VERSION ""

NS_ :

BS_:
BU_: GW EPS IBCU mADC BDC
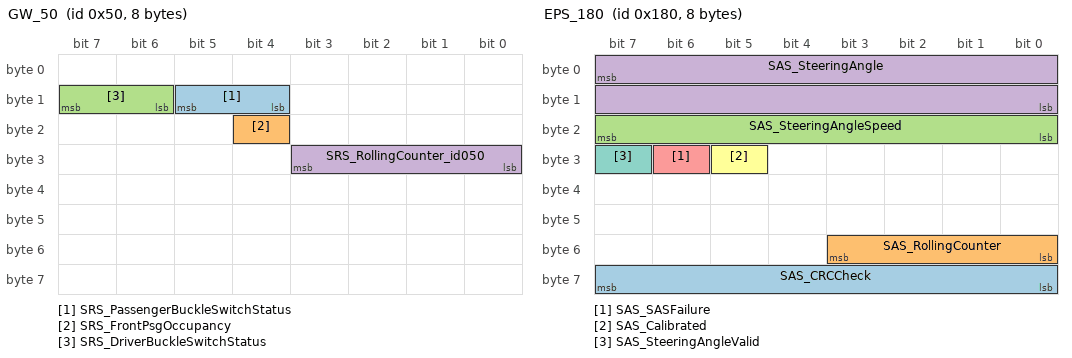
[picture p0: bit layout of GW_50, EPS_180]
BO_ 80 GW_50: 8 GW
 SG_ SRS_PassengerBuckleSwitchStatus : 13|2@0+ (1.0000000000,0.0000000000) [0.0000000000|3.0000000000] ""  EPB,VMC,IBCU
 SG_ SRS_FrontPsgOccupancy : 20|1@0+ (1.0000000000,0.0000000000) [0.0000000000|1.0000000000] ""  IBCU
 SG_ SRS_DriverBuckleSwitchStatus : 15|2@0+ (1.0000000000,0.0000000000) [0.0000000000|3.0000000000] ""  EPBi,IBCU,EPB,RBM,VMC
 SG_ SRS_RollingCounter_id050 : 27|4@0+ (1.0000000000,0.0000000000) [0.0000000000|15.0000000000] ""  EPBi,IBCU,EPB,RBM,VMC

BO_ 384 EPS_180: 8 EPS
 SG_ SAS_CRCCheck : 63|8@0+ (1.0000000000,0.0000000000) [0.0000000000|255.0000000000] ""  EPBi,IBCU,GW,VMC
 SG_ SAS_RollingCounter : 51|4@0+ (1.0000000000,0.0000000000) [0.0000000000|15.0000000000] ""  EPBi,IBCU,GW,VMC
 SG_ SAS_SteeringAngleSpeed : 23|8@0+ (4.0000000000,0.0000000000) [0.0000000000|1016.0000000000] "deg/s"  EPBi,IBCU,GW,VMC
 SG_ SAS_SteeringAngle : 7|16@0- (0.1000000000,0.0000000000) [-780.0000000000|780.0000000000] "degree"  EPBi,IBCU,GW,VMC,BDC
 SG_ SAS_SASFailure : 30|1@0+ (1.0000000000,0.0000000000) [0.0000000000|1.0000000000] ""  EPBi,IBCU,GW
 SG_ SAS_Calibrated : 29|1@0+ (1.0000000000,0.0000000000) [0.0000000000|1.0000000000] ""  EPBi,IBCU,GW,VMC
 SG_ SAS_SteeringAngleValid : 31|1@0+ (1.0000000000,0.0000000000) [0.0000000000|1.0000000000] ""  EPBi,IBCU,GW,VMC

BO_ 997 GW_3E5: 8 GW

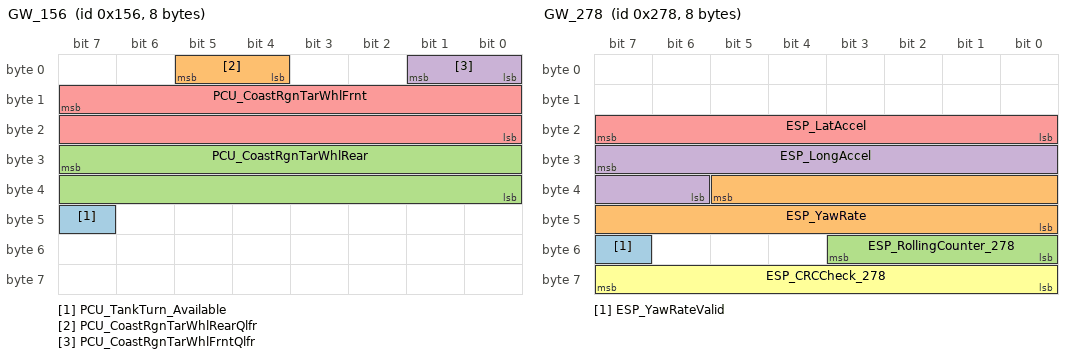
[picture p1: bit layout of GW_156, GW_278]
BO_ 342 GW_156: 8 GW
 SG_ PCU_TankTurn_Available : 47|1@0+ (1.0000000000,0.0000000000) [0.0000000000|1.0000000000] ""  IBCU
 SG_ PCU_CoastRgnTarWhlRearQlfr : 5|2@0+ (1.0000000000,0.0000000000) [0.0000000000|2.0000000000] ""  IBCU
 SG_ PCU_CoastRgnTarWhlRear : 31|16@0+ (1.0000000000,-32768.0000000000) [-32768.0000000000|32767.0000000000] "Nm"  IBCU
 SG_ PCU_CoastRgnTarWhlFrntQlfr : 1|2@0+ (1.0000000000,0.0000000000) [0.0000000000|2.0000000000] "-"  IBCU
 SG_ PCU_CoastRgnTarWhlFrnt : 15|16@0+ (1.0000000000,-32768.0000000000) [-32768.0000000000|32767.0000000000] "Nm"  IBCU

BO_ 580 GW_244: 64 GW
 SG_ ACC_AEBSpeedDropLevel : 162|2@0+ (1.0000000000,0.0000000000) [0.0000000000|3.0000000000] ""  IBCU,EPBi
 SG_ ADS__RollingCounter_244 : 427|4@0+ (1.0000000000,0.0000000000) [0.0000000000|15.0000000000] ""  EPS,EPBi,EPB,IBCU,VMC
 SG_ ADS_CRCCheck_244 : 439|16@0+ (1.0000000000,0.0000000000) [0.0000000000|65535.0000000000] ""  EPS,EPBi,EPB,IBCU,VMC
 SG_ ADS_Authernticator_244 : 463|56@0+ (1.0000000000,0.0000000000) [0.0000000000|0.0000000000] ""  IBCU
 SG_ ADS_ResetFlag_244 : 449|2@0+ (1.0000000000,0.0000000000) [0.0000000000|3.0000000000] ""  IBCU
 SG_ ADS_MesssageCounter_244 : 455|6@0+ (1.0000000000,0.0000000000) [0.0000000000|63.0000000000] ""  IBCU
 SG_ ACC_CRCCheck_25E : 127|8@0+ (1.0000000000,0.0000000000) [0.0000000000|255.0000000000] ""  EPBi,IBCU,RBM
 SG_ ACC_RollingCounter_25E : 115|4@0+ (1.0000000000,0.0000000000) [0.0000000000|15.0000000000] ""  EPBi,IBCU,RBM
 SG_ ACC_AEBCtrlType : 104|4@0+ (1.0000000000,0.0000000000) [0.0000000000|15.0000000000] ""  EPBi,IBCU
 SG_ ACC_AEBVehilceHoldReq : 90|1@0+ (1.0000000000,0.0000000000) [0.0000000000|1.0000000000] ""  EPBi,IBCU
 SG_ ACC_FCWActive : 93|1@0+ (1.0000000000,0.0000000000) [0.0000000000|1.0000000000] ""  IBCU,RBM
 SG_ ACC_PrefillActive : 94|1@0+ (1.0000000000,0.0000000000) [0.0000000000|1.0000000000] ""  EPBi,IBCU
 SG_ ACC_AWBActive : 95|1@0+ (1.0000000000,0.0000000000) [0.0000000000|1.0000000000] ""  EPBi,IBCU
 SG_ ACC_AWBlevel : 83|4@0+ (1.0000000000,0.0000000000) [0.0000000000|15.0000000000] ""  EPBi,IBCU
 SG_ ACC_ABAActive : 84|1@0+ (1.0000000000,0.0000000000) [0.0000000000|1.0000000000] ""  EPBi,IBCU
 SG_ ACC_ABAlevel : 86|2@0+ (1.0000000000,0.0000000000) [0.0000000000|3.0000000000] ""  EPBi,IBCU
 SG_ ACC_AEBActive : 87|1@0+ (1.0000000000,0.0000000000) [0.0000000000|1.0000000000] ""  EPBi,IBCU,RBM,VMC
 SG_ ACC_AEBTargetDeceleration : 71|16@0+ (0.0005000000,-16.0000000000) [-16.0000000000|16.0000000000] "m/s2"  EPBi,IBCU
 SG_ ACC_CRCCheck_24E : 63|8@0+ (1.0000000000,0.0000000000) [0.0000000000|255.0000000000] ""  EPBi,IBCU,RBM
 SG_ ACC_RollingCounter_24E : 51|4@0+ (1.0000000000,0.0000000000) [0.0000000000|15.0000000000] ""  EPBi,IBCU,RBM
 SG_ ACC_Driveoff_Request : 55|1@0+ (1.0000000000,0.0000000000) [0.0000000000|1.0000000000] ""  EPBi,IBCU,RBM
 SG_ ACC_ACCMode : 54|3@0+ (1.0000000000,0.0000000000) [0.0000000000|7.0000000000] ""  EPBi,IBCU,EPB,RBM,VMC
 SG_ ACC_CDDActive : 44|1@0+ (1.0000000000,0.0000000000) [0.0000000000|1.0000000000] ""  EPBi,IBCU,RBM
 SG_ ACC_EngineStartStopRequest : 41|2@0+ (1.0000000000,0.0000000000) [0.0000000000|3.0000000000] ""  IBCU,RBM
 SG_ ACC_DecToStop : 31|1@0+ (1.0000000000,0.0000000000) [0.0000000000|1.0000000000] ""  EPBi,IBCU,RBM
 SG_ ACC_ACCTargetAcceleration : 7|8@0+ (0.0500000000,-10.0000000000) [-10.0000000000|2.7500000000] "m/s2"  EPBi,IBCU,RBM

BO_ 583 GW_247: 32 GW
 SG_ APA_PrecheckValid : 99|1@0+ (1.0000000000,0.0000000000) [0.0000000000|1.0000000000] ""  IBCU
 SG_ APA_Precheck : 96|1@0+ (1.0000000000,0.0000000000) [0.0000000000|1.0000000000] ""  IBCU
 SG_ APA_ESP_BrakeFunctionMode : 238|3@0+ (1.0000000000,0.0000000000) [0.0000000000|7.0000000000] ""  IBCU,EPB,EPBi
 SG_ APA_CRCCheck_247 : 247|16@0+ (1.0000000000,0.0000000000) [0.0000000000|65535.0000000000] ""  EPBi,EPB,IBCU,EPS
 SG_ APA_RollingCounter_247 : 235|4@0+ (1.0000000000,0.0000000000) [0.0000000000|15.0000000000] ""  EPBi,EPB,IBCU,EPS
 SG_ APA_IncreasePressureReq : 27|1@0+ (1.0000000000,0.0000000000) [0.0000000000|1.0000000000] ""  EPBi,IBCU
 SG_ APA_EmergenceBrake : 7|1@0+ (1.0000000000,0.0000000000) [0.0000000000|1.0000000000] ""  EPBi,IBCU
 SG_ APA_HSAHDforbidden : 92|1@0+ (1.0000000000,0.0000000000) [0.0000000000|1.0000000000] ""  EPBi,IBCU
 SG_ APA_ESPDecompressionModel : 98|1@0+ (1.0000000000,0.0000000000) [0.0000000000|1.0000000000] ""  EPBi,IBCU
 SG_ APA_PrefillReq : 104|1@0+ (1.0000000000,0.0000000000) [0.0000000000|1.0000000000] ""  EPBi,IBCU
 SG_ APA_LSCAction : 91|1@0+ (1.0000000000,0.0000000000) [0.0000000000|1.0000000000] ""  EPBi,IBCU,VMC
 SG_ APA_TargetAcceleration : 79|8@0+ (0.0500000000,-5.0000000000) [-5.0000000000|7.7500000000] "m/s2"  EPBi,IBCU
 SG_ APA_TargetAccelerationValid : 67|1@0+ (1.0000000000,0.0000000000) [0.0000000000|1.0000000000] "NA"  EPBi,IBCU
 SG_ APA_EPBrequestValid : 66|1@0+ (1.0000000000,0.0000000000) [0.0000000000|1.0000000000] ""  EPBi,EPB,IBCU,VMC
 SG_ APA_EPBrequest : 65|2@0+ (1.0000000000,0.0000000000) [0.0000000000|3.0000000000] ""  EPBi,EPB,IBCU,VMC

BO_ 632 GW_278: 8 GW
 SG_ ESP_YawRateValid : 55|1@0+ (1.0000000000,0.0000000000) [0.0000000000|1.0000000000] ""  EPBi,EPS,IBCU
 SG_ ESP_YawRate : 37|14@0+ (0.0100000000,-81.9100000000) [-81.9100000000|81.9100000000] "degree/s"  EPBi,EPS,IBCU
 SG_ ESP_RollingCounter_278 : 51|4@0+ (1.0000000000,0.0000000000) [0.0000000000|15.0000000000] ""  EPBi,EPS,IBCU
 SG_ ESP_LongAccel : 31|10@0+ (0.0312500000,-16.0000000000) [-16.0000000000|15.9062500000] "m/s2"  EPBi,IBCU,BDC
 SG_ ESP_LatAccel : 23|8@0+ (0.1000000000,-12.7000000000) [-12.7000000000|12.7000000000] "m/s2"  EPBi,EPS,IBCU
 SG_ ESP_CRCCheck_278 : 63|8@0+ (1.0000000000,0.0000000000) [0.0000000000|255.0000000000] ""  EPBi,EPS,IBCU

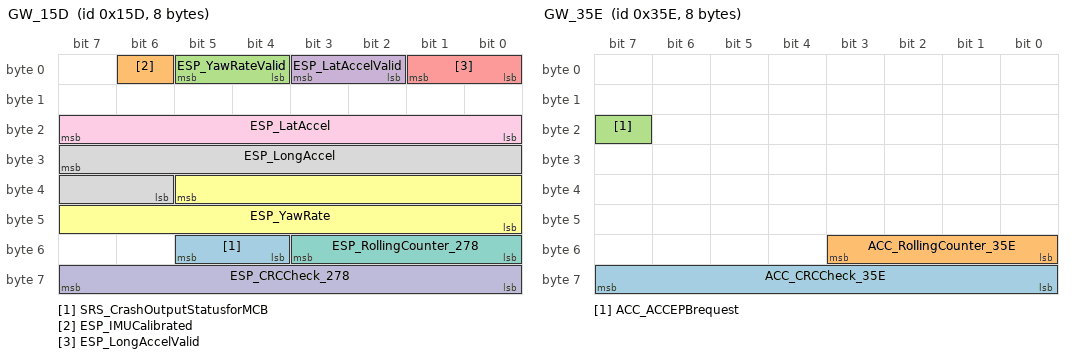
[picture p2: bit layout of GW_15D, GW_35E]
BO_ 349 GW_15D: 8 GW
 SG_ SRS_CrashOutputStatusforMCB : 53|2@0+ (1.0000000000,0.0000000000) [0.0000000000|3.0000000000] ""  EPBi,IBCU
 SG_ ESP_IMUCalibrated : 6|1@0+ (1.0000000000,0.0000000000) [0.0000000000|1.0000000000] ""  VMC,IBCU,RBM
 SG_ ESP_YawRateValid : 5|2@0+ (1.0000000000,0.0000000000) [0.0000000000|3.0000000000] ""  VMC,IBCU,EPB,RBM
 SG_ ESP_LatAccelValid : 3|2@0+ (1.0000000000,0.0000000000) [0.0000000000|3.0000000000] ""  IBCU,RBM,EPB,VMC
 SG_ ESP_LongAccelValid : 1|2@0+ (1.0000000000,0.0000000000) [0.0000000000|3.0000000000] ""  IBCU,RBM,EPB,VMC
 SG_ ESP_YawRate : 37|14@0+ (0.0100000000,-81.9100000000) [-81.9100000000|81.9100000000] "degree/s"  VMC,IBCU,EPB,RBM
 SG_ ESP_RollingCounter_278 : 51|4@0+ (1.0000000000,0.0000000000) [0.0000000000|15.0000000000] ""  IBCU,RBM,EPB,VMC
 SG_ ESP_LongAccel : 31|10@0+ (0.0312500000,-16.0000000000) [-16.0000000000|15.9062500000] "m/s2"  VMC,IBCU,EPB,RBM
 SG_ ESP_LatAccel : 23|8@0+ (0.1000000000,-12.7000000000) [-12.7000000000|12.7000000000] "m/s2"  VMC,IBCU,EPB,RBM
 SG_ ESP_CRCCheck_278 : 63|8@0+ (1.0000000000,0.0000000000) [0.0000000000|255.0000000000] ""  IBCU,RBM,EPB,VMC

BO_ 862 GW_35E: 8 GW
 SG_ ACC_CRCCheck_35E : 63|8@0+ (1.0000000000,0.0000000000) [0.0000000000|255.0000000000] ""  EPBi,IBCU,EPB,VMC,VMC2
 SG_ ACC_RollingCounter_35E : 51|4@0+ (1.0000000000,0.0000000000) [0.0000000000|15.0000000000] ""  EPBi,IBCU,EPB,VMC,VMC2
 SG_ ACC_ACCEPBrequest : 23|1@0+ (1.0000000000,0.0000000000) [0.0000000000|1.0000000000] ""  EPBi,IBCU,EPB,VMC,VMC2

BO_ 823 IBCU_337: 32 IBCU
 SG_ PowercycleIBCU : 215|16@0+ (1.0000000000,0.0000000000) [0.0000000000|65535.0000000000] "NA"  GW
 SG_ VoltageVR : 207|8@0+ (0.1000000000,0.0000000000) [0.0000000000|25.5000000000] "V"  GW
 SG_ VoltageUB : 199|8@0+ (0.1000000000,0.0000000000) [0.0000000000|25.5000000000] "V"  GW
 SG_ ESP_EpbReqAvl : 66|1@0+ (1.0000000000,0.0000000000) [0.0000000000|1.0000000000] ""  GW
 SG_ IBCU_BrkSysFltLamp : 15|2@0+ (1.0000000000,0.0000000000) [0.0000000000|3.0000000000] ""  RBM,GW
 SG_ ESC_ATSReqEnable : 69|1@0+ (1.0000000000,0.0000000000) [0.0000000000|1.0000000000] ""  GW
 SG_ ESC_ATSDrivingModeStatus : 76|3@0+ (1.0000000000,0.0000000000) [0.0000000000|6.0000000000] ""  GW
 SG_ ESP_RollerbenchEnable : 55|1@0+ (1.0000000000,0.0000000000) [0.0000000000|1.0000000000] ""  EPBi,GW
 SG_ ESP_WheelSpdSensorError : 145|1@0+ (1.0000000000,0.0000000000) [0.0000000000|1.0000000000] ""  EPBi,GW
 SG_ ESP_WheelSpdSensorEcuError : 144|1@0+ (1.0000000000,0.0000000000) [0.0000000000|1.0000000000] ""  EPBi,GW
 SG_ ESP_VGH_Status : 54|2@0+ (1.0000000000,0.0000000000) [0.0000000000|3.0000000000] ""  EPBi,GW
 SG_ ESP_VGH_Available : 52|1@0+ (1.0000000000,0.0000000000) [0.0000000000|1.0000000000] ""  EPBi,GW
 SG_ ESP_TPMSresetstatus : 85|3@0+ (1.0000000000,0.0000000000) [0.0000000000|7.0000000000] ""  EPBi,GW
 SG_ ESP_TPMS_WarningStatus : 86|1@0+ (1.0000000000,0.0000000000) [0.0000000000|1.0000000000] ""  EPBi,GW
 SG_ ESP_TPMS_MalfunctionStatus : 87|1@0+ (1.0000000000,0.0000000000) [0.0000000000|1.0000000000] ""  EPBi,GW
 SG_ ESP_RRWheelSpdSensorSigFailure : 146|1@0+ (1.0000000000,0.0000000000) [0.0000000000|1.0000000000] ""  EPBi,GW
 SG_ ESP_RRWheelSpdSensorFailure : 136|1@0+ (1.0000000000,0.0000000000) [0.0000000000|1.0000000000] ""  EPBi,GW
 SG_ ESP_RRWheelSpdSensor_ShtBAT : 148|1@0+ (1.0000000000,0.0000000000) [0.0000000000|1.0000000000] ""  EPBi,GW
 SG_ ESP_RRWheelSpdSensor_Open : 147|1@0+ (1.0000000000,0.0000000000) [0.0000000000|1.0000000000] ""  EPBi,GW
 SG_ ESP_RRWheelSpdSensor_GND : 149|1@0+ (1.0000000000,0.0000000000) [0.0000000000|1.0000000000] ""  EPBi,GW
 SG_ ESP_RollingCounter_508 : 179|4@0+ (1.0000000000,0.0000000000) [0.0000000000|15.0000000000] ""  EPBi,GW
 SG_ ESP_RLWheelSpdSensorSigFailure : 137|1@0+ (1.0000000000,0.0000000000) [0.0000000000|1.0000000000] ""  EPBi,GW
 SG_ ESP_RLWheelSpdSensorFailure : 141|1@0+ (1.0000000000,0.0000000000) [0.0000000000|1.0000000000] ""  EPBi,GW
 SG_ ESP_RLWheelSpdSensor_ShtBAT : 139|1@0+ (1.0000000000,0.0000000000) [0.0000000000|1.0000000000] ""  EPBi,GW
 SG_ ESP_RLWheelSpdSensor_Open : 138|1@0+ (1.0000000000,0.0000000000) [0.0000000000|1.0000000000] ""  EPBi,GW
 SG_ ESP_RLWheelSpdSensor_GND : 140|1@0+ (1.0000000000,0.0000000000) [0.0000000000|1.0000000000] ""  EPBi,GW
 SG_ ESP_RearRghtWheelStatus : 78|2@0+ (1.0000000000,0.0000000000) [0.0000000000|3.0000000000] ""  EPBi,GW
 SG_ ESP_RearLeftWheelStatus : 65|2@0+ (1.0000000000,0.0000000000) [0.0000000000|3.0000000000] ""  EPBi,GW
 SG_ EPBi_ResetSts : 82|3@0+ (1.0000000000,0.0000000000) [0.0000000000|7.0000000000] ""  EPBi,GW
 SG_ ESP_FRWheelSpdSensorSigFailure : 142|1@0+ (1.0000000000,0.0000000000) [0.0000000000|1.0000000000] ""  EPBi,GW
 SG_ ESP_FRWheelSpdSensorFailure : 130|1@0+ (1.0000000000,0.0000000000) [0.0000000000|1.0000000000] ""  EPBi,GW
 SG_ ESP_FRWheelSpdSensor_ShtBAT : 128|1@0+ (1.0000000000,0.0000000000) [0.0000000000|1.0000000000] ""  EPBi,GW
 SG_ ESP_FRWheelSpdSensor_Open : 143|1@0+ (1.0000000000,0.0000000000) [0.0000000000|1.0000000000] ""  EPBi,GW
 SG_ ESP_FRWheelSpdSensor_GND : 129|1@0+ (1.0000000000,0.0000000000) [0.0000000000|1.0000000000] ""  EPBi,GW
 SG_ ESP_FrontRightWheelStatus : 68|2@0+ (1.0000000000,0.0000000000) [0.0000000000|3.0000000000] ""  EPBi,GW
 SG_ ESP_FrontLeftWheelStatus : 71|2@0+ (1.0000000000,0.0000000000) [0.0000000000|3.0000000000] ""  EPBi,GW
 SG_ ESP_FLWheelSpdSensorSigFailure : 131|1@0+ (1.0000000000,0.0000000000) [0.0000000000|1.0000000000] ""  EPBi,GW
 SG_ ESP_FLWheelSpdSensorFailure : 135|1@0+ (1.0000000000,0.0000000000) [0.0000000000|1.0000000000] ""  EPBi,GW
 SG_ ESP_FLWheelSpdSensor_ShtBAT : 133|1@0+ (1.0000000000,0.0000000000) [0.0000000000|1.0000000000] ""  EPBi,GW
 SG_ ESP_FLWheelSpdSensor_Open : 132|1@0+ (1.0000000000,0.0000000000) [0.0000000000|1.0000000000] ""  EPBi,GW
 SG_ ESP_FLWheelSpdSensor_GND : 134|1@0+ (1.0000000000,0.0000000000) [0.0000000000|1.0000000000] ""  EPBi,GW
 SG_ ESP_CRCCheck_508 : 191|8@0+ (1.0000000000,0.0000000000) [0.0000000000|255.0000000000] ""  EPBi,GW
 SG_ IBCU_CST_FunctionSwitch : 27|2@0+ (1.0000000000,0.0000000000) [0.0000000000|3.0000000000] ""  GW
 SG_ ESP_AWD_ModeRequest : 30|3@0+ (1.0000000000,0.0000000000) [0.0000000000|7.0000000000] ""  EPBi,GW
 SG_ ESP_ATS_PtrotectMode : 31|1@0+ (1.0000000000,0.0000000000) [0.0000000000|1.0000000000] ""  EPBi,GW
 SG_ ESP_ATS_ATB_Failure : 16|1@0+ (1.0000000000,0.0000000000) [0.0000000000|1.0000000000] ""  EPBi,GW
 SG_ ESP_ATS_EPBi_Failure : 17|1@0+ (1.0000000000,0.0000000000) [0.0000000000|1.0000000000] ""  EPBi,GW
 SG_ ESP_ATS_AWD_Failure : 18|1@0+ (1.0000000000,0.0000000000) [0.0000000000|1.0000000000] ""  EPBi,GW
 SG_ ESP_ATS_TCU_Failure : 19|1@0+ (1.0000000000,0.0000000000) [0.0000000000|1.0000000000] ""  EPBi,GW
 SG_ ESP_ATS_EMS_Failure : 20|1@0+ (1.0000000000,0.0000000000) [0.0000000000|1.0000000000] ""  EPBi,GW
 SG_ EPB_CRCCheck_34F : 63|8@0+ (1.0000000000,0.0000000000) [0.0000000000|255.0000000000] ""  EPBi,GW
 SG_ EPB_RollingCounter_34F : 51|4@0+ (1.0000000000,0.0000000000) [0.0000000000|15.0000000000] ""  EPBi,GW
 SG_ ESC_ATSReqEnable : 21|1@0+ (1.0000000000,0.0000000000) [0.0000000000|1.0000000000] ""  EPBi,GW
 SG_ ESP_ATS_DriveModeRequest : 13|4@0+ (1.0000000000,0.0000000000) [0.0000000000|15.0000000000] ""  EPBi,GW
 SG_ ESC_ATSDrivingModeStatus : 9|4@0+ (1.0000000000,0.0000000000) [0.0000000000|15.0000000000] ""  EPBi,GW

BO_ 870 GW_366: 8 GW
 SG_ AC_EnvironmentalTemp : 23|8@0+ (0.5000000000,-40.0000000000) [-40.0000000000|87.0000000000] "degreeC"  EPBi,EPB,IBCU,VMC
 SG_ AC_EnvironmentalTempVD : 8|1@0+ (1.0000000000,0.0000000000) [0.0000000000|1.0000000000] ""  EPBi,IBCU

BO_ 1302 GW_516: 32 GW
 SG_ HU_RollerbenchSetStaus : 103|2@0+ (1.0000000000,0.0000000000) [0.0000000000|3.0000000000] ""  EPBi,IBCU
 SG_ HU_LocalTimeSystem : 111|2@0+ (1.0000000000,0.0000000000) [0.0000000000|3.0000000000] ""  EPS,EPBi,IBCU
 SG_ HU_LocalTimeSecond : 109|6@0+ (1.0000000000,0.0000000000) [0.0000000000|59.0000000000] "second"  EPS,EPBi,IBCU,EPB,VMC
 SG_ HU_LocalTimeMinute : 101|6@0+ (1.0000000000,0.0000000000) [0.0000000000|59.0000000000] "minute"  EPS,EPBi,IBCU,EPB,VMC
 SG_ HU_LocalTimeHour : 92|5@0+ (1.0000000000,0.0000000000) [0.0000000000|23.0000000000] "hour"  EPS,EPBi,IBCU,EPB,VMC
 SG_ HU_LocalTimeDate : 84|5@0+ (1.0000000000,0.0000000000) [1.0000000000|31.0000000000] "day"  EPS,EPBi,IBCU,EPB,VMC
 SG_ HU_LocalTimeYear : 119|8@0+ (1.0000000000,2013.0000000000) [2013.0000000000|2268.0000000000] "year"  EPS,EPBi,IBCU,EPB,VMC
 SG_ HU_LocalTimeMonth : 75|4@0+ (1.0000000000,0.0000000000) [1.0000000000|12.0000000000] "month"  EPS,EPBi,IBCU,EPB,VMC
 SG_ HU_LocalTimeValid : 71|1@0+ (1.0000000000,0.0000000000) [0.0000000000|1.0000000000] ""  EPS,EPBi,IBCU,EPB,VMC

BO_ 1328 GW_530: 8 GW
 SG_ IP_TotalOdometer : 23|24@0+ (0.1000000000,0.0000000000) [0.0000000000|999999.0000000000] "Km"  EPBi,EPB,IBCU
 SG_ IP_EngineOffTime : 7|16@0+ (1.0000000000,0.0000000000) [0.0000000000|65535.0000000000] "s"  EPBi,IBCU

BO_ 378 IBCU_17A: 64 IBCU
 SG_ IBCU_MCB_availalbe : 181|1@0+ (1.0000000000,0.0000000000) [0.0000000000|1.0000000000] ""  EPBi,GW
 SG_ IBCU_MCB_Active : 182|1@0+ (1.0000000000,0.0000000000) [0.0000000000|1.0000000000] ""  EPBi,GW
 SG_ ESP_TankTurn_EngTorqIncRearActive : 457|1@0+ (1.0000000000,0.0000000000) [0.0000000000|1.0000000000] ""  GW
 SG_ ESP_TankTurn_TorqIncwhlRear : 456|15@0+ (1.0000000000,-5400.0000000000) [-5400.0000000000|12000.0000000000] "Nm"  GW
 SG_ ESP_TankTurn_EngTorqIncFrontActive : 277|1@0+ (1.0000000000,0.0000000000) [0.0000000000|1.0000000000] ""  GW
 SG_ ESP_TankTurn_TorqIncwhlFront : 276|15@0+ (1.0000000000,-5400.0000000000) [-5400.0000000000|12000.0000000000] "Nm"  GW
 SG_ IBCU_TankTurn_Status : 93|2@0+ (1.0000000000,0.0000000000) [0.0000000000|3.0000000000] ""  GW
 SG_ IBCU_BrkPedlTrvlDrvrVld : 473|2@0+ (1.0000000000,0.0000000000) [0.0000000000|2.0000000000] ""  GW
 SG_ IBCU_BrkPedlTrvlDrvr : 487|12@0+ (0.0156250000,-5.0000000000) [-5.0000000000|47.0000000000] "mm"  GW
 SG_ Wheel_Speed_RR_Data : 351|13@0+ (0.0562500000,0.0000000000) [0.0000000000|360.0000000000] "km/h"  GW
 SG_ Wheel_Speed_RL_Valid_Data : 354|1@0+ (1.0000000000,0.0000000000) [0.0000000000|1.0000000000] ""  GW
 SG_ Wheel_Speed_RL_Data : 353|13@0+ (0.0562500000,0.0000000000) [0.0000000000|360.0000000000] "km/h"  GW
 SG_ Wheel_Speed_RR_Valid_Data : 372|1@0+ (1.0000000000,0.0000000000) [0.0000000000|1.0000000000] ""  GW
 SG_ ESP_VDCActive : 245|1@0+ (1.0000000000,0.0000000000) [0.0000000000|1.0000000000] ""  GW
 SG_ ESP_TCSActive : 244|1@0+ (1.0000000000,0.0000000000) [0.0000000000|1.0000000000] ""  GW
 SG_ IBCU_EdcFrntMotTarSpd : 439|16@0+ (1.0000000000,-20000.0000000000) [-20000.0000000000|45535.0000000000] "rpm"  RBM,GW
 SG_ IBCU_EdcReMotTarSpd : 423|16@0+ (1.0000000000,-20000.0000000000) [-20000.0000000000|45535.0000000000] "rpm"  RBM,GW
 SG_ IBCU_TcsFrntMotTarSpd : 407|16@0+ (1.0000000000,-20000.0000000000) [-20000.0000000000|45535.0000000000] "rpm"  RBM,GW
 SG_ IBCU_TcsReMotTarSpd : 391|16@0+ (1.0000000000,-20000.0000000000) [-20000.0000000000|45535.0000000000] "rpm"  RBM,GW
 SG_ ESP_ElectricBoostFailStatus : 54|2@0+ (1.0000000000,0.0000000000) [0.0000000000|3.0000000000] ""  GW
 SG_ ESP_MbRegenTarWhlTotalQlfr : 293|2@0+ (1.0000000000,0.0000000000) [0.0000000000|3.0000000000] ""  GW
 SG_ ESP_MbRegenTarWhlTotal : 291|16@0+ (1.0000000000,-32768.0000000000) [-32768.0000000000|32767.0000000000] "Nm"  GW
 SG_ ESP_RollerbenchType : 80|3@0+ (1.0000000000,0.0000000000) [0.0000000000|7.0000000000] ""  EPBi,GW,VMC
 SG_ IBCU_BrakeFluid_Warning : 27|2@0+ (1.0000000000,0.0000000000) [0.0000000000|3.0000000000] ""  GW
 SG_ ESP_RollingCounter_17A : 491|4@0+ (1.0000000000,0.0000000000) [0.0000000000|15.0000000000] ""  EPBi,EPB,GW,EPS,VMC
 SG_ ESP_CRCCheck_17A : 503|16@0+ (1.0000000000,0.0000000000) [0.0000000000|65535.0000000000] ""  EPBi,EPB,GW,EPS,VMC
 SG_ ESP_VehicleSpeedValid2 : 271|2@0+ (1.0000000000,0.0000000000) [0.0000000000|2.0000000000] ""  GW
 SG_ ESP_VehicleSpeedValid : 37|1@0+ (1.0000000000,0.0000000000) [0.0000000000|1.0000000000] ""  EPBi,EPB,GW,EPS,VMC,TMS,BDC,VMC2,EPS2,EPBi2
 SG_ ESP_VehicleSpeed2 : 263|8@0+ (0.4000000000,0.0000000000) [0.0000000000|100.0000000000] "m/s"  GW
 SG_ ESP_VehicleSpeed : 36|13@0+ (0.0562500000,0.0000000000) [0.0000000000|360.0000000000] "km/h"  EPBi,EPB,GW,EPS,VMC,TMS,BDC,VMC2,EPS2,EPBi2
 SG_ ESP_TqDecSlowwhlRear : 215|15@0+ (1.0000000000,-5400.0000000000) [-5400.0000000000|12000.0000000000] "Nm"  GW
 SG_ ESP_TqDecSlowwhlFront : 136|15@0+ (1.0000000000,-5400.0000000000) [-5400.0000000000|12000.0000000000] "Nm"  GW
 SG_ ESP_TqDecFastwhlFront : 135|15@0+ (1.0000000000,-5400.0000000000) [-5400.0000000000|12000.0000000000] "Nm"  GW
 SG_ ESP_TorqIncwhlRear : 199|15@0+ (1.0000000000,-5400.0000000000) [-5400.0000000000|12000.0000000000] "Nm"  GW
 SG_ ESP_TorqIncwhlFront : 15|15@0+ (1.0000000000,-5400.0000000000) [-5400.0000000000|12000.0000000000] "Nm"  GW
 SG_ ESP_TCSFailStatus : 4|1@0+ (1.0000000000,0.0000000000) [0.0000000000|1.0000000000] ""  EPBi,GW,BDC
 SG_ ESP_RollingCounter_1DF : 371|4@0+ (1.0000000000,0.0000000000) [0.0000000000|15.0000000000] ""  GW
 SG_ ESP_RollingCounter_1C8 : 243|4@0+ (1.0000000000,0.0000000000) [0.0000000000|15.0000000000] ""  GW
 SG_ ESP_RollingCounter_1AC : 179|4@0+ (1.0000000000,0.0000000000) [0.0000000000|15.0000000000] ""  GW
 SG_ ESP_RollingCounter_197 : 115|4@0+ (1.0000000000,0.0000000000) [0.0000000000|15.0000000000] ""  EPBi,GW,BDC
 SG_ ESP_RollingCounter_187 : 51|4@0+ (1.0000000000,0.0000000000) [0.0000000000|15.0000000000] ""  EPBi,GW,BDC
 SG_ ESP_pMcVirtual_Q : 333|2@0+ (1.0000000000,0.0000000000) [0.0000000000|2.0000000000] ""  EPB,GW,VMC,VMC2
 SG_ ESP_pMcVirtual : 327|10@0+ (1.0000000000,0.0000000000) [0.0000000000|250.0000000000] "bar"  EPB,GW,VMC,VMC2
 SG_ ESP_MbRegenTarWhlRearQlfr : 247|2@0+ (1.0000000000,0.0000000000) [0.0000000000|2.0000000000] ""  GW
 SG_ ESP_MbRegenTarWhlRear : 231|16@0+ (1.0000000000,-32768.0000000000) [-32768.0000000000|0.0000000000] "Nm"  GW
 SG_ ESP_MbRegenTarWhlFrontQlfr : 168|2@0+ (1.0000000000,0.0000000000) [0.0000000000|2.0000000000] ""  GW
 SG_ ESP_MbRegenTarWhlFront : 152|16@0+ (1.0000000000,-32768.0000000000) [-32768.0000000000|32767.0000000000] "Nm"  GW
 SG_ ESP_GearHoldRequestValid : 5|1@0+ (1.0000000000,0.0000000000) [0.0000000000|1.0000000000] ""  EPBi,GW,BDC
 SG_ ESP_GearHoldRequest : 6|1@0+ (1.0000000000,0.0000000000) [0.0000000000|1.0000000000] ""  EPBi,GW,BDC
 SG_ ESP_ESPFunctionStatus : 1|1@0+ (1.0000000000,0.0000000000) [0.0000000000|1.0000000000] ""  EPBi,GW,VMC,BDC
 SG_ ESP_ESPActiveStatus : 0|1@0+ (1.0000000000,0.0000000000) [0.0000000000|1.0000000000] ""  EPBi,EPB,GW,VMC,BDC
 SG_ ESP_EngTorqIncRearActive : 200|1@0+ (1.0000000000,0.0000000000) [0.0000000000|1.0000000000] ""  GW
 SG_ ESP_EngTorqIncFrontActive : 38|1@0+ (1.0000000000,0.0000000000) [0.0000000000|1.0000000000] ""  GW
 SG_ ESP_EngTorqDecRearActive : 216|1@0+ (1.0000000000,0.0000000000) [0.0000000000|1.0000000000] ""  GW
 SG_ ESP_EngTorqDecFrontActive : 153|1@0+ (1.0000000000,0.0000000000) [0.0000000000|1.0000000000] ""  GW
 SG_ ESP_EngTorqDecActive : 39|1@0+ (1.0000000000,0.0000000000) [0.0000000000|1.0000000000] ""  EPBi,GW,BDC
 SG_ ESP_EBDFailStatus : 2|1@0+ (1.0000000000,0.0000000000) [0.0000000000|1.0000000000] ""  EPBi,GW,BDC
 SG_ ESP_CRCCheck_1DF : 383|8@0+ (1.0000000000,0.0000000000) [0.0000000000|255.0000000000] ""  GW
 SG_ ESP_CRCCheck_1C8 : 255|8@0+ (1.0000000000,0.0000000000) [0.0000000000|255.0000000000] ""  GW
 SG_ ESP_CRCCheck_1AC : 191|8@0+ (1.0000000000,0.0000000000) [0.0000000000|255.0000000000] ""  GW
 SG_ ESP_CRCCheck_197 : 127|8@0+ (1.0000000000,0.0000000000) [0.0000000000|255.0000000000] ""  EPBi,ESP,GW,BDC
 SG_ ESP_CRCCheck_187 : 63|8@0+ (1.0000000000,0.0000000000) [0.0000000000|255.0000000000] ""  EPBi,GW,BDC
 SG_ ESP_ABSFailStatus : 3|1@0+ (1.0000000000,0.0000000000) [0.0000000000|1.0000000000] ""  EPBi,GW,BDC
 SG_ ESP_ABSActiveStatus : 7|1@0+ (1.0000000000,0.0000000000) [0.0000000000|1.0000000000] ""  EPBi,GW,BDC
 SG_ EPBi_MILReq : 55|1@0+ (1.0000000000,0.0000000000) [0.0000000000|1.0000000000] ""  GW
 SG_ EPBi_ClearDiagnosticInfo : 25|2@0+ (1.0000000000,0.0000000000) [0.0000000000|3.0000000000] ""  GW
 SG_ EPB_ClutchSensor : 79|7@0+ (1.0000000000,0.0000000000) [0.0000000000|100.0000000000] "%"  EPBi,GW,BDC

BO_ 381 GW_17D: 64 GW
 SG_ PCU_MbRegenWhlTotalVld : 476|1@0+ (1.0000000000,0.0000000000) [0.0000000000|1.0000000000] ""  IBCU
 SG_ PCU_MbRegenWhlTotal : 475|16@0+ (1.0000000000,-32768.0000000000) [-32768.0000000000|32767.0000000000] "Nm"  IBCU
 SG_ PCU_ReWhlReqTqVld : 468|1@0+ (1.0000000000,0.0000000000) [0.0000000000|1.0000000000] ""  VMC,EPB,IBCU
 SG_ PCU_FrntWhlReqTqVld : 469|1@0+ (1.0000000000,0.0000000000) [0.0000000000|1.0000000000] ""  VMC,EPB,IBCU
 SG_ PCU_ReWhlActTqVld : 470|1@0+ (1.0000000000,0.0000000000) [0.0000000000|1.0000000000] ""  VMC,EPB,IBCU
 SG_ PCU_FrntWhlActTqVld : 471|1@0+ (1.0000000000,0.0000000000) [0.0000000000|1.0000000000] ""  VMC,IBCU,EPB,EPS
 SG_ PCU_MbRegenMaxRearWhlVld : 375|1@0+ (1.0000000000,0.0000000000) [0.0000000000|1.0000000000] ""  IBCU
 SG_ PCU_RollingCounter_1C4 : 435|4@0+ (1.0000000000,0.0000000000) [0.0000000000|15.0000000000] ""  IBCU
 SG_ PCU_RearMotSts : 408|1@0+ (1.0000000000,0.0000000000) [0.0000000000|1.0000000000] ""  IBCU
 SG_ PCU_PwrIndcdRealTqRearWhl : 391|15@0+ (1.0000000000,-5400.0000000000) [-5400.0000000000|12000.0000000000] "Nm"  IBCU,EPS,EPB,VMC
 SG_ PCU_PwrIndcdDrvrReqTqWhlRear : 392|15@0+ (1.0000000000,-5400.0000000000) [-5400.0000000000|12000.0000000000] "Nm"  IBCU,EPB,VMC
 SG_ PCU_ESPTqReqAvlRear : 409|1@0+ (1.0000000000,0.0000000000) [0.0000000000|1.0000000000] ""  IBCU
 SG_ PCU_CRCCheck_1C4 : 447|8@0+ (1.0000000000,0.0000000000) [0.0000000000|255.0000000000] ""  IBCU
 SG_ PCU_RollingCounter_1BE : 371|4@0+ (1.0000000000,0.0000000000) [0.0000000000|15.0000000000] ""  IBCU
 SG_ PCU_MbRegenWhlRear : 343|16@0+ (1.0000000000,-32768.0000000000) [-32768.0000000000|32767.0000000000] "Nm"  IBCU
 SG_ PCU_MbRegenMaxWhlTotal : 327|16@0+ (1.0000000000,-32768.0000000000) [-32768.0000000000|32767.0000000000] "Nm"  IBCU
 SG_ PCU_MbRegenMaxRearWhl : 359|16@0+ (1.0000000000,-32768.0000000000) [-32768.0000000000|32767.0000000000] "Nm"  IBCU
 SG_ PCU_CRCCheck_1BE : 383|8@0+ (1.0000000000,0.0000000000) [0.0000000000|255.0000000000] ""  IBCU
 SG_ PCU_PwrTrainSts : 311|2@0+ (1.0000000000,0.0000000000) [0.0000000000|3.0000000000] ""  EPS,EPB,VMC,IBCU
 SG_ PCU_BrkPedlSts : 291|2@0+ (1.0000000000,0.0000000000) [0.0000000000|3.0000000000] ""  IBCU,EPB,VMC
 SG_ PCU_RollingCounter_1A6 : 307|4@0+ (1.0000000000,0.0000000000) [0.0000000000|15.0000000000] ""  IBCU
 SG_ PCU_MbRegenWhlFront : 263|16@0+ (1.0000000000,-32768.0000000000) [-32768.0000000000|32767.0000000000] "Nm"  IBCU
 SG_ PCU_MbRegenMaxWhlQlfr : 293|2@0+ (1.0000000000,0.0000000000) [0.0000000000|2.0000000000] ""  IBCU
 SG_ PCU_MbRegenMaxFrontWhlVld : 294|1@0+ (1.0000000000,0.0000000000) [0.0000000000|1.0000000000] ""  IBCU
 SG_ PCU_MbRegenMaxFrontWhl : 279|16@0+ (1.0000000000,-32768.0000000000) [-32768.0000000000|32767.0000000000] "Nm"  IBCU
 SG_ PCU_CRCCheck_1A6 : 319|8@0+ (1.0000000000,0.0000000000) [0.0000000000|255.0000000000] ""  IBCU
 SG_ PCU_AccPedlVld : 288|1@0+ (1.0000000000,0.0000000000) [0.0000000000|1.0000000000] ""  IBCU,EPB,VMC
 SG_ PCU_AccPedl : 303|8@0+ (0.3920000000,0.0000000000) [0.0000000000|99.9600000000] "pct"  IBCU,EPB,VMC
 SG_ PCU_RollingCounter_211 : 243|4@0+ (1.0000000000,0.0000000000) [0.0000000000|15.0000000000] ""  IBCU
 SG_ PCU_RearMotStsVld : 236|1@0+ (1.0000000000,0.0000000000) [0.0000000000|1.0000000000] ""  IBCU
 SG_ PCU_PwrIndcdRealTqFrontWhl : 199|15@0+ (1.0000000000,-5400.0000000000) [-5400.0000000000|12000.0000000000] "Nm"  IBCU,EPS,EPB,VMC
 SG_ PCU_PwrIndcdDrvrReqTqWhlFront : 200|15@0+ (1.0000000000,-5400.0000000000) [-5400.0000000000|12000.0000000000] "Nm"  IBCU,EPB,VMC
 SG_ PCU_FrontMotStsVld : 239|1@0+ (1.0000000000,0.0000000000) [0.0000000000|1.0000000000] ""  IBCU
 SG_ PCU_FrontMotSts : 217|1@0+ (1.0000000000,0.0000000000) [0.0000000000|1.0000000000] ""  IBCU
 SG_ PCU_ESPTqReqAvlFront : 216|1@0+ (1.0000000000,0.0000000000) [0.0000000000|1.0000000000] ""  IBCU
 SG_ PCU_CRCCheck_211 : 255|8@0+ (1.0000000000,0.0000000000) [0.0000000000|255.0000000000] ""  IBCU
 SG_ PCU_TarGearReqValid : 111|1@0+ (1.0000000000,0.0000000000) [0.0000000000|1.0000000000] ""  IBCU
 SG_ PCU_TarGearReq : 99|4@0+ (1.0000000000,0.0000000000) [0.0000000000|15.0000000000] ""  IBCU
 SG_ PCU_RollingCounter_1C6 : 115|4@0+ (1.0000000000,0.0000000000) [0.0000000000|15.0000000000] ""  IBCU
 SG_ PCU_RealAccPedlVld : 79|1@0+ (1.0000000000,0.0000000000) [0.0000000000|1.0000000000] ""  IBCU,EPB,VMC
 SG_ PCU_RealAccPedl : 71|8@0+ (0.3920000000,0.0000000000) [0.0000000000|99.9600000000] "%"  IBCU,EPB,VMC
 SG_ PCU_CRCCheck_1C6 : 127|8@0+ (1.0000000000,0.0000000000) [0.0000000000|255.0000000000] ""  IBCU

BO_ 459 IBCU_1CB: 32 IBCU
 SG_ IBCU_ElectrodelessBrakeModeFeedBack : 215|8@0+ (1.0000000000,0.0000000000) [0.0000000000|255.0000000000] ""  GW
 SG_ IBCU_ESPTSMAvlSts : 68|1@0+ (1.0000000000,0.0000000000) [0.0000000000|1.0000000000] ""  GW
 SG_ IBCU_ESPTSMAct : 69|1@0+ (1.0000000000,0.0000000000) [0.0000000000|1.0000000000] ""  GW
 SG_ IBCU_EPBrequest : 238|2@0+ (1.0000000000,0.0000000000) [0.0000000000|3.0000000000] ""  EPB,VMC,GW
 SG_ IBCU_EPBrequestValid : 236|1@0+ (1.0000000000,0.0000000000) [0.0000000000|1.0000000000] ""  EPB,VMC,GW
 SG_ WhlPreLeReVld : 180|1@0+ (1.0000000000,0.0000000000) [0.0000000000|1.0000000000] ""  RBM,VMC,GW
 SG_ WhlPreRiReVld : 181|1@0+ (1.0000000000,0.0000000000) [0.0000000000|1.0000000000] ""  RBM,VMC,GW
 SG_ WhlPreLeFrntVld : 182|1@0+ (1.0000000000,0.0000000000) [0.0000000000|1.0000000000] ""  RBM,VMC,GW
 SG_ WhlPreRiFrntVld : 183|1@0+ (1.0000000000,0.0000000000) [0.0000000000|1.0000000000] ""  RBM,VMC,GW
 SG_ WheelPressureRearLeft_Model : 163|12@0+ (0.1000000000,0.0000000000) [0.0000000000|250.0000000000] "bar"  RBM,VMC,GW
 SG_ WheelPressureRearRight_Model : 159|12@0+ (0.1000000000,0.0000000000) [0.0000000000|250.0000000000] "bar"  RBM,VMC,GW
 SG_ WheelPressureFrontLeft_Model : 139|12@0+ (0.1000000000,0.0000000000) [0.0000000000|250.0000000000] "bar"  RBM,VMC,GW
 SG_ WheelPressureFrontRight_Model : 135|12@0+ (0.1000000000,0.0000000000) [0.0000000000|250.0000000000] "bar"  RBM,VMC,GW
 SG_ IBCU_BrkTqReqAvail : 100|1@0+ (1.0000000000,0.0000000000) [0.0000000000|1.0000000000] ""  RBM,GW
 SG_ IBCU_HydBrkActvTq : 199|16@0+ (1.0000000000,-32768.0000000000) [-32768.0000000000|32767.0000000000] "Nm"  RBM,GW
 SG_ IBCU_DrvrBrkReqTqVID : 92|1@0+ (1.0000000000,0.0000000000) [0.0000000000|1.0000000000] ""  RBM,GW
 SG_ IBCU_DrvrBrkReqTq : 99|16@0+ (1.0000000000,-32768.0000000000) [-32768.0000000000|32767.0000000000] "Nm"  RBM,GW
 SG_ IBCU_BrkReqTq : 67|16@0+ (1.0000000000,-32768.0000000000) [-32768.0000000000|32767.0000000000] "Nm"  RBM,GW
 SG_ IBCU_NBrkMode : 103|3@0+ (1.0000000000,0.0000000000) [0.0000000000|7.0000000000] ""  RBM,GW
 SG_ IBCU_System_Status : 7|3@0+ (1.0000000000,0.0000000000) [0.0000000000|7.0000000000] ""  RBM,GW
 SG_ IBCU_RollingCounter_1CB : 235|4@0+ (1.0000000000,0.0000000000) [0.0000000000|15.0000000000] ""  GW,ESP
 SG_ IBCU_CRCCheck_1CB : 247|16@0+ (1.0000000000,0.0000000000) [0.0000000000|65535.0000000000] ""  GW,ESP
 SG_ IBCU_CST_Status : 71|2@0+ (1.0000000000,0.0000000000) [0.0000000000|3.0000000000] ""  GW
 SG_ IBCU_sOutputRodDriver_Q : 18|2@0+ (1.0000000000,0.0000000000) [0.0000000000|2.0000000000] ""  GW
 SG_ IBCU_sOutputRodDriver : 14|12@0+ (0.0156250000,-5.0000000000) [-5.0000000000|47.0000000000] "mm"  GW
 SG_ IBCU_sOutputRodAct_Q : 29|2@0+ (1.0000000000,0.0000000000) [0.0000000000|3.0000000000] ""  GW
 SG_ IBCU_sOutputRodAct : 27|12@0+ (0.0156250000,-5.0000000000) [-5.0000000000|47.0000000000] "mm"  GW
 SG_ IBCU_RollingCounter_237 : 115|4@0+ (1.0000000000,0.0000000000) [0.0000000000|15.0000000000] ""  GW
 SG_ IBCU_RollingCounter_1CB : 51|4@0+ (1.0000000000,0.0000000000) [0.0000000000|15.0000000000] ""  GW
 SG_ IBCU_MILReq : 15|1@0+ (1.0000000000,0.0000000000) [0.0000000000|1.0000000000] ""  GW
 SG_ IBCU_ExtReqStatus : 16|2@0+ (1.0000000000,0.0000000000) [0.0000000000|2.0000000000] ""  GW
 SG_ IBCU_ExtReqPrio : 30|1@0+ (1.0000000000,0.0000000000) [0.0000000000|1.0000000000] ""  GW
 SG_ IBCU_eBESCCompatibilityIndex : 80|4@0+ (1.0000000000,0.0000000000) [0.0000000000|15.0000000000] ""  GW
 SG_ IBCU_eBDiagActive : 91|1@0+ (1.0000000000,0.0000000000) [0.0000000000|1.0000000000] ""  GW
 SG_ IBCU_CRCCheck_237 : 127|8@0+ (1.0000000000,0.0000000000) [0.0000000000|255.0000000000] ""  GW
 SG_ IBCU_CRCCheck_1CB : 63|8@0+ (1.0000000000,0.0000000000) [0.0000000000|255.0000000000] ""  GW,BDC
 SG_ IBCU_ClearDiagnosticInfo : 3|2@0+ (1.0000000000,0.0000000000) [0.0000000000|3.0000000000] ""  GW
 SG_ IBCU_BrakePedalApplied_Q : 89|2@0+ (1.0000000000,0.0000000000) [0.0000000000|2.0000000000] ""  GW
 SG_ IBCU_BrakePedalApplied : 90|1@0+ (1.0000000000,0.0000000000) [0.0000000000|1.0000000000] ""  GW
 SG_ IBCU_BrakeModeFeedBack : 1|2@0+ (1.0000000000,0.0000000000) [0.0000000000|2.0000000000] ""  GW
 SG_ IBCU_BrakeModeEnable : 4|1@0+ (1.0000000000,0.0000000000) [0.0000000000|1.0000000000] ""  GW

BO_ 523 IBCU_20B: 64 IBCU
 SG_ IBCU_Version : 423|8@0+ (1.0000000000,0.0000000000) [0.0000000000|255.0000000000] ""  GW
 SG_ IBCU_DMCIncTarSpd : 407|16@0+ (1.0000000000,0.0000000000) [0.0000000000|30000.0000000000] "rpm"  GW
 SG_ IBCU_DMCIncCtrlMod : 429|2@0+ (1.0000000000,0.0000000000) [0.0000000000|3.0000000000] ""  GW
 SG_ IBCU_DMCDecTarSpd : 391|16@0+ (1.0000000000,0.0000000000) [0.0000000000|30000.0000000000] "rpm"  GW
 SG_ IBCU_DMCDecCtrlMod : 431|2@0+ (1.0000000000,0.0000000000) [0.0000000000|3.0000000000] ""  GW
 SG_ IBCU_BDC_Status : 332|3@0+ (1.0000000000,0.0000000000) [0.0000000000|7.0000000000] ""  GW
 SG_ IBCU_BDCAvlblSts : 333|1@0+ (1.0000000000,0.0000000000) [0.0000000000|1.0000000000] ""  GW
 SG_ IBCU_iDCS_State : 341|3@0+ (1.0000000000,0.0000000000) [0.0000000000|7.0000000000] ""  GW
 SG_ IBCU_iDCSLevFd : 328|3@0+ (1.0000000000,0.0000000000) [0.0000000000|7.0000000000] ""  GW
 SG_ IBCU_iDCSAvlblSts : 329|1@0+ (1.0000000000,0.0000000000) [0.0000000000|1.0000000000] ""  GW
 SG_ ESP_CDD_Availablebysituaion : 338|1@0+ (1.0000000000,0.0000000000) [0.0000000000|1.0000000000] ""  EPBi,GW
 SG_ IBCUVLA : 475|16@0+ (0.0100000000,-32.0000000000) [-32.0000000000|49.9000000000] "m/s^2"  GW
 SG_ ESP_AEBSpeedDropActive : 181|2@0+ (1.0000000000,0.0000000000) [0.0000000000|3.0000000000] ""  EPBi,GW
 SG_ IBCU_TankTurn_EDLOpenSet : 287|1@0+ (1.0000000000,0.0000000000) [0.0000000000|1.0000000000] ""  GW
 SG_ IBCU_EBS_Status : 323|4@0+ (1.0000000000,0.0000000000) [0.0000000000|15.0000000000] ""  GW
 SG_ IBCU_TankTurn_Enable : 334|1@0+ (1.0000000000,0.0000000000) [0.0000000000|1.0000000000] ""  GW
 SG_ IBCU_TankTurn_Available : 335|1@0+ (1.0000000000,0.0000000000) [0.0000000000|1.0000000000] ""  GW
 SG_ ESP_VehicleStandstillVld : 286|1@0+ (1.0000000000,0.0000000000) [0.0000000000|1.0000000000] ""  GW
 SG_ IBCU_BrkPedlStsGbVld : 303|2@0+ (1.0000000000,0.0000000000) [0.0000000000|2.0000000000] ""  EPB,RBM,GW,VMC,VMC2
 SG_ IBCU_BrkPedoplStsGb : 295|8@0+ (1.0000000000,0.0000000000) [0.0000000000|255.0000000000] "%"  EPB,RBM,GW,VMC,VMC2
 SG_ ESP_EBDActive : 310|1@0+ (1.0000000000,0.0000000000) [0.0000000000|1.0000000000] ""  RBM,GW
 SG_ IBCU_DTCAvailable : 327|2@0+ (1.0000000000,0.0000000000) [0.0000000000|3.0000000000] ""  ESP,GW
 SG_ Wheel_Speed_FL_Pulse : 135|8@0+ (1.0000000000,0.0000000000) [0.0000000000|254.0000000000] ""  GW,EPS
 SG_ Wheel_Speed_FR_Pulse : 159|8@0+ (1.0000000000,0.0000000000) [0.0000000000|254.0000000000] ""  EPBi,GW,EPS
 SG_ ESP_MasCylBraPreByDriver : 353|12@0+ (0.1000000000,0.0000000000) [0.0000000000|250.0000000000] "Bar"  ESP,GW
 SG_ ESP_MasCylBraPreByDriverValid : 372|1@0+ (1.0000000000,0.0000000000) [0.0000000000|1.0000000000] ""  ESP,GW
 SG_ ESP_Vehicle_Speed_Reference : 103|13@0+ (0.0562500000,0.0000000000) [0.0000000000|360.0000000000] "km/h"  EPBi,GW
 SG_ IBCU_precheckStatus : 309|2@0+ (1.0000000000,0.0000000000) [0.0000000000|3.0000000000] ""  GW,BDC
 SG_ ESP_PrefillforAPA_Available : 280|1@0+ (1.0000000000,0.0000000000) [0.0000000000|1.0000000000] ""  GW
 SG_ ESP_PrefillforAPA_active : 281|1@0+ (1.0000000000,0.0000000000) [0.0000000000|1.0000000000] ""  GW
 SG_ IBCU_BrakeDiscHighTempWarning : 283|2@0+ (1.0000000000,0.0000000000) [0.0000000000|3.0000000000] ""  GW
 SG_ Wheel_SpeedPulseTimeStamp_FL : 167|16@0+ (0.0100000000,0.0000000000) [0.0000000000|655.3500000000] "ms"  EPBi,GW,EPS
 SG_ Wheel_SpeedPulseTimeStamp_FR : 143|16@0+ (0.0100000000,0.0000000000) [0.0000000000|655.3500000000] "ms"  EPBi,GW,EPS
 SG_ ESP_DTV_Available : 325|1@0+ (1.0000000000,0.0000000000) [0.0000000000|1.0000000000] ""  EPBi,ESP,GW
 SG_ ESP_DTV_Active : 324|1@0+ (1.0000000000,0.0000000000) [0.0000000000|1.0000000000] ""  EPBi,ESP,GW
 SG_ ESP_RollingCounter_20B : 491|4@0+ (1.0000000000,0.0000000000) [0.0000000000|15.0000000000] ""  EPBi,EPB,GW,ESP,EPS,VMC,BDC
 SG_ ESP_CRCCheck_20B : 503|16@0+ (1.0000000000,0.0000000000) [0.0000000000|65535.0000000000] ""  EPBi,EPB,GW,ESP,EPS,VMC,BDC
 SG_ Wheel_Speed_RR_Valid_Data : 71|1@0+ (1.0000000000,0.0000000000) [0.0000000000|1.0000000000] ""  EPBi,EPB,GW,EPS,VMC
 SG_ Wheel_Speed_RR_Pulse : 231|8@0+ (1.0000000000,0.0000000000) [0.0000000000|254.0000000000] ""  EPBi,EPB,GW,EPS,VMC
 SG_ Wheel_Speed_RR_Direction : 70|2@0+ (1.0000000000,0.0000000000) [0.0000000000|3.0000000000] ""  EPBi,EPB,GW,EPS,VMC,BDC
 SG_ Wheel_Speed_RR_Data : 68|13@0+ (0.0562500000,0.0000000000) [0.0000000000|360.0000000000] "km/h"  EPBi,EPB,GW,EPS,VMC,BDC
 SG_ Wheel_Speed_RL_Valid_Data : 87|1@0+ (1.0000000000,0.0000000000) [0.0000000000|1.0000000000] ""  EPBi,EPB,GW,EPS,VMC
 SG_ Wheel_Speed_RL_Pulse : 239|8@0+ (1.0000000000,0.0000000000) [0.0000000000|254.0000000000] ""  EPBi,EPB,GW,EPS,VMC
 SG_ Wheel_Speed_RL_Direction : 86|2@0+ (1.0000000000,0.0000000000) [0.0000000000|3.0000000000] ""  EPBi,EPB,GW,EPS,VMC,BDC
 SG_ Wheel_Speed_RL_Data : 84|13@0+ (0.0562500000,0.0000000000) [0.0000000000|360.0000000000] "km/h"  EPBi,EPB,GW,EPS,VMC,BDC
 SG_ Wheel_Speed_FR_Valid_Data : 7|1@0+ (1.0000000000,0.0000000000) [0.0000000000|1.0000000000] ""  EPBi,EPB,GW,EPS,VMC
 SG_ Wheel_Speed_FR_Pulse : 223|8@0+ (1.0000000000,0.0000000000) [0.0000000000|254.0000000000] ""  EPBi,EPB,GW,EPS,VMC
 SG_ Wheel_Speed_FR_Direction : 6|2@0+ (1.0000000000,0.0000000000) [0.0000000000|3.0000000000] ""  EPBi,EPB,GW,EPS,VMC,BDC
 SG_ Wheel_Speed_FR_Data : 4|13@0+ (0.0562500000,0.0000000000) [0.0000000000|360.0000000000] "km/h"  EPBi,EPB,GW,EPS,VMC,BDC
 SG_ Wheel_Speed_FL_Valid_Data : 23|1@0+ (1.0000000000,0.0000000000) [0.0000000000|1.0000000000] ""  EPBi,EPB,GW,EPS,VMC
 SG_ Wheel_Speed_FL_Pulse : 215|8@0+ (1.0000000000,0.0000000000) [0.0000000000|254.0000000000] ""  EPB,GW,EPS,VMC
 SG_ Wheel_Speed_FL_Direction : 22|2@0+ (1.0000000000,0.0000000000) [0.0000000000|3.0000000000] ""  EPBi,EPB,GW,EPS,VMC,BDC
 SG_ Wheel_Speed_FL_Data : 20|13@0+ (0.0562500000,0.0000000000) [0.0000000000|360.0000000000] "km/h"  EPBi,EPB,GW,EPS,VMC,BDC
 SG_ ESP_VehicleStandstill : 267|1@0+ (1.0000000000,0.0000000000) [0.0000000000|1.0000000000] ""  EPBi,GW,BDC
 SG_ ESP_VDCActive : 266|1@0+ (1.0000000000,0.0000000000) [0.0000000000|1.0000000000] ""  EPBi,EPB,GW,VMC
 SG_ ESP_UrgencyBrakeAlarm : 118|1@0+ (1.0000000000,0.0000000000) [0.0000000000|1.0000000000] ""  EPBi,GW
 SG_ ESP_TODTorqueMaxLimit : 47|12@0+ (1.0000000000,0.0000000000) [0.0000000000|4094.0000000000] "NM"  EPBi,GW
 SG_ ESP_TCSActive : 265|1@0+ (1.0000000000,0.0000000000) [0.0000000000|1.0000000000] ""  EPBi,EPB,GW,VMC
 SG_ ESP_RollingCounter_277 : 307|4@0+ (1.0000000000,0.0000000000) [0.0000000000|15.0000000000] ""  EPBi,GW
 SG_ ESP_RollingCounter_258 : 243|4@0+ (1.0000000000,0.0000000000) [0.0000000000|15.0000000000] ""  EPBi,GW
 SG_ ESP_RollingCounter_208 : 115|4@0+ (1.0000000000,0.0000000000) [0.0000000000|15.0000000000] ""  EPBi,GW
 SG_ ESP_RollingCounter_206 : 51|4@0+ (1.0000000000,0.0000000000) [0.0000000000|15.0000000000] ""  EPBi,GW
 SG_ ESP_QDCACC : 279|2@0+ (1.0000000000,0.0000000000) [0.0000000000|3.0000000000] ""  EPBi,GW
 SG_ ESP_PrefillAvailable : 259|1@0+ (1.0000000000,0.0000000000) [0.0000000000|1.0000000000] ""  EPBi,GW
 SG_ ESP_PrefillActive : 260|1@0+ (1.0000000000,0.0000000000) [0.0000000000|1.0000000000] ""  EPBi,GW
 SG_ ESP_OnlyABSActive : 264|1@0+ (1.0000000000,0.0000000000) [0.0000000000|1.0000000000] ""  EPBi,EPB,GW,VMC
 SG_ ESP_MasCylBrakePressureValid : 199|1@0+ (1.0000000000,0.0000000000) [0.0000000000|1.0000000000] ""  EPBi,EPB,GW,VMC,BDC
 SG_ ESP_MasCylBrakePressure : 195|12@0+ (0.1000000000,0.0000000000) [0.0000000000|250.0000000000] "Bar"  EPBi,EPB,GW,VMC,BDC
 SG_ ESP_IncreasePressureReqOK : 275|1@0+ (1.0000000000,0.0000000000) [0.0000000000|1.0000000000] "NA"  EPBi,GW
 SG_ ESP_HHC_Available : 245|1@0+ (1.0000000000,0.0000000000) [0.0000000000|1.0000000000] ""  EPBi,GW
 SG_ ESP_HHC_Active : 244|1@0+ (1.0000000000,0.0000000000) [0.0000000000|1.0000000000] ""  EPBi,GW
 SG_ ESP_HDC_STATUS : 274|2@0+ (1.0000000000,0.0000000000) [0.0000000000|3.0000000000] ""  EPBi,GW
 SG_ ESP_ECDAvailable : 116|1@0+ (1.0000000000,0.0000000000) [0.0000000000|1.0000000000] ""  EPBi,EPB,GW,VMC,VMC2
 SG_ ESP_ECDActive : 117|1@0+ (1.0000000000,0.0000000000) [0.0000000000|1.0000000000] ""  EPBi,EPB,GW,VMC,VMC2
 SG_ ESP_CRCCheck_277 : 319|8@0+ (1.0000000000,0.0000000000) [0.0000000000|255.0000000000] ""  EPBi,GW
 SG_ ESP_CRCCheck_258 : 255|8@0+ (1.0000000000,0.0000000000) [0.0000000000|255.0000000000] ""  EPBi,GW
 SG_ ESP_CRCCheck_208 : 127|8@0+ (1.0000000000,0.0000000000) [0.0000000000|255.0000000000] ""  EPBi,GW
 SG_ ESP_CRCCheck_206 : 63|8@0+ (1.0000000000,0.0000000000) [0.0000000000|255.0000000000] ""  EPBi,GW
 SG_ ESP_CDD_Available_APA : 276|1@0+ (1.0000000000,0.0000000000) [0.0000000000|1.0000000000] "NA"  EPBi,EPB,GW,VMC,VMC2,BDC
 SG_ ESP_CDD_Available : 268|1@0+ (1.0000000000,0.0000000000) [0.0000000000|1.0000000000] ""  EPBi,GW
 SG_ ESP_CDD_Active_APA : 277|1@0+ (1.0000000000,0.0000000000) [0.0000000000|1.0000000000] "NA"  EPBi,GW,BDC
 SG_ ESP_CDD_Active : 269|1@0+ (1.0000000000,0.0000000000) [0.0000000000|1.0000000000] ""  EPBi,GW
 SG_ ESP_BrakeOverHeatBrakeDiscTemp : 270|1@0+ (1.0000000000,0.0000000000) [0.0000000000|1.0000000000] ""  EPBi,GW
 SG_ ESP_BrakeLightOnRequest : 197|2@0+ (1.0000000000,0.0000000000) [0.0000000000|3.0000000000] ""  EPBi,GW
 SG_ ESP_BrakeForce : 263|1@0+ (1.0000000000,0.0000000000) [0.0000000000|1.0000000000] ""  EPBi,EPB,GW,VMC,BDC
 SG_ ESP_AWBavailable : 271|1@0+ (1.0000000000,0.0000000000) [0.0000000000|1.0000000000] ""  EPBi,GW
 SG_ ESP_AWBactive : 256|1@0+ (1.0000000000,0.0000000000) [0.0000000000|1.0000000000] ""  EPBi,GW
 SG_ ESP_AutoHoldStandby : 198|1@0+ (1.0000000000,0.0000000000) [0.0000000000|1.0000000000] ""  EPBi,GW
 SG_ ESP_AutoHoldAvailable : 246|1@0+ (1.0000000000,0.0000000000) [0.0000000000|1.0000000000] ""  EPBi,GW
 SG_ ESP_AutoHoldActive : 247|1@0+ (1.0000000000,0.0000000000) [0.0000000000|1.0000000000] ""  EPBi,GW
 SG_ ESP_AEBdecActive : 257|1@0+ (1.0000000000,0.0000000000) [0.0000000000|1.0000000000] ""  EPBi,GW
 SG_ ESP_AEBAvailable : 258|1@0+ (1.0000000000,0.0000000000) [0.0000000000|1.0000000000] ""  EPBi,GW
 SG_ ESP_ABAavailable : 261|1@0+ (1.0000000000,0.0000000000) [0.0000000000|1.0000000000] ""  EPBi,GW
 SG_ ESP_ABAactive : 262|1@0+ (1.0000000000,0.0000000000) [0.0000000000|1.0000000000] ""  EPBi,GW
 SG_ ABS_TODFastOpenRequest : 33|2@0+ (1.0000000000,0.0000000000) [0.0000000000|3.0000000000] ""  EPBi,GW

BO_ 650 GW_28A: 8 GW
 SG_ IP_HandBrakeSwitch : 13|1@0+ (1.0000000000,0.0000000000) [0.0000000000|1.0000000000] ""  EPBi,ESP,IBCU

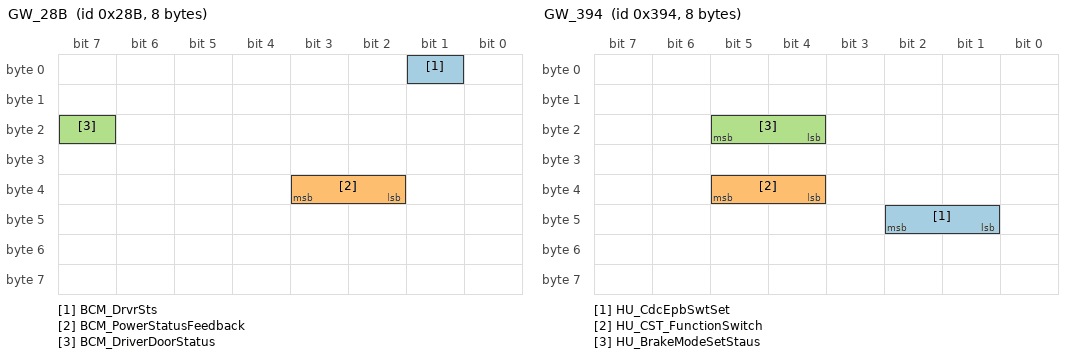
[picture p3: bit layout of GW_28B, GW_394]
BO_ 651 GW_28B: 8 GW
 SG_ BCM_DrvrSts : 1|1@0+ (1.0000000000,0.0000000000) [0.0000000000|1.0000000000] ""  IBCU,VMC,VMC2,EPB
 SG_ BCM_PowerStatusFeedback : 35|2@0+ (1.0000000000,0.0000000000) [0.0000000000|3.0000000000] ""  IBCU,EPBi,EPB,VMC,VMC2,EPBi2
 SG_ BCM_DriverDoorStatus : 23|1@0+ (1.0000000000,0.0000000000) [0.0000000000|1.0000000000] ""  ESP,EPBi,IBCU,EPB,VMC

BO_ 724 GW_2D4: 8 GW
 SG_ APA_ReleasePressureReq : 36|1@0+ (1.0000000000,0.0000000000) [0.0000000000|1.0000000000] ""  EPBi,IBCU

BO_ 721 GW_2D1: 8 GW
 SG_ BCM_ReversePosition : 29|1@0+ (1.0000000000,0.0000000000) [0.0000000000|1.0000000000] ""  EPBi,IBCU

BO_ 758 GW_2F6: 8 GW
 SG_ HU_IndirectTPMSReset : 3|1@0+ (1.0000000000,0.0000000000) [0.0000000000|1.0000000000] ""  ESP,EPBi,IBCU

BO_ 827 GW_33B: 64 GW
 SG_ PCU_SnowModelStatus : 325|2@0+ (1.0000000000,0.0000000000) [0.0000000000|3.0000000000] ""  IBCU
 SG_ PCU_OffRoadCrpTarSpd : 320|5@0+ (1.0000000000,0.0000000000) [0.0000000000|31.0000000000] "km/h"  IBCU
 SG_ PCU_OffRoadCrpSts : 331|3@0+ (1.0000000000,0.0000000000) [0.0000000000|7.0000000000] ""  IBCU
 SG_ PCU_TowingMode : 297|1@0+ (1.0000000000,0.0000000000) [0.0000000000|1.0000000000] ""  IBCU,EPB,VMC
 SG_ PCU_DrvModVld : 146|1@0+ (1.0000000000,0.0000000000) [0.0000000000|1.0000000000] ""  IBCU
 SG_ PCU_DrvMod : 149|3@0+ (1.0000000000,0.0000000000) [0.0000000000|7.0000000000] ""  IBCU
 SG_ PCU_RollingCounter_341 : 115|4@0+ (1.0000000000,0.0000000000) [0.0000000000|15.0000000000] ""  IBCU
 SG_ PCU_PwrTqWhMinTotal : 68|16@0+ (1.0000000000,-32768.0000000000) [-32768.0000000000|32767.0000000000] "Nm"  IBCU
 SG_ PCU_PwrTqWhMaxTotal : 84|16@0+ (1.0000000000,-32768.0000000000) [-32768.0000000000|32767.0000000000] "Nm"  IBCU
 SG_ PCU_CRCCheck_341 : 127|8@0+ (1.0000000000,0.0000000000) [0.0000000000|255.0000000000] ""  IBCU
 SG_ PCU_RollingCounter_311 : 51|4@0+ (1.0000000000,0.0000000000) [0.0000000000|15.0000000000] ""  IBCU
 SG_ PCU_PwrTqWhRearMin : 7|13@0+ (2.0000000000,-6000.0000000000) [-6000.0000000000|6000.0000000000] "Nm"  IBCU
 SG_ PCU_PwrTqWhRearMax : 10|13@0+ (2.0000000000,-6000.0000000000) [-6000.0000000000|6000.0000000000] "Nm"  IBCU
 SG_ PCU_PwrTqWhFrontMin : 29|13@0+ (2.0000000000,-6000.0000000000) [-6000.0000000000|6000.0000000000] "Nm"  IBCU
 SG_ PCU_PwrTqWhFrontMax : 32|13@0+ (2.0000000000,-6000.0000000000) [-6000.0000000000|6000.0000000000] "Nm"  IBCU
 SG_ PCU_CRCCheck_311 : 63|8@0+ (1.0000000000,0.0000000000) [0.0000000000|255.0000000000] ""  IBCU

BO_ 916 GW_394: 8 GW
 SG_ HU_CdcEpbSwtSet : 42|2@0+ (1.0000000000,0.0000000000) [0.0000000000|3.0000000000] ""  IBCU,EPB,VMC,VMC2,EPBi
 SG_ HU_CST_FunctionSwitch : 37|2@0+ (1.0000000000,0.0000000000) [0.0000000000|3.0000000000] ""  IBCU
 SG_ HU_BrakeModeSetStaus : 21|2@0+ (1.0000000000,0.0000000000) [0.0000000000|3.0000000000] ""  IBCU

BO_ 1021 GW_3FD: 8 GW
 SG_ BCM_PowerManageLevel : 8|3@0+ (1.0000000000,0.0000000000) [0.0000000000|7.0000000000] ""  EPBi,IBCU,RBM,EPS,EPS2

BO_ 1326 GW_52E: 8 GW
 SG_ IP_IndirectTPMSReset : 10|1@0+ (1.0000000000,0.0000000000) [0.0000000000|1.0000000000] ""  EPBi,IBCU

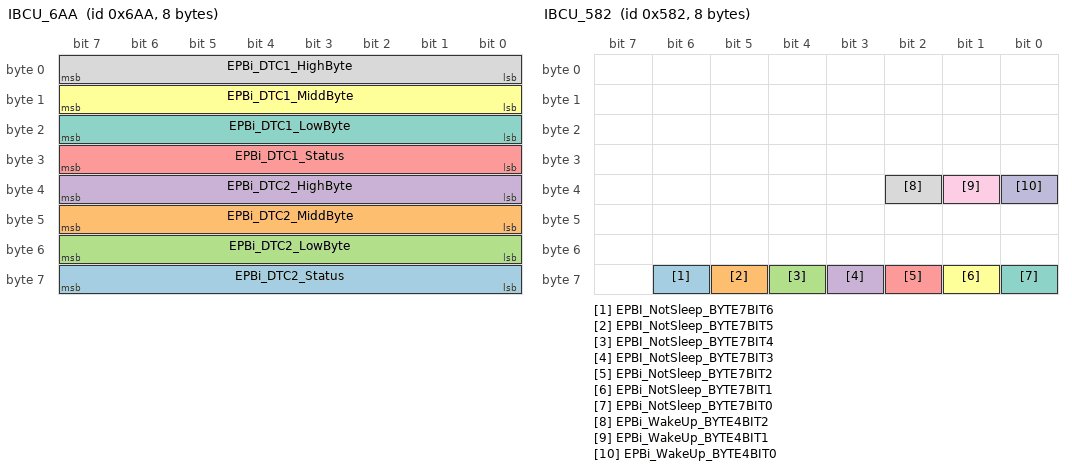
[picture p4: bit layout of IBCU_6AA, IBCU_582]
BO_ 1706 IBCU_6AA: 8 IBCU
 SG_ EPBi_DTC2_Status : 63|8@0+ (1.0000000000,0.0000000000) [0.0000000000|255.0000000000] ""  EPBi,GW
 SG_ EPBi_DTC2_MiddByte : 47|8@0+ (1.0000000000,0.0000000000) [0.0000000000|255.0000000000] ""  EPBi,GW
 SG_ EPBi_DTC2_LowByte : 55|8@0+ (1.0000000000,0.0000000000) [0.0000000000|255.0000000000] ""  EPBi,GW
 SG_ EPBi_DTC2_HighByte : 39|8@0+ (1.0000000000,0.0000000000) [0.0000000000|255.0000000000] ""  EPBi,GW
 SG_ EPBi_DTC1_Status : 31|8@0+ (1.0000000000,0.0000000000) [0.0000000000|255.0000000000] ""  EPBi,GW
 SG_ EPBi_DTC1_MiddByte : 15|8@0+ (1.0000000000,0.0000000000) [0.0000000000|255.0000000000] ""  EPBi,GW
 SG_ EPBi_DTC1_LowByte : 23|8@0+ (1.0000000000,0.0000000000) [0.0000000000|255.0000000000] ""  EPBi,GW
 SG_ EPBi_DTC1_HighByte : 7|8@0+ (1.0000000000,0.0000000000) [0.0000000000|255.0000000000] ""  EPBi,GW

BO_ 1056 mADC_420: 8 mADC
 SG_ NM_message420 : 0|1@0+ (1.0000000000,0.0000000000) [1.0000000000|1.0000000000] ""  EPBi,IBCU,GW,BDC

BO_ 1090 GW_442: 8 GW

BO_ 1410 IBCU_582: 8 IBCU
 SG_ EPBI_NotSleep_BYTE7BIT6 : 62|1@0+ (1.0000000000,0.0000000000) [0.0000000000|1.0000000000] ""  GW,EPBi
 SG_ EPBI_NotSleep_BYTE7BIT5 : 61|1@0+ (1.0000000000,0.0000000000) [0.0000000000|1.0000000000] ""  GW,EPBi
 SG_ EPBI_NotSleep_BYTE7BIT4 : 60|1@0+ (1.0000000000,0.0000000000) [0.0000000000|1.0000000000] ""  GW,EPBi
 SG_ EPBI_NotSleep_BYTE7BIT3 : 59|1@0+ (1.0000000000,0.0000000000) [0.0000000000|1.0000000000] ""  GW,EPBi
 SG_ EPBi_NotSleep_BYTE7BIT2 : 58|1@0+ (1.0000000000,0.0000000000) [0.0000000000|1.0000000000] ""  GW,EPBi
 SG_ EPBi_NotSleep_BYTE7BIT1 : 57|1@0+ (1.0000000000,0.0000000000) [0.0000000000|1.0000000000] ""  GW,EPBi
 SG_ EPBi_NotSleep_BYTE7BIT0 : 56|1@0+ (1.0000000000,0.0000000000) [0.0000000000|1.0000000000] ""  GW,EPBi
 SG_ EPBi_WakeUp_BYTE4BIT2 : 34|1@0+ (1.0000000000,0.0000000000) [0.0000000000|1.0000000000] ""  GW,EPBi
 SG_ EPBi_WakeUp_BYTE4BIT1 : 33|1@0+ (1.0000000000,0.0000000000) [0.0000000000|1.0000000000] ""  GW,EPBi
 SG_ EPBi_WakeUp_BYTE4BIT0 : 32|1@0+ (1.0000000000,0.0000000000) [0.0000000000|1.0000000000] ""  GW,EPBi

BO_ 817 GW_331: 8 GW

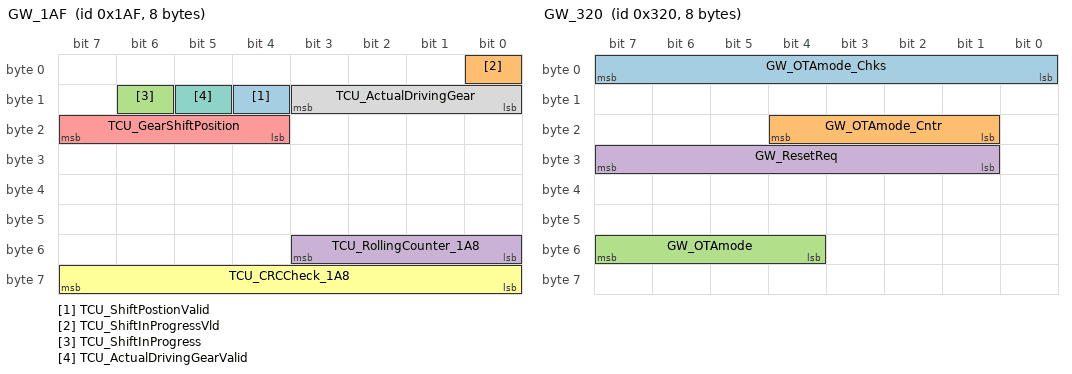
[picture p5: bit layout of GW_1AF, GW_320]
BO_ 431 GW_1AF: 8 GW
 SG_ TCU_ShiftPostionValid : 12|1@0+ (1.0000000000,0.0000000000) [0.0000000000|1.0000000000] ""  IBCU
 SG_ TCU_ShiftInProgressVld : 0|1@0+ (1.0000000000,0.0000000000) [0.0000000000|1.0000000000] ""  IBCU
 SG_ TCU_ShiftInProgress : 14|1@0+ (1.0000000000,0.0000000000) [0.0000000000|1.0000000000] ""  IBCU
 SG_ TCU_RollingCounter_1A8 : 51|4@0+ (1.0000000000,0.0000000000) [0.0000000000|15.0000000000] ""  IBCU,EPS
 SG_ TCU_GearShiftPosition : 23|4@0+ (1.0000000000,0.0000000000) [0.0000000000|15.0000000000] ""  VMC,IBCU,EPS,EPB
 SG_ TCU_CRCCheck_1A8 : 63|8@0+ (1.0000000000,0.0000000000) [0.0000000000|255.0000000000] ""  IBCU,EPS
 SG_ TCU_ActualDrivingGearValid : 13|1@0+ (1.0000000000,0.0000000000) [0.0000000000|1.0000000000] ""  IBCU,EPB,VMC
 SG_ TCU_ActualDrivingGear : 11|4@0+ (1.0000000000,0.0000000000) [0.0000000000|15.0000000000] ""  IBCU,EPB,VMC

BO_ 800 GW_320: 8 GW
 SG_ GW_OTAmode_Chks : 7|8@0+ (1.0000000000,0.0000000000) [0.0000000000|255.0000000000] ""  EPBi,IBCU,EPB,RBM,EPS,EPS2,OTA,VMC,VMC2
 SG_ GW_OTAmode_Cntr : 20|4@0+ (1.0000000000,0.0000000000) [0.0000000000|15.0000000000] ""  EPBi,IBCU,EPB,RBM,EPS,EPS2,OTA,VMC,VMC2
 SG_ GW_OTAmode : 55|4@0+ (1.0000000000,0.0000000000) [0.0000000000|15.0000000000] ""  EPBi,IBCU,EPB,RBM,EPS,EPS2,OTA,VMC,VMC2
 SG_ GW_ResetReq : 31|7@0+ (1.0000000000,0.0000000000) [0.0000000000|127.0000000000] ""  EPBi,IBCU,RBM,EPS,EPS2,VMC,VMC2,EPB,EPBi2

BO_ 1563 IBCU_61B: 8 IBCU
 SG_ KeyLearn_Authernticator_61B : 39|32@0+ (1.0000000000,0.0000000000) [1.0000000000|4294967296.0000000000] ""  GW,EPBi
 SG_ KeyLearn_Random_61B : 7|32@0+ (1.0000000000,0.0000000000) [1.0000000000|4294967296.0000000000] ""  GW,EPBi

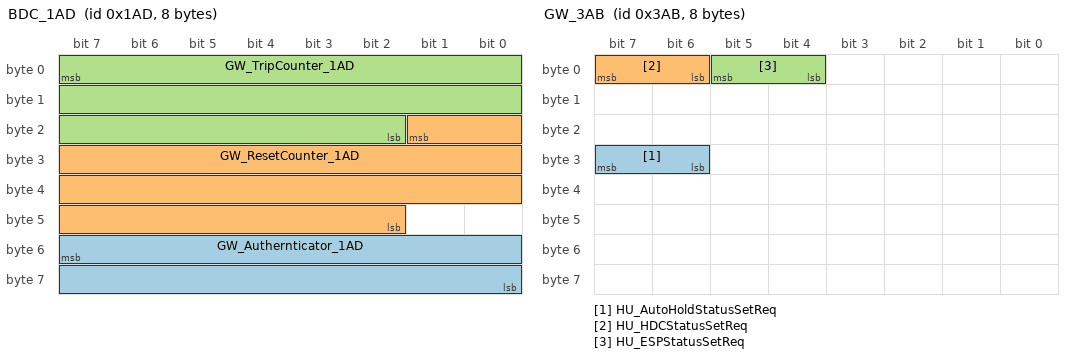
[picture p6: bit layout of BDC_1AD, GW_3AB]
BO_ 429 BDC_1AD: 8 BDC
 SG_ GW_Authernticator_1AD : 55|16@0+ (1.0000000000,0.0000000000) [0.0000000000|65535.0000000000] ""  GW,EPS,EPBi,IBCU
 SG_ GW_ResetCounter_1AD : 17|24@0+ (1.0000000000,0.0000000000) [0.0000000000|16777215.0000000000] ""  GW,EPS,EPBi,IBCU
 SG_ GW_TripCounter_1AD : 7|22@0+ (1.0000000000,0.0000000000) [0.0000000000|4194303.0000000000] ""  GW,EPS,EPBi,IBCU

BO_ 939 GW_3AB: 8 GW
 SG_ HU_AutoHoldStatusSetReq : 31|2@0+ (1.0000000000,0.0000000000) [0.0000000000|3.0000000000] ""  EPBi,IBCU
 SG_ HU_HDCStatusSetReq : 7|2@0+ (1.0000000000,0.0000000000) [0.0000000000|3.0000000000] ""  ESP,EPBi,IBCU
 SG_ HU_ESPStatusSetReq : 5|2@0+ (1.0000000000,0.0000000000) [0.0000000000|3.0000000000] ""  ESP,EPBi,IBCU

BO_ 393 IBCU_189: 8 IBCU
 SG_ IBCU_ReqSecOCSYNMSG : 1|2@0+ (1.0000000000,0.0000000000) [0.0000000000|3.0000000000] ""  EPBi,GW

BO_ 881 GW_371: 8 GW
 SG_ PCU_DrvMod2 : 31|3@0+ (1.0000000000,0.0000000000) [0.0000000000|7.0000000000] ""  IBCU,VMC
 SG_ PCU_SpecialModeSetFB : 25|3@0+ (1.0000000000,0.0000000000) [0.0000000000|7.0000000000] ""  IBCU

BO_ 394 GW_18A: 8 GW
 SG_ TCU_ParkingRequest : 53|2@0+ (1.0000000000,0.0000000000) [0.0000000000|3.0000000000] ""  IBCU,EPB,VMC,VMC2

BO_ 266 IBCU_10A: 8 IBCU
 SG_ EPB_BackupCapability : 44|2@0+ (1.0000000000,0.0000000000) [0.0000000000|3.0000000000] ""  EPB,EPBi,RBM,VMC2,VMC,GW
 SG_ EPB_ClampForce_Secondary : 42|5@0+ (1.0000000000,0.0000000000) [0.0000000000|31.0000000000] ""  EPB,EPBi,RBM,VMC2,VMC,GW
 SG_ EPB_FailStatus_Secondary : 25|2@0+ (1.0000000000,0.0000000000) [0.0000000000|3.0000000000] ""  EPB,EPBi,RBM,VMC2,VMC,GW
 SG_ EPB_Status_Secondary : 47|3@0+ (1.0000000000,0.0000000000) [0.0000000000|7.0000000000] ""  EPB,EPBi,RBM,VMC2,VMC,GW
 SG_ EPB_RollingCounter_10A : 51|4@0+ (1.0000000000,0.0000000000) [0.0000000000|15.0000000000] ""  EPB,EPBi,VMC,GW,VMC2
 SG_ EPB_CRCCheck_10A : 63|8@0+ (1.0000000000,0.0000000000) [0.0000000000|255.0000000000] ""  EPB,EPBi,VMC,GW,VMC2
 SG_ EpbCdpReq : 26|1@0+ (1.0000000000,0.0000000000) [0.0000000000|1.0000000000] ""  EPB,EPBi,VMC,GW
 SG_ EPB_EAR_Available : 27|1@0+ (1.0000000000,0.0000000000) [0.0000000000|1.0000000000] ""  EPB,EPBi,VMC,GW
 SG_ EPB_Status_Priamary : 1|3@0+ (1.0000000000,0.0000000000) [0.0000000000|7.0000000000] ""  EPB,EPBi,VMC,GW
 SG_ EPB_FailStatus_Primary : 5|2@0+ (1.0000000000,0.0000000000) [0.0000000000|3.0000000000] ""  EPB,EPBi,VMC,GW
 SG_ ESP_RWU_ParkingAvailForACC : 29|1@0+ (1.0000000000,0.0000000000) [0.0000000000|1.0000000000] ""  EPB,EPBi,VMC,GW
 SG_ ESP_RWU_ParkingActiveForACC : 30|1@0+ (1.0000000000,0.0000000000) [0.0000000000|1.0000000000] ""  EPB,EPBi,VMC,GW
 SG_ EPB_TextDisplay : 10|4@0+ (1.0000000000,0.0000000000) [0.0000000000|15.0000000000] ""  EPB,EPBi,VMC,GW
 SG_ EPB_SwitchPositionValid : 31|1@0+ (1.0000000000,0.0000000000) [0.0000000000|1.0000000000] ""  EPB,EPBi,VMC,GW
 SG_ EPB_SwitchPosition : 17|2@0+ (1.0000000000,0.0000000000) [0.0000000000|3.0000000000] ""  EPB,EPBi,VMC,GW
 SG_ EPB_Status : 3|2@0+ (1.0000000000,0.0000000000) [0.0000000000|3.0000000000] ""  EPB,EPBi,VMC,GW,BDC
 SG_ EPB_FunctionLamp : 14|2@0+ (1.0000000000,0.0000000000) [0.0000000000|3.0000000000] ""  EPB,EPBi,VMC,GW
 SG_ EPB_FailureLamp : 12|2@0+ (1.0000000000,0.0000000000) [0.0000000000|3.0000000000] ""  EPB,EPBi,VMC,GW
 SG_ EPB_FailStatus : 7|2@0+ (1.0000000000,0.0000000000) [0.0000000000|3.0000000000] ""  EPB,EPBi,VMC,GW,BDC
 SG_ EPB_APArequest_Available : 28|1@0+ (1.0000000000,0.0000000000) [0.0000000000|1.0000000000] ""  EPB,EPBi,VMC,GW,BDC
 SG_ EPB_AchievedClampForce : 22|5@0+ (1.0000000000,0.0000000000) [0.0000000000|31.0000000000] "KN"  EPB,EPBi,VMC,GW

BO_ 958 GW_3BE: 8 GW
 SG_ EDL_LockSts : 0|2@0+ (1.0000000000,0.0000000000) [0.0000000000|3.0000000000] ""  IBCU
 SG_ ATS_TargetDrivingMode : 22|3@0+ (1.0000000000,0.0000000000) [0.0000000000|6.0000000000] ""  VMC,IBCU

BO_ 815 GW_32F: 8 GW
 SG_ PCU_AccPedlE : 39|8@0+ (0.3900000000,0.0000000000) [0.0000000000|99.4500000000] "%"  IBCU
 SG_ PCU_AccPedlD : 31|8@0+ (0.3900000000,0.0000000000) [0.0000000000|99.4500000000] "%"  IBCU

BO_ 274 IBCU_112: 8 IBCU
 SG_ EPB_CRCCheck_112 : 63|8@0+ (1.0000000000,0.0000000000) [0.0000000000|255.0000000000] ""  VMC2,GW,EPB,EPBi
 SG_ EPB_RollingCounter_112 : 51|4@0+ (1.0000000000,0.0000000000) [0.0000000000|15.0000000000] ""  VMC2,GW,EPB,EPBi

BO_ 586 BDC_24A: 8 BDC
 SG_ ESL_DriverParkButtonFaultStatus : 21|2@0+ (1.0000000000,0.0000000000) [0.0000000000|3.0000000000] ""  GW,VMC,VMC2,EPB,IBCU,EPBi
 SG_ ESL_DriverParkRequest : 11|2@0+ (1.0000000000,0.0000000000) [0.0000000000|3.0000000000] ""  GW,VMC,VMC2,EPB,IBCU,EPBi

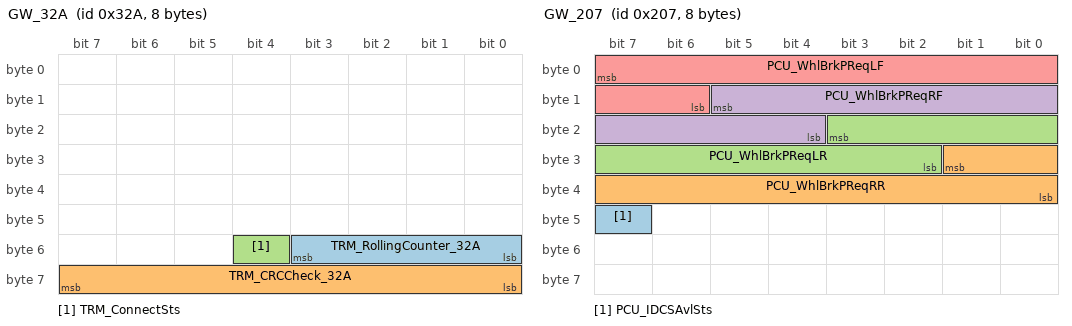
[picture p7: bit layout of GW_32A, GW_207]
BO_ 810 GW_32A: 8 GW
 SG_ TRM_RollingCounter_32A : 51|4@0+ (1.0000000000,0.0000000000) [0.0000000000|15.0000000000] ""  IBCU
 SG_ TRM_CRCCheck_32A : 63|8@0+ (1.0000000000,0.0000000000) [0.0000000000|255.0000000000] ""  IBCU
 SG_ TRM_ConnectSts : 52|1@0+ (1.0000000000,0.0000000000) [0.0000000000|1.0000000000] ""  IBCU,VMC

BO_ 268 GW_10C: 64 GW
 SG_ RMIPU_DMCTarTq : 375|16@0+ (1.0000000000,-30000.0000000000) [-30000.0000000000|35535.0000000000] "nm"  IBCU
 SG_ RMIPU_DMCCrtSts : 294|3@0+ (1.0000000000,0.0000000000) [0.0000000000|7.0000000000] ""  IBCU
 SG_ RMIPU_DMCVersion : 307|12@0+ (1.0000000000,0.0000000000) [0.0000000000|4095.0000000000] ""  IBCU
 SG_ TM1_WheelTqReal : 54|15@0+ (1.0000000000,-5400.0000000000) [-5400.0000000000|12000.0000000000] "Nm"  IBCU
 SG_ TM1_MotSpdVld : 103|1@0+ (1.0000000000,0.0000000000) [0.0000000000|1.0000000000] ""  IBCU,EPB
 SG_ TM1_MotSpd : 87|16@0+ (1.0000000000,-25000.0000000000) [-25000.0000000000|25000.0000000000] "1/min"  IBCU,EPB
 SG_ TM1_CRCCheck_10C : 503|16@0+ (1.0000000000,0.0000000000) [0.0000000000|65535.0000000000] ""  IBCU
 SG_ TM1_RollingCounter_10C : 491|4@0+ (1.0000000000,0.0000000000) [0.0000000000|15.0000000000] ""  IBCU
 SG_ TM1_MotTqRealVld : 34|1@0+ (1.0000000000,0.0000000000) [0.0000000000|1.0000000000] ""  IBCU
 SG_ TM1_OperMdl : 183|4@0+ (1.0000000000,0.0000000000) [0.0000000000|15.0000000000] ""  IBCU

BO_ 269 GW_10D: 64 GW
 SG_ TM2_WheelTqReal : 54|15@0+ (1.0000000000,-5400.0000000000) [-5400.0000000000|12000.0000000000] "Nm"  IBCU
 SG_ TM2_MotSpdVld : 103|1@0+ (1.0000000000,0.0000000000) [0.0000000000|1.0000000000] ""  IBCU
 SG_ TM2_MotSpd : 87|16@0+ (1.0000000000,-25000.0000000000) [-25000.0000000000|25000.0000000000] "1/min"  IBCU
 SG_ TM2_CRCCheck_10D : 503|16@0+ (1.0000000000,0.0000000000) [0.0000000000|65535.0000000000] ""  IBCU
 SG_ TM2_RollingCounter_10D : 491|4@0+ (1.0000000000,0.0000000000) [0.0000000000|15.0000000000] ""  IBCU
 SG_ TM2_OperMdl : 183|4@0+ (1.0000000000,0.0000000000) [0.0000000000|15.0000000000] ""  IBCU
 SG_ TM2_MotTqRealVld : 34|1@0+ (1.0000000000,0.0000000000) [0.0000000000|1.0000000000] ""  IBCU

BO_ 1341 GW_53D: 8 GW
 SG_ HU_Poweroff : 47|1@0+ (1.0000000000,0.0000000000) [0.0000000000|1.0000000000] ""  IBCU

BO_ 842 GW_34A: 8 GW
 SG_ HU_TankTurnStatusSetReq : 53|3@0+ (1.0000000000,0.0000000000) [0.0000000000|7.0000000000] ""  IBCU

BO_ 519 GW_207: 8 GW
 SG_ PCU_IDCSAvlSts : 47|1@0+ (1.0000000000,0.0000000000) [0.0000000000|1.0000000000] ""  IBCU
 SG_ PCU_WhlBrkPReqRR : 25|10@0+ (0.2500000000,0.0000000000) [0.0000000000|250.0000000000] "bar"  IBCU
 SG_ PCU_WhlBrkPReqLR : 19|10@0+ (0.2500000000,0.0000000000) [0.0000000000|250.0000000000] "bar"  IBCU
 SG_ PCU_WhlBrkPReqRF : 13|10@0+ (0.2500000000,0.0000000000) [0.0000000000|250.0000000000] "bar"  IBCU
 SG_ PCU_WhlBrkPReqLF : 7|10@0+ (0.2500000000,0.0000000000) [0.0000000000|250.0000000000] "bar"  IBCU

BO_ 2015 GW_7DF: 8 GW
 SG_ Diagnose_message7DF : 0|1@0+ (1.0000000000,0.0000000000) [1.0000000000|1.0000000000] ""  EPBi,IBCU,RBM,EPS,EPS1,EPS2,VMC,VMC2,EPB,ESC

BO_ 1920 GW_780: 64 GW
 SG_ Diagnose_message780 : 0|1@0+ (1.0000000000,0.0000000000) [1.0000000000|1.0000000000] ""  EPBi,IBCU

BO_ 1928 IBCU_788: 8 IBCU
 SG_ Diagnose_message788 : 0|1@0+ (1.0000000000,0.0000000000) [1.0000000000|1.0000000000] ""  EPBi,GW

BO_ 2021 GW_7E5: 64 GW
 SG_ Diagnose_message7E5 : 0|1@0+ (1.0000000000,0.0000000000) [1.0000000000|1.0000000000] ""  IBCU

BO_ 2029 IBCU_7ED: 8 IBCU
 SG_ Diagnose_message7ED : 0|1@0+ (1.0000000000,0.0000000000) [1.0000000000|1.0000000000] ""  GW

BO_ 977 GW_3D1: 8 GW
 SG_ PCU_CruiseCtrlSts : 10|3@0+ (1.0000000000,0.0000000000) [0.0000000000|3.0000000000] ""  IBCU

BO_ 574 IBCU_23E: 32 IBCU
 SG_ EspSysSts : 217|2@0+ (1.0000000000,0.0000000000) [0.0000000000|3.0000000000] "" Vector__XXX
 SG_ IBCU_VoltageInfo_BeforeUBV_Mosfet : 200|15@0+ (1.0000000000,0.0000000000) [0.0000000000|24000.0000000000] "mV" Vector__XXX
 SG_ IBCU_VoltageInfo_BeforeUBM_Mosfet : 199|15@0+ (1.0000000000,0.0000000000) [0.0000000000|24000.0000000000] "mV" Vector__XXX
 SG_ IBCU_RSS_ValVol : 162|15@0+ (1.0000000000,0.0000000000) [0.0000000000|24000.0000000000] "mV" Vector__XXX
 SG_ IBCU_SimulatorCutValve_Cur : 155|9@0+ (0.0156250000,0.0000000000) [0.0000000000|3.9900000000] "A" Vector__XXX
 SG_ IBCU_MasterCylinderCutValve2_Cur : 151|9@0+ (0.0156250000,0.0000000000) [0.0000000000|3.9900000000] "A" Vector__XXX
 SG_ IBCU_MasterCylinderCutValve1_Cur : 108|9@0+ (0.0156250000,0.0000000000) [0.0000000000|3.9900000000] "A" Vector__XXX
 SG_ IBCU_PressureCylinderCutValve2_Cur : 101|9@0+ (0.0156250000,0.0000000000) [0.0000000000|3.9900000000] "A" Vector__XXX
 SG_ IBCU_PressureCylinderCutValve1_Cur : 94|9@0+ (0.0156250000,0.0000000000) [0.0000000000|3.9900000000] "A" Vector__XXX
 SG_ IBCU_MotVol : 87|9@0+ (0.2500000000,0.0000000000) [0.0000000000|64.0000000000] "V" Vector__XXX
 SG_ IBCU_MotCtrlType : 55|4@0+ (1.0000000000,0.0000000000) [0.0000000000|15.0000000000] "" Vector__XXX
 SG_ IBCU_MotTorqAct : 143|8@0+ (0.0625000000,-8.0000000000) [-8.0000000000|7.0000000000] "Nm" Vector__XXX
 SG_ IBCU_MotTorqCmd : 135|8@0+ (0.0625000000,-8.0000000000) [-8.0000000000|7.0000000000] "Nm" Vector__XXX
 SG_ IBCU_SpeedAct : 71|16@0+ (0.1250000000,-4096.0000000000) [-4096.0000000000|4095.0000000000] "Nm" Vector__XXX
 SG_ IBCU_SpeedCmd : 23|16@0+ (0.1250000000,-4096.0000000000) [-4096.0000000000|4095.0000000000] "radps" Vector__XXX
 SG_ IBCU_PistonPos : 35|12@0+ (0.0625000000,-128.0000000000) [-128.0000000000|127.0000000000] "radps" Vector__XXX
 SG_ IBCU_IdleCtrlType : 158|3@0+ (1.0000000000,0.0000000000) [0.0000000000|7.0000000000] "mm" Vector__XXX
 SG_ IBCU_CtrlMode : 39|4@0+ (1.0000000000,0.0000000000) [0.0000000000|15.0000000000] "" Vector__XXX
 SG_ IBCU_PressureCmd : 7|16@0+ (0.0625000000,0.0000000000) [0.0000000000|4095.0000000000] "" Vector__XXX

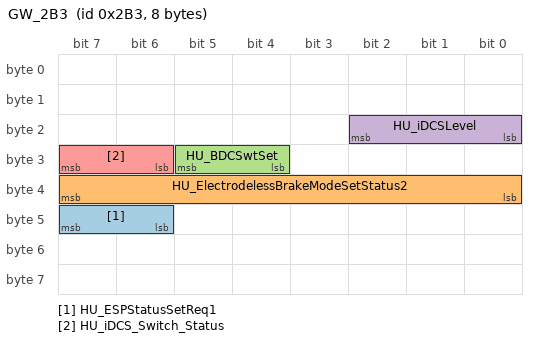
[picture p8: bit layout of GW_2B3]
BO_ 691 GW_2B3: 8 GW
 SG_ HU_ESPStatusSetReq1 : 47|2@0+ (1.0000000000,0.0000000000) [0.0000000000|7.0000000000] ""  IBCU
 SG_ HU_ElectrodelessBrakeModeSetStatus2 : 39|8@0+ (1.0000000000,0.0000000000) [0.0000000000|255.0000000000] ""  IBCU
 SG_ HU_BDCSwtSet : 29|2@0+ (1.0000000000,0.0000000000) [0.0000000000|3.0000000000] ""  IBCU
 SG_ HU_iDCSLevel : 18|3@0+ (1.0000000000,0.0000000000) [0.0000000000|7.0000000000] ""  IBCU
 SG_ HU_iDCS_Switch_Status : 31|2@0+ (1.0000000000,0.0000000000) [0.0000000000|3.0000000000] ""  IBCU

BO_ 773 GW_305: 8 GW
 SG_ BMS_PackSwitchSts : 51|3@0+ (1.0000000000,0.0000000000) [0.0000000000|7.0000000000] ""  IBCU

CM_ BO_ 80  " ";
CM_ SG_ 80 SRS_PassengerBuckleSwitchStatus  "For PDM is configured projects=
(if PDM is configured, logical detection with PDM is required)
0x0= [Buckled] or [Unbuckled and passenger not occupied]
0x1= [Unbuckle and passenger occupied]
0x2= Not Used
0x3= Not Used
 ";
CM_ SG_ 80 SRS_FrontPsgOccupancy  "¸±¼Ý×ùÒÎÖØÁ¿¼ì²â´«¸ÐÆ÷Óë¸±¼Ý°²È«´ø¿Û´®ÁªµÄ³µÐÍ²»·¢¸ÃÐÅºÅ ";
CM_ SG_ 80 SRS_DriverBuckleSwitchStatus  " ";
CM_ SG_ 80 SRS_RollingCounter_id050  "ACM½ÓÊÕÎªAT×¨ÓÃ ";

CM_ BO_ 384  "BDC¼¯³ÉÒ£¿Ø½ø³ö¹¦ÄÜÊ±½ÓÊÕ¸Ã±¨ÎÄ ";

CM_ BO_ 997  "Ô´¶ËHybridA_DPEU_134£¬1 ";

CM_ BO_ 342  " ";
CM_ SG_ 342 PCU_TankTurn_Available  " ";
CM_ SG_ 342 PCU_CoastRgnTarWhlRearQlfr  " ";

CM_ BO_ 580  " ";
CM_ SG_ 580 ACC_AEBSpeedDropLevel  " ";
CM_ SG_ 580 ADS_Authernticator_244  " ";
CM_ SG_ 580 ADS_ResetFlag_244  " ";
CM_ SG_ 580 ADS_MesssageCounter_244  " ";
CM_ SG_ 580 ACC_AEBCtrlType  " ";
CM_ SG_ 580 ACC_CRCCheck_24E  " ";
CM_ SG_ 580 ACC_RollingCounter_24E  "rolling counter ";
CM_ SG_ 580 ACC_EngineStartStopRequest  "0x1= EngineAutoStopRequest (ÇëÇó·¢¶¯»ú½øÈëSTOP×´Ì¬)£»
0x2=EngineAutoStartRequest(ÇëÇó·¢¶¯»ú½øÈëµ½START×´Ì¬)£» ";
CM_ SG_ 580 ACC_ACCTargetAcceleration  "ACC target acceleration for transmission. ";

CM_ BO_ 583  " ";
CM_ SG_ 583 APA_CRCCheck_247  " ";
CM_ SG_ 583 APA_RollingCounter_247  "rolling counter ";

CM_ BO_ 632  "1¡¢L2.5¼°ÒÔÏÂµÄ³£¹æÈ¼ÓÍ³µÓÉEPBi·¢ËÍ£»PHEV/APA7/L3+/HEV/REEVµÈ´îÔØIBCUµÄÏîÄ¿ÓÉSRS·¢ËÍ
2¡¢BDC¼¯³ÉÒ£¿Ø½ø³ö¹¦ÄÜÊ±½ÓÊÕ¸Ã±¨ÎÄ ";
CM_ SG_ 632 ESP_YawRate  "ÓÒÕý×ó¸º£¨¾ÙÀýÀí½â=Ë®Æ½Â·ÃæÏò
ÓÒ×ªÍäÊ±£¬·¢ÕýÖµ¡£·´Ö®·¢¸ºÖµ£© ";
CM_ SG_ 632 ESP_LongAccel  "¾ÙÀýÀí½â=Ë®Æ½Â·ÃæÖ±Ïß¼ÓËÙ
Ê±£¬·¢ÕýÖµ¡£·´Ö®·¢¸ºÖµ¡£ ";
CM_ SG_ 632 ESP_LatAccel  "ÓÒÕý×ó¸º£¨¾ÙÀýÀí½â=Ë®Æ½Â·ÃæÏò
ÓÒ×ªÍäÊ±£¬·¢ÕýÖµ¡£·´Ö®·¢¸ºÖµ£© ";

CM_ BO_ 349  " ";
CM_ SG_ 349 ESP_YawRate  "ÓÒÕý×ó¸º£¨¾ÙÀýÀí½â=Ë®Æ½Â·ÃæÏò
ÓÒ×ªÍäÊ±£¬·¢ÕýÖµ¡£·´Ö®·¢¸ºÖµ£© ";
CM_ SG_ 349 ESP_LongAccel  "¾ÙÀýÀí½â=Ë®Æ½Â·ÃæÖ±Ïß¼ÓËÙ
Ê±£¬·¢ÕýÖµ¡£·´Ö®·¢¸ºÖµ¡£ ";
CM_ SG_ 349 ESP_LatAccel  "ÓÒÕý×ó¸º£¨¾ÙÀýÀí½â=Ë®Æ½Â·ÃæÏò
ÓÒ×ªÍäÊ±£¬·¢ÕýÖµ¡£·´Ö®·¢¸ºÖµ£© ";

CM_ BO_ 862  "Ô´¶ËADAS_ADS/ACC_307,0
RADAR_ADS_307,0
ADASA_ACC/FR/FC_307,0
ADASD_ADC_307,0 ";

CM_ BO_ 823  " ";
CM_ SG_ 823 PowercycleIBCU  "Ê¶±ðµ½IG ON´ÎÊý ";
CM_ SG_ 823 VoltageVR  "PIN½ÅÉÏµÄµçÑ¹Öµ ";
CM_ SG_ 823 VoltageUB  "PIN½ÅÉÏµÄµçÑ¹Öµ ";
CM_ SG_ 823 ESP_EpbReqAvl  "CHS_IBCU_337 ";
CM_ SG_ 823 IBCU_BrkSysFltLamp  " ";
CM_ SG_ 823 ESP_WheelSpdSensorError  " ";
CM_ SG_ 823 ESP_WheelSpdSensorEcuError  " ";
CM_ SG_ 823 ESP_VGH_Status  "½öEPBi×Ô¼ºÊ¹ÓÃ ";
CM_ SG_ 823 ESP_VGH_Available  "½öEPBi×Ô¼ºÊ¹ÓÃ ";
CM_ SG_ 823 ESP_TPMSresetstatus  "¼ä½ÓÊ½Ì¥Ñ¹¼à²âÊ¹ÓÃ ";
CM_ SG_ 823 ESP_TPMS_WarningStatus  "¼ä½ÓÊ½Ì¥Ñ¹¼à²âÊ¹ÓÃ ";
CM_ SG_ 823 ESP_TPMS_MalfunctionStatus  "¼ä½ÓÊ½Ì¥Ñ¹¼à²âÊ¹ÓÃ ";
CM_ SG_ 823 ESP_RRWheelSpdSensorSigFailure  " ";
CM_ SG_ 823 ESP_RRWheelSpdSensorFailure  " ";
CM_ SG_ 823 ESP_RRWheelSpdSensor_ShtBAT  " ";
CM_ SG_ 823 ESP_RRWheelSpdSensor_Open  " ";
CM_ SG_ 823 ESP_RRWheelSpdSensor_GND  " ";
CM_ SG_ 823 ESP_RollingCounter_508  " ";
CM_ SG_ 823 ESP_RLWheelSpdSensorSigFailure  " ";
CM_ SG_ 823 ESP_RLWheelSpdSensorFailure  " ";
CM_ SG_ 823 ESP_RLWheelSpdSensor_ShtBAT  " ";
CM_ SG_ 823 ESP_RLWheelSpdSensor_Open  " ";
CM_ SG_ 823 ESP_RLWheelSpdSensor_GND  " ";
CM_ SG_ 823 ESP_FRWheelSpdSensorSigFailure  " ";
CM_ SG_ 823 ESP_FRWheelSpdSensorFailure  " ";
CM_ SG_ 823 ESP_FRWheelSpdSensor_ShtBAT  " ";
CM_ SG_ 823 ESP_FRWheelSpdSensor_Open  " ";
CM_ SG_ 823 ESP_FRWheelSpdSensor_GND  " ";
CM_ SG_ 823 ESP_FLWheelSpdSensorSigFailure  " ";
CM_ SG_ 823 ESP_FLWheelSpdSensorFailure  " ";
CM_ SG_ 823 ESP_FLWheelSpdSensor_ShtBAT  " ";
CM_ SG_ 823 ESP_FLWheelSpdSensor_Open  " ";
CM_ SG_ 823 ESP_FLWheelSpdSensor_GND  " ";
CM_ SG_ 823 ESP_CRCCheck_508  " ";

CM_ BO_ 870  "Ô´¶ËB_TMS_366»ò
HybridA_TMS_398,3
£¨C857Ö®Ç°ÏîÄ¿Ô´¶ËBCAN£¬C857Ö®ºóÏîÄ¿Ô´¶ËHybridA£© ";

CM_ BO_ 1302  " ";

CM_ BO_ 1328  " ";
CM_ SG_ 1328 IP_TotalOdometer  "GW±¨ÎÄ×ª·¢ ";
CM_ SG_ 1328 IP_EngineOffTime  "This signal identifies the amount of time from IGN Off to the next Ignition cycle.  This signal is required for the Thermal Estimation algorithms to work properly.
GW±¨ÎÄ×ª·¢ ";

CM_ BO_ 378  "C857¼°Ö®ºóµÄÏîÄ¿Ôö¼Ó±¾Íø¶Î½ÓÊÕ·½TMS,BDC ";
CM_ SG_ 378 ESP_TankTurn_EngTorqIncRearActive  " ";
CM_ SG_ 378 ESP_TankTurn_TorqIncwhlRear  " ";
CM_ SG_ 378 ESP_TankTurn_EngTorqIncFrontActive  " ";
CM_ SG_ 378 ESP_TankTurn_TorqIncwhlFront  " ";
CM_ SG_ 378 IBCU_TankTurn_Status  " ";
CM_ SG_ 378 IBCU_BrkPedlTrvlDrvrVld  " ";
CM_ SG_ 378 IBCU_BrkPedlTrvlDrvr  " ";
CM_ SG_ 378 IBCU_EdcFrntMotTarSpd  " ";
CM_ SG_ 378 IBCU_EdcReMotTarSpd  " ";
CM_ SG_ 378 IBCU_TcsFrntMotTarSpd  " ";
CM_ SG_ 378 IBCU_TcsReMotTarSpd  " ";
CM_ SG_ 378 IBCU_BrakeFluid_Warning  " ";
CM_ SG_ 378 ESP_VehicleSpeedValid2  "1CA ";
CM_ SG_ 378 ESP_VehicleSpeedValid  "TCU½ÓÊÕÎªDCT×¨ÓÃ ";
CM_ SG_ 378 ESP_VehicleSpeed2  "1CA ";
CM_ SG_ 378 ESP_VehicleSpeed  "TCU½ÓÊÕÎªDCT×¨ÓÃ ";
CM_ SG_ 378 ESP_TqDecSlowwhlRear  " ";
CM_ SG_ 378 ESP_TqDecSlowwhlFront  " ";
CM_ SG_ 378 ESP_TqDecFastwhlFront  " ";
CM_ SG_ 378 ESP_TorqIncwhlRear  " ";
CM_ SG_ 378 ESP_TorqIncwhlFront  " ";
CM_ SG_ 378 ESP_RollingCounter_1C8  " ";
CM_ SG_ 378 ESP_RollingCounter_1AC  " ";
CM_ SG_ 378 ESP_RollingCounter_187  "AT/DCT ";
CM_ SG_ 378 ESP_pMcVirtual_Q  " ";
CM_ SG_ 378 ESP_pMcVirtual  " ";
CM_ SG_ 378 ESP_MbRegenTarWhlRearQlfr  " ";
CM_ SG_ 378 ESP_MbRegenTarWhlRear  " ";
CM_ SG_ 378 ESP_MbRegenTarWhlFrontQlfr  " ";
CM_ SG_ 378 ESP_MbRegenTarWhlFront  " ";
CM_ SG_ 378 ESP_ESPActiveStatus  "TCU½ÓÊÕÎªDCT×¨ÓÃ ";
CM_ SG_ 378 ESP_EngTorqIncRearActive  " ";
CM_ SG_ 378 ESP_EngTorqDecRearActive  " ";
CM_ SG_ 378 ESP_EngTorqDecFrontActive  " ";
CM_ SG_ 378 ESP_EBDFailStatus  "TCU½ÓÊÕÎªDCT×¨ÓÃ ";
CM_ SG_ 378 ESP_CRCCheck_1C8  " ";
CM_ SG_ 378 ESP_CRCCheck_1AC  " ";
CM_ SG_ 378 ESP_CRCCheck_197  " ";
CM_ SG_ 378 ESP_CRCCheck_187  "AT/DCT ";

CM_ BO_ 381  " ";
CM_ SG_ 381 PCU_RollingCounter_1C4  " ";
CM_ SG_ 381 PCU_RearMotSts  " ";
CM_ SG_ 381 PCU_PwrIndcdRealTqRearWhl  " ";
CM_ SG_ 381 PCU_PwrIndcdDrvrReqTqWhlRear  " ";
CM_ SG_ 381 PCU_ESPTqReqAvlRear  " ";
CM_ SG_ 381 PCU_CRCCheck_1C4  " ";
CM_ SG_ 381 PCU_RollingCounter_1BE  " ";
CM_ SG_ 381 PCU_MbRegenWhlRear  " ";
CM_ SG_ 381 PCU_MbRegenMaxWhlTotal  " ";
CM_ SG_ 381 PCU_MbRegenMaxRearWhl  " ";
CM_ SG_ 381 PCU_CRCCheck_1BE  " ";
CM_ SG_ 381 PCU_PwrTrainSts  " ";
CM_ SG_ 381 PCU_RollingCounter_1A6  " ";
CM_ SG_ 381 PCU_MbRegenWhlFront  " ";
CM_ SG_ 381 PCU_MbRegenMaxWhlQlfr  " ";
CM_ SG_ 381 PCU_MbRegenMaxFrontWhlVld  " ";
CM_ SG_ 381 PCU_MbRegenMaxFrontWhl  " ";
CM_ SG_ 381 PCU_CRCCheck_1A6  " ";
CM_ SG_ 381 PCU_AccPedlVld  " ";
CM_ SG_ 381 PCU_AccPedl  "RMU·¨¹æÒªÇó ";
CM_ SG_ 381 PCU_RollingCounter_211  " ";
CM_ SG_ 381 PCU_RearMotStsVld  " ";
CM_ SG_ 381 PCU_PwrIndcdRealTqFrontWhl  " ";
CM_ SG_ 381 PCU_PwrIndcdDrvrReqTqWhlFront  " ";
CM_ SG_ 381 PCU_FrontMotStsVld  " ";
CM_ SG_ 381 PCU_FrontMotSts  " ";
CM_ SG_ 381 PCU_ESPTqReqAvlFront  " ";
CM_ SG_ 381 PCU_CRCCheck_211  " ";
CM_ SG_ 381 PCU_TarGearReqValid  " ";
CM_ SG_ 381 PCU_TarGearReq  " ";

CM_ BO_ 459  "BDC¼¯³ÉÒ£¿Ø½ø³ö¹¦ÄÜÊ±½ÓÊÕ¸Ã±¨ÎÄ ";
CM_ SG_ 459 IBCU_ElectrodelessBrakeModeFeedBack  " ";
CM_ SG_ 459 IBCU_ESPTSMAvlSts  " ";
CM_ SG_ 459 IBCU_ESPTSMAct  " ";
CM_ SG_ 459 IBCU_EPBrequest  " ";
CM_ SG_ 459 IBCU_EPBrequestValid  " ";
CM_ SG_ 459 WhlPreLeReVld  " ";
CM_ SG_ 459 WhlPreRiReVld  " ";
CM_ SG_ 459 WhlPreLeFrntVld  " ";
CM_ SG_ 459 WhlPreRiFrntVld  " ";
CM_ SG_ 459 WheelPressureRearLeft_Model  " ";
CM_ SG_ 459 WheelPressureRearRight_Model  " ";
CM_ SG_ 459 WheelPressureFrontLeft_Model  " ";
CM_ SG_ 459 WheelPressureFrontRight_Model  " ";
CM_ SG_ 459 IBCU_BrkTqReqAvail  " ";
CM_ SG_ 459 IBCU_HydBrkActvTq  " ";
CM_ SG_ 459 IBCU_DrvrBrkReqTqVID  " ";
CM_ SG_ 459 IBCU_DrvrBrkReqTq  " ";
CM_ SG_ 459 IBCU_BrkReqTq  " ";
CM_ SG_ 459 IBCU_NBrkMode  "Conti IBCU ";
CM_ SG_ 459 IBCU_System_Status  " ";

CM_ BO_ 523  "BDC¼¯³ÉÒ£¿Ø½ø³ö¹¦ÄÜÊ±½ÓÊÕ¸Ã±¨ÎÄ ";
CM_ SG_ 523 IBCU_BDC_Status  " ";
CM_ SG_ 523 IBCU_BDCAvlblSts  " ";
CM_ SG_ 523 IBCU_iDCS_State  " ";
CM_ SG_ 523 IBCU_iDCSLevFd  " ";
CM_ SG_ 523 IBCU_iDCSAvlblSts  " ";
CM_ SG_ 523 ESP_CDD_Availablebysituaion  " ";
CM_ SG_ 523 IBCUVLA  "IBCU¼ÆËãµÄ·ÇIMU²âÁ¿µÄÕû³µ¼õËÙ¶È ";
CM_ SG_ 523 ESP_AEBSpeedDropActive  " ";
CM_ SG_ 523 IBCU_TankTurn_EDLOpenSet  " ";
CM_ SG_ 523 IBCU_EBS_Status  " ";
CM_ SG_ 523 IBCU_TankTurn_Enable  " ";
CM_ SG_ 523 IBCU_TankTurn_Available  " ";
CM_ SG_ 523 ESP_VehicleStandstillVld  " ";
CM_ SG_ 523 ESP_EBDActive  " ";
CM_ SG_ 523 IBCU_DTCAvailable  " ";
CM_ SG_ 523 Wheel_Speed_FL_Pulse  "All4wheelpulsesignalsaresentbyABSwithoutfiltering.Theriseedgeandfalledgearebothcountedinit,thewheelpulsemustbesequentialintheway0,1,2¡­254,0,4¡­ ";
CM_ SG_ 523 Wheel_Speed_FR_Pulse  "All4wheelpulsesignalsaresentbyABSwithoutfiltering.Theriseedgeandfalledgearebothcountedinit,thewheelpulsemustbesequentialintheway0,1,2¡­254,0,3¡­ ";
CM_ SG_ 523 ESP_MasCylBraPreByDriver  " ";
CM_ SG_ 523 ESP_MasCylBraPreByDriverValid  " ";
CM_ SG_ 523 Wheel_SpeedPulseTimeStamp_FL  " ";
CM_ SG_ 523 Wheel_SpeedPulseTimeStamp_FR  " ";
CM_ SG_ 523 ESP_DTV_Available  " ";
CM_ SG_ 523 ESP_DTV_Active  " ";
CM_ SG_ 523 Wheel_Speed_RR_Pulse  "All4wheelpulsesignalsaresentbyABSwithoutfiltering.Theriseedgeandfalledgearebothcountedinit,thewheelpulsemustbesequentialintheway0,1,2¡­254,0,1¡­ ";
CM_ SG_ 523 Wheel_Speed_RL_Pulse  "All4wheelpulsesignalsaresentbyABSwithoutfiltering.Theriseedgeandfalledgearebothcountedinit,thewheelpulsemustbesequentialintheway0,1,2¡­254,0,2¡­ ";
CM_ SG_ 523 Wheel_Speed_FR_Pulse  "All4wheelpulsesignalsaresentbyABSwithoutfiltering.Theriseedgeandfalledgearebothcountedinit,thewheelpulsemustbesequentialintheway0,1,2¡­254,0,3¡­ ";
CM_ SG_ 523 Wheel_Speed_FL_Pulse  "All4wheelpulsesignalsaresentbyABSwithoutfiltering.Theriseedgeandfalledgearebothcountedinit,thewheelpulsemustbesequentialintheway0,1,2¡­254,0,4¡­ ";
CM_ SG_ 523 ESP_UrgencyBrakeAlarm  " ";
CM_ SG_ 523 ESP_TODTorqueMaxLimit  " ";
CM_ SG_ 523 ESP_RollingCounter_277  "rollingcounter ";
CM_ SG_ 523 ESP_RollingCounter_258  "258 ";
CM_ SG_ 523 ESP_RollingCounter_208  "rollingcounter ";
CM_ SG_ 523 ESP_RollingCounter_206  "rollingcounter ";
CM_ SG_ 523 ESP_MasCylBrakePressureValid  "258 ";
CM_ SG_ 523 ESP_MasCylBrakePressure  "indicatedthepressureofbrakemastercylinder,butnotthepressureofbrake ";
CM_ SG_ 523 ESP_IncreasePressureReqOK  "½¨Ñ¹³É¹¦ºó³ÖÐø·¢15Ö¡ ";
CM_ SG_ 523 ESP_HHC_Available  "258 AT/DCT ";
CM_ SG_ 523 ESP_HHC_Active  "258 ";
CM_ SG_ 523 ESP_ECDAvailable  "ESP·¢ËÍ ";
CM_ SG_ 523 ESP_ECDActive  "ESP·¢ËÍ ";
CM_ SG_ 523 ESP_CRCCheck_277  " ";
CM_ SG_ 523 ESP_CRCCheck_258  "258 ";
CM_ SG_ 523 ESP_CRCCheck_208  " ";
CM_ SG_ 523 ESP_CRCCheck_206  " ";
CM_ SG_ 523 ESP_BrakeLightOnRequest  "258 ";
CM_ SG_ 523 ESP_AutoHoldStandby  "258 ";
CM_ SG_ 523 ESP_AutoHoldAvailable  "258 ";
CM_ SG_ 523 ESP_AutoHoldActive  "258 ";
CM_ SG_ 523 ABS_TODFastOpenRequest  " ";

CM_ BO_ 650  " ";
CM_ SG_ 650 IP_HandBrakeSwitch  "GW±¨ÎÄ×ª·¢ ";

CM_ BO_ 651  " ";

CM_ BO_ 724  "Ô´¶ËADAS_APA_2C6,1
ADASD_APA/ADC_2C6,1
ADASA_APA_2C6,1 ";
CM_ SG_ 724 APA_ReleasePressureReq  "²©ÊÀÌá³ö²»ÄÜÓÃÒ»¸öÐÅºÅ±íÊ¾Á½ÖÖ×´Ì¬£¬ÐÂÔöµÄÐÅºÅ ";

CM_ BO_ 721  " ";
CM_ SG_ 721 BCM_ReversePosition  "MT³µÐÍ ";

CM_ BO_ 758  " ";
CM_ SG_ 758 HU_IndirectTPMSReset  "¼ä½ÓÌ¥Ñ¹ÉèÖÃ=
°´ÏÂ¸´Î»°´¼üËÉ¿ªºó£¬HUÁ¬Ðø·¢3Ö¡Request resetÇëÇóÊÂ¼þÖ¡ÐÅºÅ£¬È»ºóÁ¬Ðø·¢3Ö¡No requestÐÅºÅ£¬Ã¿Ö¡±¨ÎÄ·¢ËÍ¼ä¸ô50ms ";

CM_ BO_ 827  " ";
CM_ SG_ 827 PCU_TowingMode  " ";
CM_ SG_ 827 PCU_PwrTqWhMinTotal  " ";
CM_ SG_ 827 PCU_PwrTqWhMaxTotal  " ";
CM_ SG_ 827 PCU_PwrTqWhRearMin  " ";
CM_ SG_ 827 PCU_PwrTqWhRearMax  " ";
CM_ SG_ 827 PCU_PwrTqWhFrontMin  " ";
CM_ SG_ 827 PCU_PwrTqWhFrontMax  " ";

CM_ BO_ 916  "Ô´¶ËINFO_THU_3BD,0 ";
CM_ SG_ 916 HU_CdcEpbSwtSet  "EPB ";

CM_ BO_ 1021  " ";

CM_ BO_ 1326  " ";
CM_ SG_ 1326 IP_IndirectTPMSReset  "°´ÏÂ¸´Î»°´¼üËÉ¿ªºó£¬Á¬Ðø·¢3Ö¡Request resetÇëÇóÊÂ¼þÖ¡ÐÅºÅ£¬È»ºóÁ¬Ðø·¢3Ö¡No requestÐÅºÅ£¬Ã¿Ö¡±¨ÎÄ·¢ËÍ¼ä¸ô50ms ";

CM_ BO_ 1706  " ";
CM_ SG_ 1706 EPBi_DTC2_Status  "DTCÉÏ´« ";
CM_ SG_ 1706 EPBi_DTC2_MiddByte  "DTCÉÏ´« ";
CM_ SG_ 1706 EPBi_DTC2_LowByte  "DTCÉÏ´« ";
CM_ SG_ 1706 EPBi_DTC2_HighByte  "DTCÉÏ´« ";
CM_ SG_ 1706 EPBi_DTC1_Status  "DTCÉÏ´« ";
CM_ SG_ 1706 EPBi_DTC1_MiddByte  "DTCÉÏ´« ";
CM_ SG_ 1706 EPBi_DTC1_LowByte  "DTCÉÏ´« ";
CM_ SG_ 1706 EPBi_DTC1_HighByte  "DTCÉÏ´« ";

CM_ BO_ 1056  "Diag--VDC--CHS ";

CM_ BO_ 1090  "Diag--VDC--CHS ";

CM_ BO_ 1410  " ";
CM_ SG_ 1410 EPBI_NotSleep_BYTE7BIT6  "IBCU³µÐÍ ";
CM_ SG_ 1410 EPBI_NotSleep_BYTE7BIT5  "IBCU³µÐÍ ";
CM_ SG_ 1410 EPBI_NotSleep_BYTE7BIT4  "EPBi³µÐÍ ";
CM_ SG_ 1410 EPBI_NotSleep_BYTE7BIT3  "EPBi³µÐÍ ";
CM_ SG_ 1410 EPBi_NotSleep_BYTE7BIT2  " ";
CM_ SG_ 1410 EPBi_NotSleep_BYTE7BIT1  " ";
CM_ SG_ 1410 EPBi_NotSleep_BYTE7BIT0  " ";
CM_ SG_ 1410 EPBi_WakeUp_BYTE4BIT2  " ";
CM_ SG_ 1410 EPBi_WakeUp_BYTE4BIT1  " ";
CM_ SG_ 1410 EPBi_WakeUp_BYTE4BIT0  " ";

CM_ BO_ 817  " ";

CM_ BO_ 431  " ";
CM_ SG_ 431 TCU_ShiftPostionValid  " ";
CM_ SG_ 431 TCU_ShiftInProgressVld  " ";
CM_ SG_ 431 TCU_ShiftInProgress  " ";
CM_ SG_ 431 TCU_GearShiftPosition  "TCU receives driver demands gear from ESL and make decisition of actual drive mode based on current vehicle/transmission status.
PCU receives this signals to understand actual drive mode and estimate target gear ";
CM_ SG_ 431 TCU_CRCCheck_1A8  "CRCCheck_SAE_J1850_2001,multinomial is X8+X4+X3+X2+1 ";
CM_ SG_ 431 TCU_ActualDrivingGear  "RMU·¨¹æÒªÇó
Message relaying what the current engaged gear is (On DCT this will also be the gear on the shaft with the engaged clutch). ";

CM_ BO_ 800  "GW×Ô·¢ ";
CM_ SG_ 800 GW_OTAmode_Chks  "ÓëGW_OTAmode·ÖÅäµ½Ò»¸öIDµÄÏàÁÚ×Ö½Ú ";
CM_ SG_ 800 GW_OTAmode_Cntr  "ÓëGW_OTAmode·ÖÅäµ½1¸ö×Ö½Ú ";
CM_ SG_ 800 GW_OTAmode  "ÓëGW_OTAmode_Cntr·ÖÅäµ½1¸ö×Ö½Ú ";
CM_ SG_ 800 GW_ResetReq  " ";

CM_ BO_ 1563  " ";
CM_ SG_ 1563 KeyLearn_Authernticator_61B  "¼û¡¶³µ¶ËÏûÏ¢ÈÏÖ¤¼¯³É¹æ·¶¡· ";
CM_ SG_ 1563 KeyLearn_Random_61B  "¼û¡¶³µ¶ËÏûÏ¢ÈÏÖ¤¼¯³É¹æ·¶¡· ";

CM_ BO_ 429  "GW×Ô·¢ ";

CM_ BO_ 939  "Ô´¶ËINFO_THU_375,4 ";

CM_ BO_ 393  " ";
CM_ SG_ 393 IBCU_ReqSecOCSYNMSG  "¼û¡¶³µ¶ËÏûÏ¢ÈÏÖ¤¼¯³É¹æ·¶¡·
´¥·¢Ê±Á¬Ðø·¢ËÍ3Ö¡£¬Ö¡¼ä¸ô50ms ";

CM_ BO_ 881  " ";

CM_ BO_ 394  "ÐÅºÅÂ·ÓÉ£¨±äÖÜÆÚ£© ";
CM_ SG_ 394 TCU_ParkingRequest  "1¡¢This signal is TCU request ACM to implement P or Not P.
2¡¢P2¹¹ÐÍ£¨HF640Æ½Ì¨£©ÓÉTCU·¢ËÍ£¬P13¹¹ÐÍ£¨HF140Æ½Ì¨£©ÓÉPCU·¢ËÍ ";

CM_ BO_ 266  "BDC¼¯³ÉÒ£¿Ø½ø³ö¹¦ÄÜÊ±½ÓÊÕ¸Ã±¨ÎÄ ";
CM_ SG_ 266 EPB_BackupCapability  "ÓÃÓÚ×¤³µÈßÓà ";
CM_ SG_ 266 EPB_ClampForce_Secondary  "ÓÃÓÚ×¤³µÈßÓà ";
CM_ SG_ 266 EPB_FailStatus_Secondary  "ÓÃÓÚ×¤³µÈßÓà ";
CM_ SG_ 266 EPB_Status_Secondary  "ÓÃÓÚ×¤³µÈßÓà ";
CM_ SG_ 266 EPB_RollingCounter_10A  " ";
CM_ SG_ 266 EPB_CRCCheck_10A  " ";
CM_ SG_ 266 EpbCdpReq  " ";
CM_ SG_ 266 EPB_EAR_Available  " ";
CM_ SG_ 266 EPB_Status_Priamary  "ÓÃÓÚ×¤³µÈßÓà ";
CM_ SG_ 266 EPB_FailStatus_Primary  "ÓÃÓÚ×¤³µÈßÓà ";
CM_ SG_ 266 ESP_RWU_ParkingAvailForACC  " ";
CM_ SG_ 266 ESP_RWU_ParkingActiveForACC  " ";
CM_ SG_ 266 EPB_TextDisplay  " ";
CM_ SG_ 266 EPB_FunctionLamp  " ";
CM_ SG_ 266 EPB_FailureLamp  " ";
CM_ SG_ 266 EPB_APArequest_Available  " ";

CM_ BO_ 958  " ";

CM_ BO_ 815  "Ô´¶ËHybridA_PCU_3FC,3 ";
CM_ SG_ 815 PCU_AccPedlE  "correspond SAE J1979 PID0x4A ";
CM_ SG_ 815 PCU_AccPedlD  "correspond SAE J1979 PID0x49 ";

CM_ BO_ 274  " ";
CM_ SG_ 274 EPB_CRCCheck_112  "EPB ";
CM_ SG_ 274 EPB_RollingCounter_112  "EPB ";

CM_ BO_ 586  " ";
CM_ SG_ 586 ESL_DriverParkButtonFaultStatus  "TCU½ÓÊÕÎªDCT×¨ÓÃ
ACM½ÓÊÕÎªAT×¨ÓÃ
Ô­ÐÅºÅÃû³ÆESL_DriverParkButtonStatus£¬CD569¡¢S202DAÊ¹ÓÃ ";

CM_ BO_ 810  " ";
CM_ SG_ 810 TRM_RollingCounter_32A  " ";
CM_ SG_ 810 TRM_CRCCheck_32A  " ";

CM_ BO_ 268  " ";
CM_ SG_ 268 TM1_OperMdl  "Ðý±ä×ÔÑ§Ï°Îªµ¥¶ÀµÄÐÅºÅ£¬ÒÔµ¥¶ÀÐÅºÅÎª×¼ ";

CM_ BO_ 269  " ";
CM_ SG_ 269 TM2_OperMdl  "Ðý±ä×ÔÑ§Ï°Îªµ¥¶ÀµÄÐÅºÅ£¬ÒÔµ¥¶ÀÐÅºÅÎª×¼ ";

CM_ BO_ 1341  "Ô´¶ËINFO_THU_375,3 ";

CM_ BO_ 842  "Ô´¶ËINFO_THU_364,1 ";
CM_ SG_ 842 HU_TankTurnStatusSetReq  " ";

CM_ BO_ 519  " ";
CM_ SG_ 519 PCU_IDCSAvlSts  " ";

CM_ BO_ 2015  " ";

CM_ BO_ 1920  "Ê¹ÓÃCANÕï¶ÏÒÇÊ±·¢ËÍ±¨ÎÄDLC³¤¶ÈÎª8£¬Ê¹ÓÃCANFDÕï¶ÏÒÇÊ±·¢ËÍ±¨ÎÄDLC³¤¶ÈÎª8µ½64 ";

CM_ BO_ 1928  " ";

CM_ BO_ 2021  "1¡¢Ê¹ÓÃCANÕï¶ÏÒÇÊ±·¢ËÍ±¨ÎÄDLC³¤¶ÈÎª8£¬Ê¹ÓÃCANFDÕï¶ÏÒÇÊ±·¢ËÍ±¨ÎÄDLC³¤¶ÈÎª8µ½64
2¡¢OBDÕï¶Ï×¨ÓÃ ";

CM_ BO_ 2029  "OBDÕï¶Ï×¨ÓÃ ";

CM_ BO_ 977  "Ô´¶ËHybridA_PCU_3FC,2 ";
CM_ SG_ 977 PCU_CruiseCtrlSts  " ";

CM_ BO_ 574  " ";
CM_ SG_ 574 EspSysSts  " ";
CM_ SG_ 574 IBCU_VoltageInfo_BeforeUBV_Mosfet  "IBCUÄÚ²¿Ê¹ÓÃ ";
CM_ SG_ 574 IBCU_VoltageInfo_BeforeUBM_Mosfet  "IBCUÄÚ²¿Ê¹ÓÃ ";
CM_ SG_ 574 IBCU_RSS_ValVol  "IBCUÄÚ²¿Ê¹ÓÃ ";
CM_ SG_ 574 IBCU_SimulatorCutValve_Cur  "IBCUÄÚ²¿Ê¹ÓÃ ";
CM_ SG_ 574 IBCU_MasterCylinderCutValve2_Cur  "IBCUÄÚ²¿Ê¹ÓÃ ";
CM_ SG_ 574 IBCU_MasterCylinderCutValve1_Cur  "IBCUÄÚ²¿Ê¹ÓÃ ";
CM_ SG_ 574 IBCU_PressureCylinderCutValve2_Cur  "IBCUÄÚ²¿Ê¹ÓÃ ";
CM_ SG_ 574 IBCU_PressureCylinderCutValve1_Cur  "IBCUÄÚ²¿Ê¹ÓÃ ";
CM_ SG_ 574 IBCU_MotVol  "IBCUÄÚ²¿Ê¹ÓÃ ";
CM_ SG_ 574 IBCU_MotCtrlType  "IBCUÄÚ²¿Ê¹ÓÃ ";
CM_ SG_ 574 IBCU_MotTorqAct  "IBCUÄÚ²¿Ê¹ÓÃ ";
CM_ SG_ 574 IBCU_MotTorqCmd  "IBCUÄÚ²¿Ê¹ÓÃ ";
CM_ SG_ 574 IBCU_SpeedAct  "IBCUÄÚ²¿Ê¹ÓÃ ";
CM_ SG_ 574 IBCU_SpeedCmd  "IBCUÄÚ²¿Ê¹ÓÃ ";
CM_ SG_ 574 IBCU_PistonPos  "IBCUÄÚ²¿Ê¹ÓÃ ";
CM_ SG_ 574 IBCU_IdleCtrlType  "IBCUÄÚ²¿Ê¹ÓÃ ";
CM_ SG_ 574 IBCU_CtrlMode  "IBCUÄÚ²¿Ê¹ÓÃ ";
CM_ SG_ 574 IBCU_PressureCmd  "IBCUÄÚ²¿Ê¹ÓÃ ";

CM_ BO_ 691  "Ô´¶ËINFO_THU_364,2 ";
CM_ SG_ 691 HU_BDCSwtSet  " ";
CM_ SG_ 691 HU_iDCSLevel  " ";
CM_ SG_ 691 HU_iDCS_Switch_Status  " ";

CM_ BO_ 773  "Ô´¶ËHybridA_BMS_34C,2 ";

BA_DEF_ SG_  "GenSigStartValue" INT 0 0;
BA_DEF_ SG_  "GenSigInvalidValue" STRING  ;
BA_DEF_ SG_  "GenSigCycleTime" INT 0 0;
BA_DEF_ SG_  "GenSigSendType" ENUM  "Cyclic","OnWrite","OnWriteWithRepetition","OnChange","OnChangeWithRepetition","IfActive","IfActiveWithRepetition","NoSigSendType","NotUsed","NotUsed","NotUsed","NotUsed","NotUsed";
BA_DEF_  "Baudrate" INT 0 1000000;
BA_DEF_  "BusType" STRING ;
BA_DEF_  "NmType" STRING ;
BA_DEF_  "Manufacturer" STRING ;
BA_DEF_  "VersionYear" INT 2009 2210;
BA_DEF_  "VersionNumber" INT 0 65535;
BA_DEF_  "VersionMonth" INT 0 18;
BA_DEF_  "VersionDay" INT 0 49;
BA_DEF_ BU_  "NodeLayerModules" STRING ;
BA_DEF_ BU_  "ILUsed" ENUM  "No","Yes";
BA_DEF_  "GenNWMTalkNM" STRING ;
BA_DEF_  "GenNWMGotoMode_BusSleep" STRING ;
BA_DEF_  "GenNWMGotoMode_Awake" STRING ;
BA_DEF_  "GenNWMApCanWakeUp" STRING ;
BA_DEF_  "GenNWMApCanSleep" STRING ;
BA_DEF_  "GenNWMApCanOn" STRING ;
BA_DEF_  "GenNWMApCanOff" STRING ;
BA_DEF_  "GenNWMApCanNormal" STRING ;
BA_DEF_  "GenNWMApBusSleep" STRING ;
BA_DEF_ BO_  "GenMsgSendType" ENUM  "Cyclic","Event","NotUsed","NotUsed","NotUsed","Cyclic","NotUsed","IfActive","NoMsgSendType","NotUsed";
BA_DEF_ BO_  "GenMsgILSupport" ENUM  "No","Yes";
BA_DEF_ BO_  "GenMsgCycleTime" INT 0 65535;
BA_DEF_ BO_  "CANFD_BRS" ENUM  "0","1";
BA_DEF_ BO_  "VFrameFormat" ENUM  "StandardCAN","ExtendedCAN","reserved","reserved","reserved","reserved","reserved","reserved","reserved","reserved","reserved","reserved","reserved","reserved","StandardCAN_FD","ExtendedCAN_FD";
BA_DEF_DEF_  "GenSigStartValue" 0;
BA_DEF_DEF_  "GenSigInvalidValue" "/";
BA_DEF_DEF_  "GenSigCycleTime" 0;
BA_DEF_DEF_  "GenSigSendType" "Cyclic";
BA_DEF_DEF_  "Baudrate" 500000;
BA_DEF_DEF_  "BusType" "";
BA_DEF_DEF_  "NmType" "";
BA_DEF_DEF_  "Manufacturer" "CHANA";
BA_DEF_DEF_  "VersionYear" 2010;
BA_DEF_DEF_  "VersionNumber" 0;
BA_DEF_DEF_  "VersionMonth" 11;
BA_DEF_DEF_  "VersionDay" 0;
BA_DEF_DEF_  "NodeLayerModules" "CANoeILNLVector.dll";
BA_DEF_DEF_  "ILUsed" "Yes";
BA_DEF_DEF_  "GenNWMTalkNM" "TalkNM()";
BA_DEF_DEF_  "GenNWMGotoMode_BusSleep" "GotoMode_BusSleep()";
BA_DEF_DEF_  "GenNWMGotoMode_Awake" "GotoMode_Awake()";
BA_DEF_DEF_  "GenNWMApCanWakeUp" "apCanWakeUp()";
BA_DEF_DEF_  "GenNWMApCanSleep" "apCanSleep()";
BA_DEF_DEF_  "GenNWMApCanOn" "apCanOn()";
BA_DEF_DEF_  "GenNWMApCanOff" "apCanOff()";
BA_DEF_DEF_  "GenNWMApCanNormal" "apCanNormal()";
BA_DEF_DEF_  "GenNWMApBusSleep" "apBusSleep()";
BA_DEF_DEF_  "GenMsgSendType" "NoMsgSendType";
BA_DEF_DEF_  "GenMsgILSupport" "Yes";
BA_DEF_DEF_  "GenMsgCycleTime" 0;
BA_DEF_DEF_  "CANFD_BRS" "1";
BA_DEF_DEF_  "VFrameFormat" "StandardCAN";

BA_ "VersionYear" 2024;
BA_ "VersionNumber" 11;
BA_ "VersionDay" 28;
BA_ "Baudrate" 2000000;
BA_ "NmType" "OSEK";
BA_ "BusType" "CAN FD";
BA_ "GenMsgCycleTime" BO_ 80 500;
BA_ "GenMsgSendType" BO_ 80 0;
BA_ "VFrameFormat" BO_ 80 14;
BA_ "GenMsgCycleTime" BO_ 384 10;
BA_ "GenMsgSendType" BO_ 384 0;
BA_ "VFrameFormat" BO_ 384 14;
BA_ "GenMsgCycleTime" BO_ 997 10;
BA_ "GenMsgSendType" BO_ 997 0;
BA_ "VFrameFormat" BO_ 997 14;
BA_ "GenMsgCycleTime" BO_ 342 20;
BA_ "GenMsgSendType" BO_ 342 0;
BA_ "VFrameFormat" BO_ 342 14;
BA_ "GenMsgCycleTime" BO_ 580 20;
BA_ "GenMsgSendType" BO_ 580 0;
BA_ "VFrameFormat" BO_ 580 14;
BA_ "GenMsgCycleTime" BO_ 583 20;
BA_ "GenMsgSendType" BO_ 583 0;
BA_ "VFrameFormat" BO_ 583 14;
BA_ "GenMsgCycleTime" BO_ 632 20;
BA_ "GenMsgSendType" BO_ 632 0;
BA_ "VFrameFormat" BO_ 632 14;
BA_ "GenMsgCycleTime" BO_ 349 10;
BA_ "GenMsgSendType" BO_ 349 0;
BA_ "VFrameFormat" BO_ 349 14;
BA_ "GenMsgCycleTime" BO_ 862 100;
BA_ "GenMsgSendType" BO_ 862 0;
BA_ "VFrameFormat" BO_ 862 14;
BA_ "GenMsgCycleTime" BO_ 823 100;
BA_ "GenMsgSendType" BO_ 823 0;
BA_ "VFrameFormat" BO_ 823 14;
BA_ "GenMsgCycleTime" BO_ 870 100;
BA_ "GenMsgSendType" BO_ 870 0;
BA_ "VFrameFormat" BO_ 870 14;
BA_ "GenMsgCycleTime" BO_ 1302 1000;
BA_ "GenMsgSendType" BO_ 1302 0;
BA_ "VFrameFormat" BO_ 1302 14;
BA_ "GenMsgCycleTime" BO_ 1328 500;
BA_ "GenMsgSendType" BO_ 1328 0;
BA_ "VFrameFormat" BO_ 1328 14;
BA_ "GenMsgCycleTime" BO_ 378 10;
BA_ "GenMsgSendType" BO_ 378 0;
BA_ "VFrameFormat" BO_ 378 14;
BA_ "GenMsgCycleTime" BO_ 381 10;
BA_ "GenMsgSendType" BO_ 381 0;
BA_ "VFrameFormat" BO_ 381 14;
BA_ "GenMsgCycleTime" BO_ 459 10;
BA_ "GenMsgSendType" BO_ 459 0;
BA_ "VFrameFormat" BO_ 459 14;
BA_ "GenMsgCycleTime" BO_ 523 20;
BA_ "GenMsgSendType" BO_ 523 0;
BA_ "VFrameFormat" BO_ 523 14;
BA_ "GenMsgCycleTime" BO_ 650 40;
BA_ "GenMsgSendType" BO_ 650 0;
BA_ "VFrameFormat" BO_ 650 14;
BA_ "GenMsgCycleTime" BO_ 651 40;
BA_ "GenMsgSendType" BO_ 651 0;
BA_ "VFrameFormat" BO_ 651 14;
BA_ "GenMsgCycleTime" BO_ 724 40;
BA_ "GenMsgSendType" BO_ 724 0;
BA_ "VFrameFormat" BO_ 724 14;
BA_ "GenMsgCycleTime" BO_ 721 40;
BA_ "GenMsgSendType" BO_ 721 0;
BA_ "VFrameFormat" BO_ 721 14;
BA_ "GenMsgSendType" BO_ 758 1;
BA_ "VFrameFormat" BO_ 758 14;
BA_ "GenMsgCycleTime" BO_ 827 100;
BA_ "GenMsgSendType" BO_ 827 0;
BA_ "VFrameFormat" BO_ 827 14;
BA_ "GenMsgCycleTime" BO_ 916 100;
BA_ "GenMsgSendType" BO_ 916 0;
BA_ "VFrameFormat" BO_ 916 14;
BA_ "GenMsgCycleTime" BO_ 1021 100;
BA_ "GenMsgSendType" BO_ 1021 0;
BA_ "VFrameFormat" BO_ 1021 14;
BA_ "GenMsgSendType" BO_ 1326 1;
BA_ "VFrameFormat" BO_ 1326 14;
BA_ "GenMsgCycleTime" BO_ 1706 500;
BA_ "GenMsgSendType" BO_ 1706 0;
BA_ "VFrameFormat" BO_ 1706 14;
BA_ "GenMsgSendType" BO_ 1056 1;
BA_ "GenMsgSendType" BO_ 1090 1;
BA_ "GenMsgCycleTime" BO_ 1410 1000;
BA_ "GenMsgSendType" BO_ 1410 0;
BA_ "VFrameFormat" BO_ 1410 14;
BA_ "GenMsgCycleTime" BO_ 817 100;
BA_ "GenMsgSendType" BO_ 817 0;
BA_ "VFrameFormat" BO_ 817 14;
BA_ "GenMsgCycleTime" BO_ 431 10;
BA_ "GenMsgSendType" BO_ 431 0;
BA_ "VFrameFormat" BO_ 431 14;
BA_ "GenMsgCycleTime" BO_ 800 100;
BA_ "GenMsgSendType" BO_ 800 0;
BA_ "VFrameFormat" BO_ 800 14;
BA_ "GenMsgSendType" BO_ 1563 1;
BA_ "VFrameFormat" BO_ 1563 14;
BA_ "GenMsgSendType" BO_ 429 1;
BA_ "VFrameFormat" BO_ 429 14;
BA_ "GenMsgCycleTime" BO_ 939 100;
BA_ "GenMsgSendType" BO_ 939 0;
BA_ "VFrameFormat" BO_ 939 14;
BA_ "GenMsgSendType" BO_ 393 1;
BA_ "VFrameFormat" BO_ 393 14;
BA_ "GenMsgCycleTime" BO_ 881 100;
BA_ "GenMsgSendType" BO_ 881 0;
BA_ "VFrameFormat" BO_ 881 14;
BA_ "GenMsgCycleTime" BO_ 394 20;
BA_ "GenMsgSendType" BO_ 394 0;
BA_ "VFrameFormat" BO_ 394 14;
BA_ "GenMsgCycleTime" BO_ 266 10;
BA_ "GenMsgSendType" BO_ 266 0;
BA_ "VFrameFormat" BO_ 266 14;
BA_ "GenMsgCycleTime" BO_ 958 100;
BA_ "GenMsgSendType" BO_ 958 0;
BA_ "VFrameFormat" BO_ 958 14;
BA_ "GenMsgCycleTime" BO_ 815 100;
BA_ "GenMsgSendType" BO_ 815 0;
BA_ "VFrameFormat" BO_ 815 14;
BA_ "GenMsgCycleTime" BO_ 274 10;
BA_ "GenMsgSendType" BO_ 274 0;
BA_ "VFrameFormat" BO_ 274 14;
BA_ "GenMsgCycleTime" BO_ 586 20;
BA_ "GenMsgSendType" BO_ 586 0;
BA_ "VFrameFormat" BO_ 586 14;
BA_ "GenMsgCycleTime" BO_ 810 100;
BA_ "GenMsgSendType" BO_ 810 0;
BA_ "VFrameFormat" BO_ 810 14;
BA_ "GenMsgCycleTime" BO_ 268 10;
BA_ "GenMsgSendType" BO_ 268 0;
BA_ "VFrameFormat" BO_ 268 14;
BA_ "GenMsgCycleTime" BO_ 269 10;
BA_ "GenMsgSendType" BO_ 269 0;
BA_ "VFrameFormat" BO_ 269 14;
BA_ "GenMsgCycleTime" BO_ 1341 100;
BA_ "GenMsgSendType" BO_ 1341 0;
BA_ "VFrameFormat" BO_ 1341 14;
BA_ "GenMsgCycleTime" BO_ 842 100;
BA_ "GenMsgSendType" BO_ 842 0;
BA_ "VFrameFormat" BO_ 842 14;
BA_ "GenMsgCycleTime" BO_ 519 20;
BA_ "GenMsgSendType" BO_ 519 0;
BA_ "VFrameFormat" BO_ 519 14;
BA_ "GenMsgSendType" BO_ 2015 1;
BA_ "VFrameFormat" BO_ 2015 14;
BA_ "GenMsgSendType" BO_ 1920 1;
BA_ "VFrameFormat" BO_ 1920 14;
BA_ "GenMsgSendType" BO_ 1928 1;
BA_ "VFrameFormat" BO_ 1928 14;
BA_ "GenMsgSendType" BO_ 2021 1;
BA_ "VFrameFormat" BO_ 2021 14;
BA_ "GenMsgSendType" BO_ 2029 1;
BA_ "VFrameFormat" BO_ 2029 14;
BA_ "GenMsgCycleTime" BO_ 977 100;
BA_ "GenMsgSendType" BO_ 977 0;
BA_ "VFrameFormat" BO_ 977 14;
BA_ "GenMsgCycleTime" BO_ 574 100;
BA_ "GenMsgSendType" BO_ 574 0;
BA_ "VFrameFormat" BO_ 574 14;
BA_ "GenMsgCycleTime" BO_ 691 100;
BA_ "GenMsgSendType" BO_ 691 0;
BA_ "VFrameFormat" BO_ 691 14;
BA_ "GenMsgCycleTime" BO_ 773 500;
BA_ "GenMsgSendType" BO_ 773 0;
BA_ "VFrameFormat" BO_ 773 14;
BA_ "GenSigCycleTime" SG_ 80 SRS_PassengerBuckleSwitchStatus 500;
BA_ "GenSigCycleTime" SG_ 80 SRS_FrontPsgOccupancy 500;
BA_ "GenSigCycleTime" SG_ 80 SRS_DriverBuckleSwitchStatus 500;
BA_ "GenSigCycleTime" SG_ 80 SRS_RollingCounter_id050 500;

BA_ "GenSigCycleTime" SG_ 384 SAS_CRCCheck 10;
BA_ "GenSigCycleTime" SG_ 384 SAS_RollingCounter 10;
BA_ "GenSigCycleTime" SG_ 384 SAS_SteeringAngleSpeed 10;
BA_ "GenSigInvalidValue" SG_ 384 SAS_SteeringAngleSpeed "255";
BA_ "GenSigCycleTime" SG_ 384 SAS_SteeringAngle 10;
BA_ "GenSigInvalidValue" SG_ 384 SAS_SteeringAngle "32767";
BA_ "GenSigCycleTime" SG_ 384 SAS_SASFailure 10;
BA_ "GenSigInvalidValue" SG_ 384 SAS_SASFailure "1";
BA_ "GenSigCycleTime" SG_ 384 SAS_Calibrated 10;
BA_ "GenSigCycleTime" SG_ 384 SAS_SteeringAngleValid 10;
BA_ "GenSigInvalidValue" SG_ 384 SAS_SteeringAngleValid "1";

BA_ "GenSigCycleTime" SG_ 342 PCU_TankTurn_Available 20;
BA_ "GenSigCycleTime" SG_ 342 PCU_CoastRgnTarWhlRearQlfr 20;
BA_ "GenSigCycleTime" SG_ 342 PCU_CoastRgnTarWhlRear 20;
BA_ "GenSigCycleTime" SG_ 342 PCU_CoastRgnTarWhlFrntQlfr 20;
BA_ "GenSigCycleTime" SG_ 342 PCU_CoastRgnTarWhlFrnt 20;

BA_ "GenSigCycleTime" SG_ 580 ACC_AEBSpeedDropLevel 20;
BA_ "GenSigCycleTime" SG_ 580 ADS__RollingCounter_244 20;
BA_ "GenSigCycleTime" SG_ 580 ADS_CRCCheck_244 20;
BA_ "GenSigCycleTime" SG_ 580 ADS_Authernticator_244 20;
BA_ "GenSigCycleTime" SG_ 580 ADS_ResetFlag_244 20;
BA_ "GenSigCycleTime" SG_ 580 ADS_MesssageCounter_244 20;
BA_ "GenSigCycleTime" SG_ 580 ACC_CRCCheck_25E 20;
BA_ "GenSigCycleTime" SG_ 580 ACC_RollingCounter_25E 20;
BA_ "GenSigCycleTime" SG_ 580 ACC_AEBCtrlType 20;
BA_ "GenSigCycleTime" SG_ 580 ACC_AEBVehilceHoldReq 20;
BA_ "GenSigCycleTime" SG_ 580 ACC_FCWActive 20;
BA_ "GenSigCycleTime" SG_ 580 ACC_PrefillActive 20;
BA_ "GenSigCycleTime" SG_ 580 ACC_AWBActive 20;
BA_ "GenSigCycleTime" SG_ 580 ACC_AWBlevel 20;
BA_ "GenSigCycleTime" SG_ 580 ACC_ABAActive 20;
BA_ "GenSigCycleTime" SG_ 580 ACC_ABAlevel 20;
BA_ "GenSigStartValue" SG_ 580 ACC_ABAlevel 3.000000;
BA_ "GenSigCycleTime" SG_ 580 ACC_AEBActive 20;
BA_ "GenSigCycleTime" SG_ 580 ACC_AEBTargetDeceleration 20;
BA_ "GenSigStartValue" SG_ 580 ACC_AEBTargetDeceleration 32000.000000;
BA_ "GenSigCycleTime" SG_ 580 ACC_CRCCheck_24E 20;
BA_ "GenSigCycleTime" SG_ 580 ACC_RollingCounter_24E 20;
BA_ "GenSigCycleTime" SG_ 580 ACC_Driveoff_Request 20;
BA_ "GenSigCycleTime" SG_ 580 ACC_ACCMode 20;
BA_ "GenSigInvalidValue" SG_ 580 ACC_ACCMode "7";
BA_ "GenSigCycleTime" SG_ 580 ACC_CDDActive 20;
BA_ "GenSigCycleTime" SG_ 580 ACC_EngineStartStopRequest 20;
BA_ "GenSigCycleTime" SG_ 580 ACC_DecToStop 20;
BA_ "GenSigCycleTime" SG_ 580 ACC_ACCTargetAcceleration 20;
BA_ "GenSigStartValue" SG_ 580 ACC_ACCTargetAcceleration 100.000000;

BA_ "GenSigCycleTime" SG_ 583 APA_PrecheckValid 20;
BA_ "GenSigCycleTime" SG_ 583 APA_Precheck 20;
BA_ "GenSigInvalidValue" SG_ 583 APA_Precheck "0";
BA_ "GenSigCycleTime" SG_ 583 APA_ESP_BrakeFunctionMode 20;
BA_ "GenSigInvalidValue" SG_ 583 APA_ESP_BrakeFunctionMode "0";
BA_ "GenSigCycleTime" SG_ 583 APA_CRCCheck_247 20;
BA_ "GenSigCycleTime" SG_ 583 APA_RollingCounter_247 20;
BA_ "GenSigCycleTime" SG_ 583 APA_IncreasePressureReq 20;
BA_ "GenSigInvalidValue" SG_ 583 APA_IncreasePressureReq "0";
BA_ "GenSigCycleTime" SG_ 583 APA_EmergenceBrake 20;
BA_ "GenSigInvalidValue" SG_ 583 APA_EmergenceBrake "0";
BA_ "GenSigCycleTime" SG_ 583 APA_HSAHDforbidden 20;
BA_ "GenSigInvalidValue" SG_ 583 APA_HSAHDforbidden "0";
BA_ "GenSigCycleTime" SG_ 583 APA_ESPDecompressionModel 20;
BA_ "GenSigInvalidValue" SG_ 583 APA_ESPDecompressionModel "0";
BA_ "GenSigCycleTime" SG_ 583 APA_PrefillReq 20;
BA_ "GenSigInvalidValue" SG_ 583 APA_PrefillReq "0";
BA_ "GenSigCycleTime" SG_ 583 APA_LSCAction 20;
BA_ "GenSigCycleTime" SG_ 583 APA_TargetAcceleration 20;
BA_ "GenSigStartValue" SG_ 583 APA_TargetAcceleration 100.000000;
BA_ "GenSigCycleTime" SG_ 583 APA_TargetAccelerationValid 20;
BA_ "GenSigInvalidValue" SG_ 583 APA_TargetAccelerationValid "0";
BA_ "GenSigCycleTime" SG_ 583 APA_EPBrequestValid 20;
BA_ "GenSigInvalidValue" SG_ 583 APA_EPBrequestValid "0";
BA_ "GenSigCycleTime" SG_ 583 APA_EPBrequest 20;
BA_ "GenSigInvalidValue" SG_ 583 APA_EPBrequest "0";

BA_ "GenSigCycleTime" SG_ 632 ESP_YawRateValid 20;
BA_ "GenSigCycleTime" SG_ 632 ESP_YawRate 20;
BA_ "GenSigInvalidValue" SG_ 632 ESP_YawRate "16383";
BA_ "GenSigCycleTime" SG_ 632 ESP_RollingCounter_278 20;
BA_ "GenSigCycleTime" SG_ 632 ESP_LongAccel 20;
BA_ "GenSigInvalidValue" SG_ 632 ESP_LongAccel "1023";
BA_ "GenSigCycleTime" SG_ 632 ESP_LatAccel 20;
BA_ "GenSigInvalidValue" SG_ 632 ESP_LatAccel "255";
BA_ "GenSigCycleTime" SG_ 632 ESP_CRCCheck_278 20;

BA_ "GenSigCycleTime" SG_ 349 SRS_CrashOutputStatusforMCB 10;
BA_ "GenSigInvalidValue" SG_ 349 SRS_CrashOutputStatusforMCB "3";
BA_ "GenSigCycleTime" SG_ 349 ESP_IMUCalibrated 10;
BA_ "GenSigCycleTime" SG_ 349 ESP_YawRateValid 10;
BA_ "GenSigCycleTime" SG_ 349 ESP_LatAccelValid 10;
BA_ "GenSigCycleTime" SG_ 349 ESP_LongAccelValid 10;
BA_ "GenSigCycleTime" SG_ 349 ESP_YawRate 10;
BA_ "GenSigInvalidValue" SG_ 349 ESP_YawRate "16383";
BA_ "GenSigCycleTime" SG_ 349 ESP_RollingCounter_278 10;
BA_ "GenSigCycleTime" SG_ 349 ESP_LongAccel 10;
BA_ "GenSigInvalidValue" SG_ 349 ESP_LongAccel "1023";
BA_ "GenSigCycleTime" SG_ 349 ESP_LatAccel 10;
BA_ "GenSigInvalidValue" SG_ 349 ESP_LatAccel "255";
BA_ "GenSigCycleTime" SG_ 349 ESP_CRCCheck_278 10;

BA_ "GenSigCycleTime" SG_ 862 ACC_CRCCheck_35E 100;
BA_ "GenSigCycleTime" SG_ 862 ACC_RollingCounter_35E 100;
BA_ "GenSigCycleTime" SG_ 862 ACC_ACCEPBrequest 100;

BA_ "GenSigCycleTime" SG_ 823 PowercycleIBCU 100;
BA_ "GenSigInvalidValue" SG_ 823 PowercycleIBCU "NA";
BA_ "GenSigCycleTime" SG_ 823 VoltageVR 100;
BA_ "GenSigInvalidValue" SG_ 823 VoltageVR "NA";
BA_ "GenSigCycleTime" SG_ 823 VoltageUB 100;
BA_ "GenSigInvalidValue" SG_ 823 VoltageUB "NA";
BA_ "GenSigCycleTime" SG_ 823 ESP_EpbReqAvl 100;
BA_ "GenSigInvalidValue" SG_ 823 ESP_EpbReqAvl "NA";
BA_ "GenSigCycleTime" SG_ 823 IBCU_BrkSysFltLamp 100;
BA_ "GenSigCycleTime" SG_ 823 ESC_ATSReqEnable 100;
BA_ "GenSigCycleTime" SG_ 823 ESC_ATSDrivingModeStatus 100;
BA_ "GenSigCycleTime" SG_ 823 ESP_RollerbenchEnable 100;
BA_ "GenSigCycleTime" SG_ 823 ESP_WheelSpdSensorError 100;
BA_ "GenSigCycleTime" SG_ 823 ESP_WheelSpdSensorEcuError 100;
BA_ "GenSigCycleTime" SG_ 823 ESP_VGH_Status 100;
BA_ "GenSigCycleTime" SG_ 823 ESP_VGH_Available 100;
BA_ "GenSigCycleTime" SG_ 823 ESP_TPMSresetstatus 100;
BA_ "GenSigCycleTime" SG_ 823 ESP_TPMS_WarningStatus 100;
BA_ "GenSigCycleTime" SG_ 823 ESP_TPMS_MalfunctionStatus 100;
BA_ "GenSigCycleTime" SG_ 823 ESP_RRWheelSpdSensorSigFailure 100;
BA_ "GenSigCycleTime" SG_ 823 ESP_RRWheelSpdSensorFailure 100;
BA_ "GenSigCycleTime" SG_ 823 ESP_RRWheelSpdSensor_ShtBAT 100;
BA_ "GenSigCycleTime" SG_ 823 ESP_RRWheelSpdSensor_Open 100;
BA_ "GenSigCycleTime" SG_ 823 ESP_RRWheelSpdSensor_GND 100;
BA_ "GenSigCycleTime" SG_ 823 ESP_RollingCounter_508 100;
BA_ "GenSigCycleTime" SG_ 823 ESP_RLWheelSpdSensorSigFailure 100;
BA_ "GenSigCycleTime" SG_ 823 ESP_RLWheelSpdSensorFailure 100;
BA_ "GenSigCycleTime" SG_ 823 ESP_RLWheelSpdSensor_ShtBAT 100;
BA_ "GenSigCycleTime" SG_ 823 ESP_RLWheelSpdSensor_Open 100;
BA_ "GenSigCycleTime" SG_ 823 ESP_RLWheelSpdSensor_GND 100;
BA_ "GenSigCycleTime" SG_ 823 ESP_RearRghtWheelStatus 100;
BA_ "GenSigCycleTime" SG_ 823 ESP_RearLeftWheelStatus 100;
BA_ "GenSigCycleTime" SG_ 823 EPBi_ResetSts 100;
BA_ "GenSigInvalidValue" SG_ 823 EPBi_ResetSts "7";
BA_ "GenSigCycleTime" SG_ 823 ESP_FRWheelSpdSensorSigFailure 100;
BA_ "GenSigCycleTime" SG_ 823 ESP_FRWheelSpdSensorFailure 100;
BA_ "GenSigCycleTime" SG_ 823 ESP_FRWheelSpdSensor_ShtBAT 100;
BA_ "GenSigCycleTime" SG_ 823 ESP_FRWheelSpdSensor_Open 100;
BA_ "GenSigCycleTime" SG_ 823 ESP_FRWheelSpdSensor_GND 100;
BA_ "GenSigCycleTime" SG_ 823 ESP_FrontRightWheelStatus 100;
BA_ "GenSigCycleTime" SG_ 823 ESP_FrontLeftWheelStatus 100;
BA_ "GenSigCycleTime" SG_ 823 ESP_FLWheelSpdSensorSigFailure 100;
BA_ "GenSigCycleTime" SG_ 823 ESP_FLWheelSpdSensorFailure 100;
BA_ "GenSigCycleTime" SG_ 823 ESP_FLWheelSpdSensor_ShtBAT 100;
BA_ "GenSigCycleTime" SG_ 823 ESP_FLWheelSpdSensor_Open 100;
BA_ "GenSigCycleTime" SG_ 823 ESP_FLWheelSpdSensor_GND 100;
BA_ "GenSigCycleTime" SG_ 823 ESP_CRCCheck_508 100;
BA_ "GenSigCycleTime" SG_ 823 IBCU_CST_FunctionSwitch 100;
BA_ "GenSigCycleTime" SG_ 823 ESP_AWD_ModeRequest 100;
BA_ "GenSigCycleTime" SG_ 823 ESP_ATS_PtrotectMode 100;
BA_ "GenSigCycleTime" SG_ 823 ESP_ATS_ATB_Failure 100;
BA_ "GenSigCycleTime" SG_ 823 ESP_ATS_EPBi_Failure 100;
BA_ "GenSigCycleTime" SG_ 823 ESP_ATS_AWD_Failure 100;
BA_ "GenSigCycleTime" SG_ 823 ESP_ATS_TCU_Failure 100;
BA_ "GenSigCycleTime" SG_ 823 ESP_ATS_EMS_Failure 100;
BA_ "GenSigCycleTime" SG_ 823 EPB_CRCCheck_34F 100;
BA_ "GenSigCycleTime" SG_ 823 EPB_RollingCounter_34F 100;
BA_ "GenSigCycleTime" SG_ 823 ESC_ATSReqEnable 100;
BA_ "GenSigCycleTime" SG_ 823 ESP_ATS_DriveModeRequest 100;
BA_ "GenSigInvalidValue" SG_ 823 ESP_ATS_DriveModeRequest "15";
BA_ "GenSigCycleTime" SG_ 823 ESC_ATSDrivingModeStatus 100;
BA_ "GenSigInvalidValue" SG_ 823 ESC_ATSDrivingModeStatus "15";

BA_ "GenSigCycleTime" SG_ 870 AC_EnvironmentalTemp 100;
BA_ "GenSigStartValue" SG_ 870 AC_EnvironmentalTemp 255.000000;
BA_ "GenSigInvalidValue" SG_ 870 AC_EnvironmentalTemp "255";
BA_ "GenSigCycleTime" SG_ 870 AC_EnvironmentalTempVD 100;
BA_ "GenSigInvalidValue" SG_ 870 AC_EnvironmentalTempVD "1";

BA_ "GenSigCycleTime" SG_ 1302 HU_RollerbenchSetStaus 1000;
BA_ "GenSigCycleTime" SG_ 1302 HU_LocalTimeSystem 1000;
BA_ "GenSigCycleTime" SG_ 1302 HU_LocalTimeSecond 1000;
BA_ "GenSigInvalidValue" SG_ 1302 HU_LocalTimeSecond "0";
BA_ "GenSigCycleTime" SG_ 1302 HU_LocalTimeMinute 1000;
BA_ "GenSigInvalidValue" SG_ 1302 HU_LocalTimeMinute "0";
BA_ "GenSigCycleTime" SG_ 1302 HU_LocalTimeHour 1000;
BA_ "GenSigInvalidValue" SG_ 1302 HU_LocalTimeHour "0";
BA_ "GenSigCycleTime" SG_ 1302 HU_LocalTimeDate 1000;
BA_ "GenSigStartValue" SG_ 1302 HU_LocalTimeDate 1.000000;
BA_ "GenSigInvalidValue" SG_ 1302 HU_LocalTimeDate "1";
BA_ "GenSigCycleTime" SG_ 1302 HU_LocalTimeYear 1000;
BA_ "GenSigInvalidValue" SG_ 1302 HU_LocalTimeYear "0";
BA_ "GenSigCycleTime" SG_ 1302 HU_LocalTimeMonth 1000;
BA_ "GenSigStartValue" SG_ 1302 HU_LocalTimeMonth 1.000000;
BA_ "GenSigInvalidValue" SG_ 1302 HU_LocalTimeMonth "1";
BA_ "GenSigCycleTime" SG_ 1302 HU_LocalTimeValid 1000;
BA_ "GenSigInvalidValue" SG_ 1302 HU_LocalTimeValid "1";

BA_ "GenSigCycleTime" SG_ 1328 IP_TotalOdometer 500;
BA_ "GenSigInvalidValue" SG_ 1328 IP_TotalOdometer "16777215";
BA_ "GenSigCycleTime" SG_ 1328 IP_EngineOffTime 500;
BA_ "GenSigInvalidValue" SG_ 1328 IP_EngineOffTime "65535";

BA_ "GenSigCycleTime" SG_ 378 IBCU_MCB_availalbe 10;
BA_ "GenSigCycleTime" SG_ 378 IBCU_MCB_Active 10;
BA_ "GenSigCycleTime" SG_ 378 ESP_TankTurn_EngTorqIncRearActive 10;
BA_ "GenSigCycleTime" SG_ 378 ESP_TankTurn_TorqIncwhlRear 10;
BA_ "GenSigInvalidValue" SG_ 378 ESP_TankTurn_TorqIncwhlRear "32767";
BA_ "GenSigCycleTime" SG_ 378 ESP_TankTurn_EngTorqIncFrontActive 10;
BA_ "GenSigCycleTime" SG_ 378 ESP_TankTurn_TorqIncwhlFront 10;
BA_ "GenSigInvalidValue" SG_ 378 ESP_TankTurn_TorqIncwhlFront "32767";
BA_ "GenSigCycleTime" SG_ 378 IBCU_TankTurn_Status 10;
BA_ "GenSigCycleTime" SG_ 378 IBCU_BrkPedlTrvlDrvrVld 10;
BA_ "GenSigInvalidValue" SG_ 378 IBCU_BrkPedlTrvlDrvrVld "2";
BA_ "GenSigCycleTime" SG_ 378 IBCU_BrkPedlTrvlDrvr 10;
BA_ "GenSigStartValue" SG_ 378 IBCU_BrkPedlTrvlDrvr 320.000000;
BA_ "GenSigInvalidValue" SG_ 378 IBCU_BrkPedlTrvlDrvr "4095";
BA_ "GenSigCycleTime" SG_ 378 Wheel_Speed_RR_Data 10;
BA_ "GenSigInvalidValue" SG_ 378 Wheel_Speed_RR_Data "8191";
BA_ "GenSigCycleTime" SG_ 378 Wheel_Speed_RL_Valid_Data 10;
BA_ "GenSigInvalidValue" SG_ 378 Wheel_Speed_RL_Valid_Data "1";
BA_ "GenSigCycleTime" SG_ 378 Wheel_Speed_RL_Data 10;
BA_ "GenSigInvalidValue" SG_ 378 Wheel_Speed_RL_Data "8191";
BA_ "GenSigCycleTime" SG_ 378 Wheel_Speed_RR_Valid_Data 10;
BA_ "GenSigInvalidValue" SG_ 378 Wheel_Speed_RR_Valid_Data "1";
BA_ "GenSigCycleTime" SG_ 378 ESP_VDCActive 10;
BA_ "GenSigCycleTime" SG_ 378 ESP_TCSActive 10;
BA_ "GenSigCycleTime" SG_ 378 IBCU_EdcFrntMotTarSpd 10;
BA_ "GenSigInvalidValue" SG_ 378 IBCU_EdcFrntMotTarSpd "65535";
BA_ "GenSigCycleTime" SG_ 378 IBCU_EdcReMotTarSpd 10;
BA_ "GenSigInvalidValue" SG_ 378 IBCU_EdcReMotTarSpd "65535";
BA_ "GenSigCycleTime" SG_ 378 IBCU_TcsFrntMotTarSpd 10;
BA_ "GenSigInvalidValue" SG_ 378 IBCU_TcsFrntMotTarSpd "65535";
BA_ "GenSigCycleTime" SG_ 378 IBCU_TcsReMotTarSpd 10;
BA_ "GenSigInvalidValue" SG_ 378 IBCU_TcsReMotTarSpd "65535";
BA_ "GenSigCycleTime" SG_ 378 ESP_ElectricBoostFailStatus 10;
BA_ "GenSigCycleTime" SG_ 378 ESP_MbRegenTarWhlTotalQlfr 10;
BA_ "GenSigCycleTime" SG_ 378 ESP_MbRegenTarWhlTotal 10;
BA_ "GenSigInvalidValue" SG_ 378 ESP_MbRegenTarWhlTotal "65535";
BA_ "GenSigCycleTime" SG_ 378 ESP_RollerbenchType 10;
BA_ "GenSigCycleTime" SG_ 378 IBCU_BrakeFluid_Warning 10;
BA_ "GenSigInvalidValue" SG_ 378 IBCU_BrakeFluid_Warning "3";
BA_ "GenSigCycleTime" SG_ 378 ESP_RollingCounter_17A 10;
BA_ "GenSigCycleTime" SG_ 378 ESP_CRCCheck_17A 10;
BA_ "GenSigCycleTime" SG_ 378 ESP_VehicleSpeedValid2 10;
BA_ "GenSigCycleTime" SG_ 378 ESP_VehicleSpeedValid 10;
BA_ "GenSigInvalidValue" SG_ 378 ESP_VehicleSpeedValid "1";
BA_ "GenSigCycleTime" SG_ 378 ESP_VehicleSpeed2 10;
BA_ "GenSigCycleTime" SG_ 378 ESP_VehicleSpeed 10;
BA_ "GenSigInvalidValue" SG_ 378 ESP_VehicleSpeed "8191";
BA_ "GenSigCycleTime" SG_ 378 ESP_TqDecSlowwhlRear 10;
BA_ "GenSigCycleTime" SG_ 378 ESP_TqDecSlowwhlFront 10;
BA_ "GenSigCycleTime" SG_ 378 ESP_TqDecFastwhlFront 10;
BA_ "GenSigCycleTime" SG_ 378 ESP_TorqIncwhlRear 10;
BA_ "GenSigCycleTime" SG_ 378 ESP_TorqIncwhlFront 10;
BA_ "GenSigCycleTime" SG_ 378 ESP_TCSFailStatus 10;
BA_ "GenSigCycleTime" SG_ 378 ESP_RollingCounter_1DF 10;
BA_ "GenSigCycleTime" SG_ 378 ESP_RollingCounter_1C8 10;
BA_ "GenSigCycleTime" SG_ 378 ESP_RollingCounter_1AC 10;
BA_ "GenSigCycleTime" SG_ 378 ESP_RollingCounter_197 10;
BA_ "GenSigCycleTime" SG_ 378 ESP_RollingCounter_187 10;
BA_ "GenSigCycleTime" SG_ 378 ESP_pMcVirtual_Q 10;
BA_ "GenSigCycleTime" SG_ 378 ESP_pMcVirtual 10;
BA_ "GenSigCycleTime" SG_ 378 ESP_MbRegenTarWhlRearQlfr 10;
BA_ "GenSigCycleTime" SG_ 378 ESP_MbRegenTarWhlRear 10;
BA_ "GenSigCycleTime" SG_ 378 ESP_MbRegenTarWhlFrontQlfr 10;
BA_ "GenSigCycleTime" SG_ 378 ESP_MbRegenTarWhlFront 10;
BA_ "GenSigCycleTime" SG_ 378 ESP_GearHoldRequestValid 10;
BA_ "GenSigCycleTime" SG_ 378 ESP_GearHoldRequest 10;
BA_ "GenSigInvalidValue" SG_ 378 ESP_GearHoldRequest "0";
BA_ "GenSigCycleTime" SG_ 378 ESP_ESPFunctionStatus 10;
BA_ "GenSigStartValue" SG_ 378 ESP_ESPFunctionStatus 1.000000;
BA_ "GenSigCycleTime" SG_ 378 ESP_ESPActiveStatus 10;
BA_ "GenSigCycleTime" SG_ 378 ESP_EngTorqIncRearActive 10;
BA_ "GenSigCycleTime" SG_ 378 ESP_EngTorqIncFrontActive 10;
BA_ "GenSigCycleTime" SG_ 378 ESP_EngTorqDecRearActive 10;
BA_ "GenSigCycleTime" SG_ 378 ESP_EngTorqDecFrontActive 10;
BA_ "GenSigCycleTime" SG_ 378 ESP_EngTorqDecActive 10;
BA_ "GenSigCycleTime" SG_ 378 ESP_EBDFailStatus 10;
BA_ "GenSigCycleTime" SG_ 378 ESP_CRCCheck_1DF 10;
BA_ "GenSigCycleTime" SG_ 378 ESP_CRCCheck_1C8 10;
BA_ "GenSigCycleTime" SG_ 378 ESP_CRCCheck_1AC 10;
BA_ "GenSigCycleTime" SG_ 378 ESP_CRCCheck_197 10;
BA_ "GenSigCycleTime" SG_ 378 ESP_CRCCheck_187 10;
BA_ "GenSigCycleTime" SG_ 378 ESP_ABSFailStatus 10;
BA_ "GenSigCycleTime" SG_ 378 ESP_ABSActiveStatus 10;
BA_ "GenSigCycleTime" SG_ 378 EPBi_MILReq 10;
BA_ "GenSigCycleTime" SG_ 378 EPBi_ClearDiagnosticInfo 10;
BA_ "GenSigCycleTime" SG_ 378 EPB_ClutchSensor 10;
BA_ "GenSigInvalidValue" SG_ 378 EPB_ClutchSensor "127";

BA_ "GenSigCycleTime" SG_ 381 PCU_MbRegenWhlTotalVld 10;
BA_ "GenSigCycleTime" SG_ 381 PCU_MbRegenWhlTotal 10;
BA_ "GenSigInvalidValue" SG_ 381 PCU_MbRegenWhlTotal "65535";
BA_ "GenSigCycleTime" SG_ 381 PCU_ReWhlReqTqVld 10;
BA_ "GenSigInvalidValue" SG_ 381 PCU_ReWhlReqTqVld "1";
BA_ "GenSigCycleTime" SG_ 381 PCU_FrntWhlReqTqVld 10;
BA_ "GenSigInvalidValue" SG_ 381 PCU_FrntWhlReqTqVld "1";
BA_ "GenSigCycleTime" SG_ 381 PCU_ReWhlActTqVld 10;
BA_ "GenSigInvalidValue" SG_ 381 PCU_ReWhlActTqVld "1";
BA_ "GenSigCycleTime" SG_ 381 PCU_FrntWhlActTqVld 10;
BA_ "GenSigInvalidValue" SG_ 381 PCU_FrntWhlActTqVld "1";
BA_ "GenSigCycleTime" SG_ 381 PCU_MbRegenMaxRearWhlVld 10;
BA_ "GenSigCycleTime" SG_ 381 PCU_RollingCounter_1C4 10;
BA_ "GenSigCycleTime" SG_ 381 PCU_RearMotSts 10;
BA_ "GenSigCycleTime" SG_ 381 PCU_PwrIndcdRealTqRearWhl 10;
BA_ "GenSigInvalidValue" SG_ 381 PCU_PwrIndcdRealTqRearWhl "32767";
BA_ "GenSigCycleTime" SG_ 381 PCU_PwrIndcdDrvrReqTqWhlRear 10;
BA_ "GenSigInvalidValue" SG_ 381 PCU_PwrIndcdDrvrReqTqWhlRear "32767";
BA_ "GenSigCycleTime" SG_ 381 PCU_ESPTqReqAvlRear 10;
BA_ "GenSigCycleTime" SG_ 381 PCU_CRCCheck_1C4 10;
BA_ "GenSigCycleTime" SG_ 381 PCU_RollingCounter_1BE 10;
BA_ "GenSigCycleTime" SG_ 381 PCU_MbRegenWhlRear 10;
BA_ "GenSigInvalidValue" SG_ 381 PCU_MbRegenWhlRear "65535";
BA_ "GenSigCycleTime" SG_ 381 PCU_MbRegenMaxWhlTotal 10;
BA_ "GenSigInvalidValue" SG_ 381 PCU_MbRegenMaxWhlTotal "65535";
BA_ "GenSigCycleTime" SG_ 381 PCU_MbRegenMaxRearWhl 10;
BA_ "GenSigInvalidValue" SG_ 381 PCU_MbRegenMaxRearWhl "65535";
BA_ "GenSigCycleTime" SG_ 381 PCU_CRCCheck_1BE 10;
BA_ "GenSigCycleTime" SG_ 381 PCU_PwrTrainSts 10;
BA_ "GenSigInvalidValue" SG_ 381 PCU_PwrTrainSts "3";
BA_ "GenSigCycleTime" SG_ 381 PCU_BrkPedlSts 10;
BA_ "GenSigCycleTime" SG_ 381 PCU_RollingCounter_1A6 10;
BA_ "GenSigCycleTime" SG_ 381 PCU_MbRegenWhlFront 10;
BA_ "GenSigInvalidValue" SG_ 381 PCU_MbRegenWhlFront "65535";
BA_ "GenSigCycleTime" SG_ 381 PCU_MbRegenMaxWhlQlfr 10;
BA_ "GenSigCycleTime" SG_ 381 PCU_MbRegenMaxFrontWhlVld 10;
BA_ "GenSigCycleTime" SG_ 381 PCU_MbRegenMaxFrontWhl 10;
BA_ "GenSigCycleTime" SG_ 381 PCU_CRCCheck_1A6 10;
BA_ "GenSigCycleTime" SG_ 381 PCU_AccPedlVld 10;
BA_ "GenSigCycleTime" SG_ 381 PCU_AccPedl 10;
BA_ "GenSigCycleTime" SG_ 381 PCU_RollingCounter_211 10;
BA_ "GenSigCycleTime" SG_ 381 PCU_RearMotStsVld 10;
BA_ "GenSigCycleTime" SG_ 381 PCU_PwrIndcdRealTqFrontWhl 10;
BA_ "GenSigInvalidValue" SG_ 381 PCU_PwrIndcdRealTqFrontWhl "32767";
BA_ "GenSigCycleTime" SG_ 381 PCU_PwrIndcdDrvrReqTqWhlFront 10;
BA_ "GenSigInvalidValue" SG_ 381 PCU_PwrIndcdDrvrReqTqWhlFront "32767";
BA_ "GenSigCycleTime" SG_ 381 PCU_FrontMotStsVld 10;
BA_ "GenSigCycleTime" SG_ 381 PCU_FrontMotSts 10;
BA_ "GenSigCycleTime" SG_ 381 PCU_ESPTqReqAvlFront 10;
BA_ "GenSigCycleTime" SG_ 381 PCU_CRCCheck_211 10;
BA_ "GenSigCycleTime" SG_ 381 PCU_TarGearReqValid 10;
BA_ "GenSigCycleTime" SG_ 381 PCU_TarGearReq 10;
BA_ "GenSigInvalidValue" SG_ 381 PCU_TarGearReq "15";
BA_ "GenSigCycleTime" SG_ 381 PCU_RollingCounter_1C6 10;
BA_ "GenSigCycleTime" SG_ 381 PCU_RealAccPedlVld 10;
BA_ "GenSigCycleTime" SG_ 381 PCU_RealAccPedl 10;
BA_ "GenSigCycleTime" SG_ 381 PCU_CRCCheck_1C6 10;

BA_ "GenSigCycleTime" SG_ 459 IBCU_ElectrodelessBrakeModeFeedBack 10;
BA_ "GenSigInvalidValue" SG_ 459 IBCU_ElectrodelessBrakeModeFeedBack "255";
BA_ "GenSigCycleTime" SG_ 459 IBCU_ESPTSMAvlSts 10;
BA_ "GenSigInvalidValue" SG_ 459 IBCU_ESPTSMAvlSts "NA";
BA_ "GenSigCycleTime" SG_ 459 IBCU_ESPTSMAct 10;
BA_ "GenSigInvalidValue" SG_ 459 IBCU_ESPTSMAct "NA";
BA_ "GenSigCycleTime" SG_ 459 IBCU_EPBrequest 10;
BA_ "GenSigCycleTime" SG_ 459 IBCU_EPBrequestValid 10;
BA_ "GenSigCycleTime" SG_ 459 WhlPreLeReVld 10;
BA_ "GenSigStartValue" SG_ 459 WhlPreLeReVld 1.000000;
BA_ "GenSigCycleTime" SG_ 459 WhlPreRiReVld 10;
BA_ "GenSigStartValue" SG_ 459 WhlPreRiReVld 1.000000;
BA_ "GenSigCycleTime" SG_ 459 WhlPreLeFrntVld 10;
BA_ "GenSigStartValue" SG_ 459 WhlPreLeFrntVld 1.000000;
BA_ "GenSigCycleTime" SG_ 459 WhlPreRiFrntVld 10;
BA_ "GenSigStartValue" SG_ 459 WhlPreRiFrntVld 1.000000;
BA_ "GenSigCycleTime" SG_ 459 WheelPressureRearLeft_Model 10;
BA_ "GenSigInvalidValue" SG_ 459 WheelPressureRearLeft_Model "4095";
BA_ "GenSigCycleTime" SG_ 459 WheelPressureRearRight_Model 10;
BA_ "GenSigInvalidValue" SG_ 459 WheelPressureRearRight_Model "4095";
BA_ "GenSigCycleTime" SG_ 459 WheelPressureFrontLeft_Model 10;
BA_ "GenSigInvalidValue" SG_ 459 WheelPressureFrontLeft_Model "4095";
BA_ "GenSigCycleTime" SG_ 459 WheelPressureFrontRight_Model 10;
BA_ "GenSigInvalidValue" SG_ 459 WheelPressureFrontRight_Model "4095";
BA_ "GenSigCycleTime" SG_ 459 IBCU_BrkTqReqAvail 10;
BA_ "GenSigInvalidValue" SG_ 459 IBCU_BrkTqReqAvail "NA";
BA_ "GenSigCycleTime" SG_ 459 IBCU_HydBrkActvTq 10;
BA_ "GenSigInvalidValue" SG_ 459 IBCU_HydBrkActvTq "65535";
BA_ "GenSigCycleTime" SG_ 459 IBCU_DrvrBrkReqTqVID 10;
BA_ "GenSigInvalidValue" SG_ 459 IBCU_DrvrBrkReqTqVID "1";
BA_ "GenSigCycleTime" SG_ 459 IBCU_DrvrBrkReqTq 10;
BA_ "GenSigInvalidValue" SG_ 459 IBCU_DrvrBrkReqTq "65535";
BA_ "GenSigCycleTime" SG_ 459 IBCU_BrkReqTq 10;
BA_ "GenSigInvalidValue" SG_ 459 IBCU_BrkReqTq "65535";
BA_ "GenSigCycleTime" SG_ 459 IBCU_NBrkMode 10;
BA_ "GenSigCycleTime" SG_ 459 IBCU_System_Status 10;
BA_ "GenSigCycleTime" SG_ 459 IBCU_RollingCounter_1CB 10;
BA_ "GenSigCycleTime" SG_ 459 IBCU_CRCCheck_1CB 10;
BA_ "GenSigCycleTime" SG_ 459 IBCU_CST_Status 10;
BA_ "GenSigCycleTime" SG_ 459 IBCU_sOutputRodDriver_Q 10;
BA_ "GenSigCycleTime" SG_ 459 IBCU_sOutputRodDriver 10;
BA_ "GenSigCycleTime" SG_ 459 IBCU_sOutputRodAct_Q 10;
BA_ "GenSigCycleTime" SG_ 459 IBCU_sOutputRodAct 10;
BA_ "GenSigCycleTime" SG_ 459 IBCU_RollingCounter_237 10;
BA_ "GenSigCycleTime" SG_ 459 IBCU_RollingCounter_1CB 10;
BA_ "GenSigCycleTime" SG_ 459 IBCU_MILReq 10;
BA_ "GenSigCycleTime" SG_ 459 IBCU_ExtReqStatus 10;
BA_ "GenSigCycleTime" SG_ 459 IBCU_ExtReqPrio 10;
BA_ "GenSigCycleTime" SG_ 459 IBCU_eBESCCompatibilityIndex 10;
BA_ "GenSigCycleTime" SG_ 459 IBCU_eBDiagActive 10;
BA_ "GenSigCycleTime" SG_ 459 IBCU_CRCCheck_237 10;
BA_ "GenSigCycleTime" SG_ 459 IBCU_CRCCheck_1CB 10;
BA_ "GenSigCycleTime" SG_ 459 IBCU_ClearDiagnosticInfo 10;
BA_ "GenSigCycleTime" SG_ 459 IBCU_BrakePedalApplied_Q 10;
BA_ "GenSigCycleTime" SG_ 459 IBCU_BrakePedalApplied 10;
BA_ "GenSigCycleTime" SG_ 459 IBCU_BrakeModeFeedBack 10;
BA_ "GenSigCycleTime" SG_ 459 IBCU_BrakeModeEnable 10;

BA_ "GenSigCycleTime" SG_ 523 IBCU_Version 20;
BA_ "GenSigInvalidValue" SG_ 523 IBCU_Version "255";
BA_ "GenSigCycleTime" SG_ 523 IBCU_DMCIncTarSpd 20;
BA_ "GenSigStartValue" SG_ 523 IBCU_DMCIncTarSpd 30000.000000;
BA_ "GenSigInvalidValue" SG_ 523 IBCU_DMCIncTarSpd "30000";
BA_ "GenSigCycleTime" SG_ 523 IBCU_DMCIncCtrlMod 20;
BA_ "GenSigInvalidValue" SG_ 523 IBCU_DMCIncCtrlMod "3";
BA_ "GenSigCycleTime" SG_ 523 IBCU_DMCDecTarSpd 20;
BA_ "GenSigStartValue" SG_ 523 IBCU_DMCDecTarSpd 30000.000000;
BA_ "GenSigInvalidValue" SG_ 523 IBCU_DMCDecTarSpd "30000";
BA_ "GenSigCycleTime" SG_ 523 IBCU_DMCDecCtrlMod 20;
BA_ "GenSigInvalidValue" SG_ 523 IBCU_DMCDecCtrlMod "3";
BA_ "GenSigCycleTime" SG_ 523 IBCU_BDC_Status 20;
BA_ "GenSigInvalidValue" SG_ 523 IBCU_BDC_Status "NA";
BA_ "GenSigCycleTime" SG_ 523 IBCU_BDCAvlblSts 20;
BA_ "GenSigStartValue" SG_ 523 IBCU_BDCAvlblSts 1.000000;
BA_ "GenSigInvalidValue" SG_ 523 IBCU_BDCAvlblSts "0";
BA_ "GenSigCycleTime" SG_ 523 IBCU_iDCS_State 20;
BA_ "GenSigInvalidValue" SG_ 523 IBCU_iDCS_State "NA";
BA_ "GenSigCycleTime" SG_ 523 IBCU_iDCSLevFd 20;
BA_ "GenSigInvalidValue" SG_ 523 IBCU_iDCSLevFd "NA";
BA_ "GenSigCycleTime" SG_ 523 IBCU_iDCSAvlblSts 20;
BA_ "GenSigInvalidValue" SG_ 523 IBCU_iDCSAvlblSts "NA";
BA_ "GenSigCycleTime" SG_ 523 ESP_CDD_Availablebysituaion 20;
BA_ "GenSigCycleTime" SG_ 523 IBCUVLA 20;
BA_ "GenSigStartValue" SG_ 523 IBCUVLA 3200.000000;
BA_ "GenSigInvalidValue" SG_ 523 IBCUVLA "8191";
BA_ "GenSigCycleTime" SG_ 523 ESP_AEBSpeedDropActive 20;
BA_ "GenSigCycleTime" SG_ 523 IBCU_TankTurn_EDLOpenSet 20;
BA_ "GenSigCycleTime" SG_ 523 IBCU_EBS_Status 20;
BA_ "GenSigInvalidValue" SG_ 523 IBCU_EBS_Status "15";
BA_ "GenSigCycleTime" SG_ 523 IBCU_TankTurn_Enable 20;
BA_ "GenSigCycleTime" SG_ 523 IBCU_TankTurn_Available 20;
BA_ "GenSigCycleTime" SG_ 523 ESP_VehicleStandstillVld 20;
BA_ "GenSigInvalidValue" SG_ 523 ESP_VehicleStandstillVld "NA";
BA_ "GenSigCycleTime" SG_ 523 IBCU_BrkPedlStsGbVld 20;
BA_ "GenSigInvalidValue" SG_ 523 IBCU_BrkPedlStsGbVld "2";
BA_ "GenSigCycleTime" SG_ 523 IBCU_BrkPedoplStsGb 20;
BA_ "GenSigInvalidValue" SG_ 523 IBCU_BrkPedoplStsGb "255";
BA_ "GenSigCycleTime" SG_ 523 ESP_EBDActive 20;
BA_ "GenSigCycleTime" SG_ 523 IBCU_DTCAvailable 20;
BA_ "GenSigCycleTime" SG_ 523 Wheel_Speed_FL_Pulse 20;
BA_ "GenSigInvalidValue" SG_ 523 Wheel_Speed_FL_Pulse "255";
BA_ "GenSigCycleTime" SG_ 523 Wheel_Speed_FR_Pulse 20;
BA_ "GenSigInvalidValue" SG_ 523 Wheel_Speed_FR_Pulse "255";
BA_ "GenSigCycleTime" SG_ 523 ESP_MasCylBraPreByDriver 20;
BA_ "GenSigInvalidValue" SG_ 523 ESP_MasCylBraPreByDriver "4095";
BA_ "GenSigCycleTime" SG_ 523 ESP_MasCylBraPreByDriverValid 20;
BA_ "GenSigCycleTime" SG_ 523 ESP_Vehicle_Speed_Reference 20;
BA_ "GenSigInvalidValue" SG_ 523 ESP_Vehicle_Speed_Reference "8191";
BA_ "GenSigCycleTime" SG_ 523 IBCU_precheckStatus 20;
BA_ "GenSigCycleTime" SG_ 523 ESP_PrefillforAPA_Available 20;
BA_ "GenSigCycleTime" SG_ 523 ESP_PrefillforAPA_active 20;
BA_ "GenSigCycleTime" SG_ 523 IBCU_BrakeDiscHighTempWarning 20;
BA_ "GenSigCycleTime" SG_ 523 Wheel_SpeedPulseTimeStamp_FL 20;
BA_ "GenSigCycleTime" SG_ 523 Wheel_SpeedPulseTimeStamp_FR 20;
BA_ "GenSigCycleTime" SG_ 523 ESP_DTV_Available 20;
BA_ "GenSigCycleTime" SG_ 523 ESP_DTV_Active 20;
BA_ "GenSigCycleTime" SG_ 523 ESP_RollingCounter_20B 20;
BA_ "GenSigCycleTime" SG_ 523 ESP_CRCCheck_20B 20;
BA_ "GenSigCycleTime" SG_ 523 Wheel_Speed_RR_Valid_Data 20;
BA_ "GenSigInvalidValue" SG_ 523 Wheel_Speed_RR_Valid_Data "1";
BA_ "GenSigCycleTime" SG_ 523 Wheel_Speed_RR_Pulse 20;
BA_ "GenSigInvalidValue" SG_ 523 Wheel_Speed_RR_Pulse "255";
BA_ "GenSigCycleTime" SG_ 523 Wheel_Speed_RR_Direction 20;
BA_ "GenSigCycleTime" SG_ 523 Wheel_Speed_RR_Data 20;
BA_ "GenSigInvalidValue" SG_ 523 Wheel_Speed_RR_Data "8191";
BA_ "GenSigCycleTime" SG_ 523 Wheel_Speed_RL_Valid_Data 20;
BA_ "GenSigInvalidValue" SG_ 523 Wheel_Speed_RL_Valid_Data "1";
BA_ "GenSigCycleTime" SG_ 523 Wheel_Speed_RL_Pulse 20;
BA_ "GenSigInvalidValue" SG_ 523 Wheel_Speed_RL_Pulse "255";
BA_ "GenSigCycleTime" SG_ 523 Wheel_Speed_RL_Direction 20;
BA_ "GenSigInvalidValue" SG_ 523 Wheel_Speed_RL_Direction "3";
BA_ "GenSigCycleTime" SG_ 523 Wheel_Speed_RL_Data 20;
BA_ "GenSigInvalidValue" SG_ 523 Wheel_Speed_RL_Data "8191";
BA_ "GenSigCycleTime" SG_ 523 Wheel_Speed_FR_Valid_Data 20;
BA_ "GenSigInvalidValue" SG_ 523 Wheel_Speed_FR_Valid_Data "1";
BA_ "GenSigCycleTime" SG_ 523 Wheel_Speed_FR_Pulse 20;
BA_ "GenSigInvalidValue" SG_ 523 Wheel_Speed_FR_Pulse "255";
BA_ "GenSigCycleTime" SG_ 523 Wheel_Speed_FR_Direction 20;
BA_ "GenSigInvalidValue" SG_ 523 Wheel_Speed_FR_Direction "3";
BA_ "GenSigCycleTime" SG_ 523 Wheel_Speed_FR_Data 20;
BA_ "GenSigInvalidValue" SG_ 523 Wheel_Speed_FR_Data "8191";
BA_ "GenSigCycleTime" SG_ 523 Wheel_Speed_FL_Valid_Data 20;
BA_ "GenSigInvalidValue" SG_ 523 Wheel_Speed_FL_Valid_Data "1";
BA_ "GenSigCycleTime" SG_ 523 Wheel_Speed_FL_Pulse 20;
BA_ "GenSigInvalidValue" SG_ 523 Wheel_Speed_FL_Pulse "255";
BA_ "GenSigCycleTime" SG_ 523 Wheel_Speed_FL_Direction 20;
BA_ "GenSigInvalidValue" SG_ 523 Wheel_Speed_FL_Direction "3";
BA_ "GenSigCycleTime" SG_ 523 Wheel_Speed_FL_Data 20;
BA_ "GenSigInvalidValue" SG_ 523 Wheel_Speed_FL_Data "8191";
BA_ "GenSigCycleTime" SG_ 523 ESP_VehicleStandstill 20;
BA_ "GenSigCycleTime" SG_ 523 ESP_VDCActive 20;
BA_ "GenSigCycleTime" SG_ 523 ESP_UrgencyBrakeAlarm 20;
BA_ "GenSigCycleTime" SG_ 523 ESP_TODTorqueMaxLimit 20;
BA_ "GenSigInvalidValue" SG_ 523 ESP_TODTorqueMaxLimit "4095";
BA_ "GenSigCycleTime" SG_ 523 ESP_TCSActive 20;
BA_ "GenSigCycleTime" SG_ 523 ESP_RollingCounter_277 20;
BA_ "GenSigCycleTime" SG_ 523 ESP_RollingCounter_258 20;
BA_ "GenSigCycleTime" SG_ 523 ESP_RollingCounter_208 20;
BA_ "GenSigCycleTime" SG_ 523 ESP_RollingCounter_206 20;
BA_ "GenSigCycleTime" SG_ 523 ESP_QDCACC 20;
BA_ "GenSigCycleTime" SG_ 523 ESP_PrefillAvailable 20;
BA_ "GenSigCycleTime" SG_ 523 ESP_PrefillActive 20;
BA_ "GenSigCycleTime" SG_ 523 ESP_OnlyABSActive 20;
BA_ "GenSigCycleTime" SG_ 523 ESP_MasCylBrakePressureValid 20;
BA_ "GenSigCycleTime" SG_ 523 ESP_MasCylBrakePressure 20;
BA_ "GenSigInvalidValue" SG_ 523 ESP_MasCylBrakePressure "4095";
BA_ "GenSigCycleTime" SG_ 523 ESP_IncreasePressureReqOK 20;
BA_ "GenSigInvalidValue" SG_ 523 ESP_IncreasePressureReqOK "0";
BA_ "GenSigCycleTime" SG_ 523 ESP_HHC_Available 20;
BA_ "GenSigCycleTime" SG_ 523 ESP_HHC_Active 20;
BA_ "GenSigCycleTime" SG_ 523 ESP_HDC_STATUS 20;
BA_ "GenSigInvalidValue" SG_ 523 ESP_HDC_STATUS "3";
BA_ "GenSigCycleTime" SG_ 523 ESP_ECDAvailable 20;
BA_ "GenSigCycleTime" SG_ 523 ESP_ECDActive 20;
BA_ "GenSigCycleTime" SG_ 523 ESP_CRCCheck_277 20;
BA_ "GenSigCycleTime" SG_ 523 ESP_CRCCheck_258 20;
BA_ "GenSigCycleTime" SG_ 523 ESP_CRCCheck_208 20;
BA_ "GenSigCycleTime" SG_ 523 ESP_CRCCheck_206 20;
BA_ "GenSigCycleTime" SG_ 523 ESP_CDD_Available_APA 20;
BA_ "GenSigCycleTime" SG_ 523 ESP_CDD_Available 20;
BA_ "GenSigCycleTime" SG_ 523 ESP_CDD_Active_APA 20;
BA_ "GenSigCycleTime" SG_ 523 ESP_CDD_Active 20;
BA_ "GenSigCycleTime" SG_ 523 ESP_BrakeOverHeatBrakeDiscTemp 20;
BA_ "GenSigCycleTime" SG_ 523 ESP_BrakeLightOnRequest 20;
BA_ "GenSigInvalidValue" SG_ 523 ESP_BrakeLightOnRequest "3";
BA_ "GenSigCycleTime" SG_ 523 ESP_BrakeForce 20;
BA_ "GenSigCycleTime" SG_ 523 ESP_AWBavailable 20;
BA_ "GenSigCycleTime" SG_ 523 ESP_AWBactive 20;
BA_ "GenSigCycleTime" SG_ 523 ESP_AutoHoldStandby 20;
BA_ "GenSigCycleTime" SG_ 523 ESP_AutoHoldAvailable 20;
BA_ "GenSigCycleTime" SG_ 523 ESP_AutoHoldActive 20;
BA_ "GenSigCycleTime" SG_ 523 ESP_AEBdecActive 20;
BA_ "GenSigCycleTime" SG_ 523 ESP_AEBAvailable 20;
BA_ "GenSigCycleTime" SG_ 523 ESP_ABAavailable 20;
BA_ "GenSigCycleTime" SG_ 523 ESP_ABAactive 20;
BA_ "GenSigCycleTime" SG_ 523 ABS_TODFastOpenRequest 20;
BA_ "GenSigInvalidValue" SG_ 523 ABS_TODFastOpenRequest "3";

BA_ "GenSigCycleTime" SG_ 650 IP_HandBrakeSwitch 40;

BA_ "GenSigCycleTime" SG_ 651 BCM_DrvrSts 40;
BA_ "GenSigInvalidValue" SG_ 651 BCM_DrvrSts "NA";
BA_ "GenSigCycleTime" SG_ 651 BCM_PowerStatusFeedback 40;
BA_ "GenSigCycleTime" SG_ 651 BCM_DriverDoorStatus 40;

BA_ "GenSigCycleTime" SG_ 724 APA_ReleasePressureReq 40;
BA_ "GenSigInvalidValue" SG_ 724 APA_ReleasePressureReq "0";

BA_ "GenSigCycleTime" SG_ 721 BCM_ReversePosition 40;

BA_ "GenSigSendType" SG_ 758 HU_IndirectTPMSReset 1;

BA_ "GenSigCycleTime" SG_ 827 PCU_SnowModelStatus 100;
BA_ "GenSigCycleTime" SG_ 827 PCU_OffRoadCrpTarSpd 100;
BA_ "GenSigInvalidValue" SG_ 827 PCU_OffRoadCrpTarSpd "31";
BA_ "GenSigCycleTime" SG_ 827 PCU_OffRoadCrpSts 100;
BA_ "GenSigCycleTime" SG_ 827 PCU_TowingMode 100;
BA_ "GenSigCycleTime" SG_ 827 PCU_DrvModVld 100;
BA_ "GenSigCycleTime" SG_ 827 PCU_DrvMod 100;
BA_ "GenSigCycleTime" SG_ 827 PCU_RollingCounter_341 100;
BA_ "GenSigCycleTime" SG_ 827 PCU_PwrTqWhMinTotal 100;
BA_ "GenSigCycleTime" SG_ 827 PCU_PwrTqWhMaxTotal 100;
BA_ "GenSigCycleTime" SG_ 827 PCU_CRCCheck_341 100;
BA_ "GenSigCycleTime" SG_ 827 PCU_RollingCounter_311 100;
BA_ "GenSigCycleTime" SG_ 827 PCU_PwrTqWhRearMin 100;
BA_ "GenSigCycleTime" SG_ 827 PCU_PwrTqWhRearMax 100;
BA_ "GenSigCycleTime" SG_ 827 PCU_PwrTqWhFrontMin 100;
BA_ "GenSigCycleTime" SG_ 827 PCU_PwrTqWhFrontMax 100;
BA_ "GenSigCycleTime" SG_ 827 PCU_CRCCheck_311 100;

BA_ "GenSigCycleTime" SG_ 916 HU_CdcEpbSwtSet 100;
BA_ "GenSigInvalidValue" SG_ 916 HU_CdcEpbSwtSet "NA";
BA_ "GenSigCycleTime" SG_ 916 HU_CST_FunctionSwitch 100;
BA_ "GenSigCycleTime" SG_ 916 HU_BrakeModeSetStaus 100;

BA_ "GenSigCycleTime" SG_ 1021 BCM_PowerManageLevel 100;
BA_ "GenSigInvalidValue" SG_ 1021 BCM_PowerManageLevel "7";

BA_ "GenSigSendType" SG_ 1326 IP_IndirectTPMSReset 1;

BA_ "GenSigCycleTime" SG_ 1706 EPBi_DTC2_Status 500;
BA_ "GenSigCycleTime" SG_ 1706 EPBi_DTC2_MiddByte 500;
BA_ "GenSigCycleTime" SG_ 1706 EPBi_DTC2_LowByte 500;
BA_ "GenSigCycleTime" SG_ 1706 EPBi_DTC2_HighByte 500;
BA_ "GenSigCycleTime" SG_ 1706 EPBi_DTC1_Status 500;
BA_ "GenSigCycleTime" SG_ 1706 EPBi_DTC1_MiddByte 500;
BA_ "GenSigCycleTime" SG_ 1706 EPBi_DTC1_LowByte 500;
BA_ "GenSigCycleTime" SG_ 1706 EPBi_DTC1_HighByte 500;

BA_ "GenSigSendType" SG_ 1056 NM_message420 1;

BA_ "GenSigCycleTime" SG_ 1410 EPBI_NotSleep_BYTE7BIT6 1000;
BA_ "GenSigCycleTime" SG_ 1410 EPBI_NotSleep_BYTE7BIT5 1000;
BA_ "GenSigCycleTime" SG_ 1410 EPBI_NotSleep_BYTE7BIT4 1000;
BA_ "GenSigCycleTime" SG_ 1410 EPBI_NotSleep_BYTE7BIT3 1000;
BA_ "GenSigCycleTime" SG_ 1410 EPBi_NotSleep_BYTE7BIT2 1000;
BA_ "GenSigCycleTime" SG_ 1410 EPBi_NotSleep_BYTE7BIT1 1000;
BA_ "GenSigCycleTime" SG_ 1410 EPBi_NotSleep_BYTE7BIT0 1000;
BA_ "GenSigCycleTime" SG_ 1410 EPBi_WakeUp_BYTE4BIT2 1000;
BA_ "GenSigCycleTime" SG_ 1410 EPBi_WakeUp_BYTE4BIT1 1000;
BA_ "GenSigCycleTime" SG_ 1410 EPBi_WakeUp_BYTE4BIT0 1000;

BA_ "GenSigCycleTime" SG_ 431 TCU_ShiftPostionValid 10;
BA_ "GenSigInvalidValue" SG_ 431 TCU_ShiftPostionValid "1";
BA_ "GenSigCycleTime" SG_ 431 TCU_ShiftInProgressVld 10;
BA_ "GenSigCycleTime" SG_ 431 TCU_ShiftInProgress 10;
BA_ "GenSigCycleTime" SG_ 431 TCU_RollingCounter_1A8 10;
BA_ "GenSigCycleTime" SG_ 431 TCU_GearShiftPosition 10;
BA_ "GenSigStartValue" SG_ 431 TCU_GearShiftPosition 13.000000;
BA_ "GenSigInvalidValue" SG_ 431 TCU_GearShiftPosition "15";
BA_ "GenSigCycleTime" SG_ 431 TCU_CRCCheck_1A8 10;
BA_ "GenSigCycleTime" SG_ 431 TCU_ActualDrivingGearValid 10;
BA_ "GenSigInvalidValue" SG_ 431 TCU_ActualDrivingGearValid "1";
BA_ "GenSigCycleTime" SG_ 431 TCU_ActualDrivingGear 10;
BA_ "GenSigInvalidValue" SG_ 431 TCU_ActualDrivingGear "15";

BA_ "GenSigCycleTime" SG_ 800 GW_OTAmode_Chks 100;
BA_ "GenSigInvalidValue" SG_ 800 GW_OTAmode_Chks "0";
BA_ "GenSigCycleTime" SG_ 800 GW_OTAmode_Cntr 100;
BA_ "GenSigInvalidValue" SG_ 800 GW_OTAmode_Cntr "0";
BA_ "GenSigCycleTime" SG_ 800 GW_OTAmode 100;
BA_ "GenSigInvalidValue" SG_ 800 GW_OTAmode "0";
BA_ "GenSigCycleTime" SG_ 800 GW_ResetReq 100;
BA_ "GenSigInvalidValue" SG_ 800 GW_ResetReq "127";

BA_ "GenSigSendType" SG_ 1563 KeyLearn_Authernticator_61B 1;
BA_ "GenSigSendType" SG_ 1563 KeyLearn_Random_61B 1;

BA_ "GenSigSendType" SG_ 429 GW_Authernticator_1AD 1;
BA_ "GenSigSendType" SG_ 429 GW_ResetCounter_1AD 1;
BA_ "GenSigSendType" SG_ 429 GW_TripCounter_1AD 1;

BA_ "GenSigCycleTime" SG_ 939 HU_AutoHoldStatusSetReq 100;
BA_ "GenSigCycleTime" SG_ 939 HU_HDCStatusSetReq 100;
BA_ "GenSigCycleTime" SG_ 939 HU_ESPStatusSetReq 100;

BA_ "GenSigSendType" SG_ 393 IBCU_ReqSecOCSYNMSG 1;

BA_ "GenSigCycleTime" SG_ 881 PCU_DrvMod2 100;
BA_ "GenSigCycleTime" SG_ 881 PCU_SpecialModeSetFB 100;

BA_ "GenSigCycleTime" SG_ 394 TCU_ParkingRequest 20;
BA_ "GenSigInvalidValue" SG_ 394 TCU_ParkingRequest "3";

BA_ "GenSigCycleTime" SG_ 266 EPB_BackupCapability 10;
BA_ "GenSigInvalidValue" SG_ 266 EPB_BackupCapability "NA";
BA_ "GenSigCycleTime" SG_ 266 EPB_ClampForce_Secondary 10;
BA_ "GenSigStartValue" SG_ 266 EPB_ClampForce_Secondary 29.000000;
BA_ "GenSigInvalidValue" SG_ 266 EPB_ClampForce_Secondary "31";
BA_ "GenSigCycleTime" SG_ 266 EPB_FailStatus_Secondary 10;
BA_ "GenSigInvalidValue" SG_ 266 EPB_FailStatus_Secondary "NA";
BA_ "GenSigCycleTime" SG_ 266 EPB_Status_Secondary 10;
BA_ "GenSigInvalidValue" SG_ 266 EPB_Status_Secondary "NA";
BA_ "GenSigCycleTime" SG_ 266 EPB_RollingCounter_10A 10;
BA_ "GenSigCycleTime" SG_ 266 EPB_CRCCheck_10A 10;
BA_ "GenSigCycleTime" SG_ 266 EpbCdpReq 10;
BA_ "GenSigInvalidValue" SG_ 266 EpbCdpReq "NA";
BA_ "GenSigCycleTime" SG_ 266 EPB_EAR_Available 10;
BA_ "GenSigInvalidValue" SG_ 266 EPB_EAR_Available "NA";
BA_ "GenSigCycleTime" SG_ 266 EPB_Status_Priamary 10;
BA_ "GenSigCycleTime" SG_ 266 EPB_FailStatus_Primary 10;
BA_ "GenSigCycleTime" SG_ 266 ESP_RWU_ParkingAvailForACC 10;
BA_ "GenSigCycleTime" SG_ 266 ESP_RWU_ParkingActiveForACC 10;
BA_ "GenSigStartValue" SG_ 266 ESP_RWU_ParkingActiveForACC 1.000000;
BA_ "GenSigCycleTime" SG_ 266 EPB_TextDisplay 10;
BA_ "GenSigInvalidValue" SG_ 266 EPB_TextDisplay "15";
BA_ "GenSigCycleTime" SG_ 266 EPB_SwitchPositionValid 10;
BA_ "GenSigStartValue" SG_ 266 EPB_SwitchPositionValid 1.000000;
BA_ "GenSigInvalidValue" SG_ 266 EPB_SwitchPositionValid "1";
BA_ "GenSigCycleTime" SG_ 266 EPB_SwitchPosition 10;
BA_ "GenSigInvalidValue" SG_ 266 EPB_SwitchPosition "3";
BA_ "GenSigCycleTime" SG_ 266 EPB_Status 10;
BA_ "GenSigCycleTime" SG_ 266 EPB_FunctionLamp 10;
BA_ "GenSigInvalidValue" SG_ 266 EPB_FunctionLamp "3";
BA_ "GenSigCycleTime" SG_ 266 EPB_FailureLamp 10;
BA_ "GenSigInvalidValue" SG_ 266 EPB_FailureLamp "3";
BA_ "GenSigCycleTime" SG_ 266 EPB_FailStatus 10;
BA_ "GenSigCycleTime" SG_ 266 EPB_APArequest_Available 10;
BA_ "GenSigCycleTime" SG_ 266 EPB_AchievedClampForce 10;
BA_ "GenSigStartValue" SG_ 266 EPB_AchievedClampForce 29.000000;
BA_ "GenSigInvalidValue" SG_ 266 EPB_AchievedClampForce "31";

BA_ "GenSigCycleTime" SG_ 958 EDL_LockSts 100;
BA_ "GenSigInvalidValue" SG_ 958 EDL_LockSts "3";
BA_ "GenSigCycleTime" SG_ 958 ATS_TargetDrivingMode 100;

BA_ "GenSigCycleTime" SG_ 815 PCU_AccPedlE 100;
BA_ "GenSigCycleTime" SG_ 815 PCU_AccPedlD 100;

BA_ "GenSigCycleTime" SG_ 274 EPB_CRCCheck_112 10;
BA_ "GenSigCycleTime" SG_ 274 EPB_RollingCounter_112 10;

BA_ "GenSigCycleTime" SG_ 586 ESL_DriverParkButtonFaultStatus 20;
BA_ "GenSigCycleTime" SG_ 586 ESL_DriverParkRequest 20;
BA_ "GenSigInvalidValue" SG_ 586 ESL_DriverParkRequest "3";

BA_ "GenSigCycleTime" SG_ 810 TRM_RollingCounter_32A 100;
BA_ "GenSigInvalidValue" SG_ 810 TRM_RollingCounter_32A "NA";
BA_ "GenSigCycleTime" SG_ 810 TRM_CRCCheck_32A 100;
BA_ "GenSigInvalidValue" SG_ 810 TRM_CRCCheck_32A "NA";
BA_ "GenSigCycleTime" SG_ 810 TRM_ConnectSts 100;
BA_ "GenSigInvalidValue" SG_ 810 TRM_ConnectSts "NA";

BA_ "GenSigCycleTime" SG_ 268 RMIPU_DMCTarTq 10;
BA_ "GenSigStartValue" SG_ 268 RMIPU_DMCTarTq 50000.000000;
BA_ "GenSigInvalidValue" SG_ 268 RMIPU_DMCTarTq "65535";
BA_ "GenSigCycleTime" SG_ 268 RMIPU_DMCCrtSts 10;
BA_ "GenSigInvalidValue" SG_ 268 RMIPU_DMCCrtSts "NA";
BA_ "GenSigCycleTime" SG_ 268 RMIPU_DMCVersion 10;
BA_ "GenSigInvalidValue" SG_ 268 RMIPU_DMCVersion "4095";
BA_ "GenSigCycleTime" SG_ 268 TM1_WheelTqReal 10;
BA_ "GenSigInvalidValue" SG_ 268 TM1_WheelTqReal "32767";
BA_ "GenSigCycleTime" SG_ 268 TM1_MotSpdVld 10;
BA_ "GenSigCycleTime" SG_ 268 TM1_MotSpd 10;
BA_ "GenSigStartValue" SG_ 268 TM1_MotSpd 25000.000000;
BA_ "GenSigInvalidValue" SG_ 268 TM1_MotSpd "65535";
BA_ "GenSigCycleTime" SG_ 268 TM1_CRCCheck_10C 10;
BA_ "GenSigCycleTime" SG_ 268 TM1_RollingCounter_10C 10;
BA_ "GenSigCycleTime" SG_ 268 TM1_MotTqRealVld 10;
BA_ "GenSigCycleTime" SG_ 268 TM1_OperMdl 10;

BA_ "GenSigCycleTime" SG_ 269 TM2_WheelTqReal 10;
BA_ "GenSigInvalidValue" SG_ 269 TM2_WheelTqReal "32767";
BA_ "GenSigCycleTime" SG_ 269 TM2_MotSpdVld 10;
BA_ "GenSigCycleTime" SG_ 269 TM2_MotSpd 10;
BA_ "GenSigStartValue" SG_ 269 TM2_MotSpd 25000.000000;
BA_ "GenSigInvalidValue" SG_ 269 TM2_MotSpd "65535";
BA_ "GenSigCycleTime" SG_ 269 TM2_CRCCheck_10D 10;
BA_ "GenSigCycleTime" SG_ 269 TM2_RollingCounter_10D 10;
BA_ "GenSigCycleTime" SG_ 269 TM2_OperMdl 10;
BA_ "GenSigCycleTime" SG_ 269 TM2_MotTqRealVld 10;

BA_ "GenSigCycleTime" SG_ 1341 HU_Poweroff 100;
BA_ "GenSigInvalidValue" SG_ 1341 HU_Poweroff "0";

BA_ "GenSigCycleTime" SG_ 842 HU_TankTurnStatusSetReq 100;

BA_ "GenSigCycleTime" SG_ 519 PCU_IDCSAvlSts 20;
BA_ "GenSigStartValue" SG_ 519 PCU_IDCSAvlSts 1.000000;
BA_ "GenSigInvalidValue" SG_ 519 PCU_IDCSAvlSts "0";
BA_ "GenSigCycleTime" SG_ 519 PCU_WhlBrkPReqRR 20;
BA_ "GenSigInvalidValue" SG_ 519 PCU_WhlBrkPReqRR "1023";
BA_ "GenSigCycleTime" SG_ 519 PCU_WhlBrkPReqLR 20;
BA_ "GenSigInvalidValue" SG_ 519 PCU_WhlBrkPReqLR "1023";
BA_ "GenSigCycleTime" SG_ 519 PCU_WhlBrkPReqRF 20;
BA_ "GenSigInvalidValue" SG_ 519 PCU_WhlBrkPReqRF "1023";
BA_ "GenSigCycleTime" SG_ 519 PCU_WhlBrkPReqLF 20;
BA_ "GenSigInvalidValue" SG_ 519 PCU_WhlBrkPReqLF "1023";

BA_ "GenSigSendType" SG_ 2015 Diagnose_message7DF 1;

BA_ "GenSigSendType" SG_ 1920 Diagnose_message780 1;

BA_ "GenSigSendType" SG_ 1928 Diagnose_message788 1;

BA_ "GenSigSendType" SG_ 2021 Diagnose_message7E5 1;

BA_ "GenSigSendType" SG_ 2029 Diagnose_message7ED 1;

BA_ "GenSigCycleTime" SG_ 977 PCU_CruiseCtrlSts 100;

BA_ "GenSigCycleTime" SG_ 574 EspSysSts 10;
BA_ "GenSigInvalidValue" SG_ 574 EspSysSts "NA";
BA_ "GenSigCycleTime" SG_ 574 IBCU_VoltageInfo_BeforeUBV_Mosfet 100;
BA_ "GenSigInvalidValue" SG_ 574 IBCU_VoltageInfo_BeforeUBV_Mosfet "NA";
BA_ "GenSigCycleTime" SG_ 574 IBCU_VoltageInfo_BeforeUBM_Mosfet 100;
BA_ "GenSigInvalidValue" SG_ 574 IBCU_VoltageInfo_BeforeUBM_Mosfet "NA";
BA_ "GenSigCycleTime" SG_ 574 IBCU_RSS_ValVol 100;
BA_ "GenSigInvalidValue" SG_ 574 IBCU_RSS_ValVol "NA";
BA_ "GenSigCycleTime" SG_ 574 IBCU_SimulatorCutValve_Cur 100;
BA_ "GenSigInvalidValue" SG_ 574 IBCU_SimulatorCutValve_Cur "NA";
BA_ "GenSigCycleTime" SG_ 574 IBCU_MasterCylinderCutValve2_Cur 100;
BA_ "GenSigInvalidValue" SG_ 574 IBCU_MasterCylinderCutValve2_Cur "NA";
BA_ "GenSigCycleTime" SG_ 574 IBCU_MasterCylinderCutValve1_Cur 100;
BA_ "GenSigInvalidValue" SG_ 574 IBCU_MasterCylinderCutValve1_Cur "NA";
BA_ "GenSigCycleTime" SG_ 574 IBCU_PressureCylinderCutValve2_Cur 100;
BA_ "GenSigInvalidValue" SG_ 574 IBCU_PressureCylinderCutValve2_Cur "NA";
BA_ "GenSigCycleTime" SG_ 574 IBCU_PressureCylinderCutValve1_Cur 100;
BA_ "GenSigInvalidValue" SG_ 574 IBCU_PressureCylinderCutValve1_Cur "NA";
BA_ "GenSigCycleTime" SG_ 574 IBCU_MotVol 100;
BA_ "GenSigInvalidValue" SG_ 574 IBCU_MotVol "NA";
BA_ "GenSigCycleTime" SG_ 574 IBCU_MotCtrlType 100;
BA_ "GenSigInvalidValue" SG_ 574 IBCU_MotCtrlType "NA";
BA_ "GenSigCycleTime" SG_ 574 IBCU_MotTorqAct 100;
BA_ "GenSigInvalidValue" SG_ 574 IBCU_MotTorqAct "NA";
BA_ "GenSigCycleTime" SG_ 574 IBCU_MotTorqCmd 100;
BA_ "GenSigInvalidValue" SG_ 574 IBCU_MotTorqCmd "NA";
BA_ "GenSigCycleTime" SG_ 574 IBCU_SpeedAct 100;
BA_ "GenSigInvalidValue" SG_ 574 IBCU_SpeedAct "NA";
BA_ "GenSigCycleTime" SG_ 574 IBCU_SpeedCmd 100;
BA_ "GenSigInvalidValue" SG_ 574 IBCU_SpeedCmd "NA";
BA_ "GenSigCycleTime" SG_ 574 IBCU_PistonPos 100;
BA_ "GenSigInvalidValue" SG_ 574 IBCU_PistonPos "NA";
BA_ "GenSigCycleTime" SG_ 574 IBCU_IdleCtrlType 100;
BA_ "GenSigInvalidValue" SG_ 574 IBCU_IdleCtrlType "NA";
BA_ "GenSigCycleTime" SG_ 574 IBCU_CtrlMode 100;
BA_ "GenSigInvalidValue" SG_ 574 IBCU_CtrlMode "NA";
BA_ "GenSigCycleTime" SG_ 574 IBCU_PressureCmd 100;
BA_ "GenSigInvalidValue" SG_ 574 IBCU_PressureCmd "NA";

BA_ "GenSigCycleTime" SG_ 691 HU_ESPStatusSetReq1 100;
BA_ "GenSigCycleTime" SG_ 691 HU_ElectrodelessBrakeModeSetStatus2 100;
BA_ "GenSigInvalidValue" SG_ 691 HU_ElectrodelessBrakeModeSetStatus2 "255";
BA_ "GenSigCycleTime" SG_ 691 HU_BDCSwtSet 100;
BA_ "GenSigInvalidValue" SG_ 691 HU_BDCSwtSet "NA";
BA_ "GenSigCycleTime" SG_ 691 HU_iDCSLevel 100;
BA_ "GenSigInvalidValue" SG_ 691 HU_iDCSLevel "NA";
BA_ "GenSigCycleTime" SG_ 691 HU_iDCS_Switch_Status 100;
BA_ "GenSigInvalidValue" SG_ 691 HU_iDCS_Switch_Status "NA";

BA_ "GenSigCycleTime" SG_ 773 BMS_PackSwitchSts 500;

VAL_ 80 SRS_PassengerBuckleSwitchStatus 0 "Buckled" 1 "Unbuckle " 2 "Not Used" 3 "Not Used
Default value= 0x0";
VAL_ 80 SRS_FrontPsgOccupancy 0 "not occupied" 1 "occupied
Default value= 0x1";
VAL_ 80 SRS_DriverBuckleSwitchStatus 0 "Buckled" 1 "Unbuckle " 2 "Not Used" 3 "Not Used
Default value= 0x0";

VAL_ 384 SAS_SASFailure 0 "No Failure" 1 "Failure";
VAL_ 384 SAS_Calibrated 0 "Calibrated" 1 " Not Calibrated";
VAL_ 384 SAS_SteeringAngleValid 0 "Valid " 1 "Invalid";

VAL_ 342 PCU_TankTurn_Available 0 "Not available" 1 "available";
VAL_ 342 PCU_CoastRgnTarWhlRearQlfr 0 "NotIntialized" 1 "Normal" 2 "Faulty";
VAL_ 342 PCU_CoastRgnTarWhlFrntQlfr 0 "NotIntialized" 1 "Normal" 2 "Faulty";

VAL_ 580 ACC_AEBSpeedDropLevel 0 "65kph£¨³¬¹ý-8m/ss£©" 1 "125kph£¨-8m/ssÒÔÄÚ£©" 2 " Reserved" 3 " Reserved";
VAL_ 580 ACC_AEBCtrlType 0 "no request" 1 "AEB C&U£¨AEB³µÁ¾£©" 2 "AEB VRU£¨AEBÐÐÈË£©" 3 "AEB Cyclist£¨AEBÆïÐÐÕß£©" 4 "EBA£¨ÖÆ¶¯¸¨Öú£©" 5 "FCTB£¨Ç°ÏòºáÏòAEB£©" 6 "RCTB(ºóÏòºáÏòAEB)" 7 "Reserved";
VAL_ 580 ACC_AEBVehilceHoldReq 0 " No hold" 1 " hold";
VAL_ 580 ACC_FCWActive 0 " not Active" 1 " Active";
VAL_ 580 ACC_PrefillActive 0 " not Active" 1 " Active";
VAL_ 580 ACC_AWBActive 0 " not Active" 1 " Active";
VAL_ 580 ACC_AWBlevel 0 "  no level" 1 "  level 1" 2 "  level 2" 3 "  level 3" 4 "  level 4" 5 " reserved";
VAL_ 580 ACC_ABAActive 0 " not Active" 1 " Active";
VAL_ 580 ACC_ABAlevel 0 " level 0" 1 "level 1" 2 " level 2" 3 " level 3";
VAL_ 580 ACC_AEBActive 0 " not Active" 1 " Active.";
VAL_ 580 ACC_Driveoff_Request 0 " No request" 1 " request";
VAL_ 580 ACC_ACCMode 0 "OFF mode" 1 "Passive mode" 2 "StandBy mode" 3 " Active Control mode" 4 " Brake Only mode" 5 " Override" 6 " Stand Wait mode" 7 " Failure mode";
VAL_ 580 ACC_CDDActive 0 " not active" 1 " Active";
VAL_ 580 ACC_EngineStartStopRequest 0 "No request" 1 "EngineAutoStopRequest" 2 "EngineAutoStartRequest" 3 "reserved";
VAL_ 580 ACC_DecToStop 0 "no demand" 1 " demand";

VAL_ 583 APA_PrecheckValid 0 "Valid" 1 "Invalid";
VAL_ 583 APA_Precheck 0 "Nocheck" 1 "Check";
VAL_ 583 APA_ESP_BrakeFunctionMode 0 "None" 1 "ReducedFunction" 2 "FullFunction" 3 "Invalid";
VAL_ 583 APA_IncreasePressureReq 0 "Not request" 1 "Request";
VAL_ 583 APA_EmergenceBrake 0 "Not request" 1 "Request";
VAL_ 583 APA_HSAHDforbidden 0 "Not request" 1 "Request";
VAL_ 583 APA_ESPDecompressionModel 0 "Slow decompression" 1 "fast decompression";
VAL_ 583 APA_PrefillReq 0 "Not request" 1 "Request";
VAL_ 583 APA_LSCAction 0 "OFF" 1 "ON";
VAL_ 583 APA_TargetAccelerationValid 0 " not enable" 1 " enable";
VAL_ 583 APA_EPBrequestValid 0 "Invalid" 1 "Valid";
VAL_ 583 APA_EPBrequest 0 "No Request" 1 "RequestBrake" 2 "RequestRelase";

VAL_ 632 ESP_YawRateValid 0 "Valid" 1 "Invalid";

VAL_ 349 SRS_CrashOutputStatusforMCB 0 "No Crash" 1 "Front Crash" 2 "Other Directions Crash" 3 "Reserved";
VAL_ 349 ESP_IMUCalibrated 0 "Calibrated" 1 "Not Calibrated";
VAL_ 349 ESP_YawRateValid 0 "Initializing" 1 "Valid" 2 "Invalid" 3 "Reserved";
VAL_ 349 ESP_LatAccelValid 0 "Initializing" 1 "Valid" 2 "Invalid" 3 "Reserved";
VAL_ 349 ESP_LongAccelValid 0 "Initializing" 1 "Valid" 2 "Invalid" 3 "Reserved";

VAL_ 862 ACC_ACCEPBrequest 0 " no request" 1 "  request";

VAL_ 823 ESP_EpbReqAvl 0 "Not available
0x1=available";
VAL_ 823 IBCU_BrkSysFltLamp 0 "OFF" 1 "ON";
VAL_ 823 ESC_ATSReqEnable 0 "disable" 1 "enable ";
VAL_ 823 ESC_ATSDrivingModeStatus 0 " normal" 1 " snow" 2 " mud" 3 " sand" 4 " rock" 5 " wade" 6 " ready";
VAL_ 823 ESP_RollerbenchEnable 0 "display" 1 "nodisplay";
VAL_ 823 ESP_WheelSpdSensorError 0 "No error" 1 "error";
VAL_ 823 ESP_WheelSpdSensorEcuError 0 "No error" 1 "error";
VAL_ 823 ESP_VGH_Status 0 "Standby" 1 "Inactive" 2 "Failure" 3 "Close";
VAL_ 823 ESP_VGH_Available 0 "Available" 1 "Not Available";
VAL_ 823 ESP_TPMSresetstatus 0 "Default value(ÎÞÖØÖÃÇëÇó)" 1 " Reset Request Received(ÏµÍ³ÖØÖÃÒÑ´¥·¢)" 2 "Reset On-going(ÏµÍ³ÖØÖÃ½øÐÐÖÐ)" 3 "Reset Failed(ÏµÍ³ÖØÖÃÊ§°Ü)" 4 "Reset Finished(ÏµÍ³ÖØÖÃÍê³É)" 5 "Reserved(Ô¤Áô)";
VAL_ 823 ESP_TPMS_WarningStatus 0 "No Tire Pressure Warning" 1 "Tire Pressure Warning";
VAL_ 823 ESP_TPMS_MalfunctionStatus 0 " TPMS Work OK" 1 "TPMS MalFunction";
VAL_ 823 ESP_RRWheelSpdSensorSigFailure 0 "No error" 1 "error";
VAL_ 823 ESP_RRWheelSpdSensorFailure 0 "No error" 1 "error";
VAL_ 823 ESP_RRWheelSpdSensor_ShtBAT 0 "No error" 1 "error";
VAL_ 823 ESP_RRWheelSpdSensor_Open 0 "No error" 1 "error";
VAL_ 823 ESP_RRWheelSpdSensor_GND 0 "No error" 1 "error";
VAL_ 823 ESP_RLWheelSpdSensorSigFailure 0 "No error" 1 "error";
VAL_ 823 ESP_RLWheelSpdSensorFailure 0 "No error" 1 "error";
VAL_ 823 ESP_RLWheelSpdSensor_ShtBAT 0 "No error" 1 "error";
VAL_ 823 ESP_RLWheelSpdSensor_Open 0 "No error" 1 "error";
VAL_ 823 ESP_RLWheelSpdSensor_GND 0 "No error" 1 "error";
VAL_ 823 ESP_RearRghtWheelStatus 0 "Normal" 1 "Single Wheel Warning" 2 "General Warning" 3 "invalid";
VAL_ 823 ESP_RearLeftWheelStatus 0 "Normal" 1 "Single Wheel Warning" 2 "General Warning" 3 "invalid";
VAL_ 823 EPBi_ResetSts 0 "Valid" 1 "GWÇëÇó¸´Î»" 2 "×ÔÉíÅÐ¶Ï¸´Î»" 3 "²»Âú×ã¸´Î»Ìõ¼þ" 4 "Reserve" 7 "Invalid";
VAL_ 823 ESP_FRWheelSpdSensorSigFailure 0 "No error" 1 "error";
VAL_ 823 ESP_FRWheelSpdSensorFailure 0 "No error" 1 "error";
VAL_ 823 ESP_FRWheelSpdSensor_ShtBAT 0 "No error" 1 "error";
VAL_ 823 ESP_FRWheelSpdSensor_Open 0 "No error" 1 "error";
VAL_ 823 ESP_FRWheelSpdSensor_GND 0 "No error" 1 "error";
VAL_ 823 ESP_FrontRightWheelStatus 0 "Normal" 1 "Single Wheel Warning" 2 "General Warning" 3 "invalid";
VAL_ 823 ESP_FrontLeftWheelStatus 0 "Normal" 1 "Single Wheel Warning" 2 "General Warning" 3 "invalid";
VAL_ 823 ESP_FLWheelSpdSensorSigFailure 0 "No error" 1 "error";
VAL_ 823 ESP_FLWheelSpdSensorFailure 0 "No error" 1 "error";
VAL_ 823 ESP_FLWheelSpdSensor_ShtBAT 0 "No error" 1 "error";
VAL_ 823 ESP_FLWheelSpdSensor_Open 0 "No error" 1 "error";
VAL_ 823 ESP_FLWheelSpdSensor_GND 0 "No error" 1 "error";
VAL_ 823 IBCU_CST_FunctionSwitch 0 "Reserved" 1 "CST On" 2 "CST Off" 3 "Error";
VAL_ 823 ESP_AWD_ModeRequest 0 "no press" 1 "SWITCH1" 2 "SWITCH2" 3 "reserved";
VAL_ 823 ESP_ATS_PtrotectMode 0 "false" 1 "True";
VAL_ 823 ESP_ATS_ATB_Failure 0 "false" 1 "True";
VAL_ 823 ESP_ATS_EPBi_Failure 0 "false" 1 "True";
VAL_ 823 ESP_ATS_AWD_Failure 0 "false" 1 "True";
VAL_ 823 ESP_ATS_TCU_Failure 0 "false" 1 "True";
VAL_ 823 ESP_ATS_EMS_Failure 0 "false" 1 "True";
VAL_ 823 ESC_ATSReqEnable 0 "disable" 1 "enable";
VAL_ 823 ESP_ATS_DriveModeRequest 0 "Normal" 1 "Eco" 2 "Sport" 3 "Snow" 4 "Sport+(Reserved)
0x5=Auto_Normal" 6 "Auto_Eco" 7 "Auto_Sport" 8 "MUD" 9 "SAND" 10 "Reserved" 15 "Invalid";
VAL_ 823 ESC_ATSDrivingModeStatus 0 "Normal" 1 " snow" 2 " mud" 3 " sand" 4 " rock" 5 " wade" 6 " ready" 7 "Reserved";

VAL_ 870 AC_EnvironmentalTemp 0 "-40~87¡æ" 255 "Invalid";
VAL_ 870 AC_EnvironmentalTempVD 0 "Valid" 1 "Invalid";

VAL_ 1302 HU_RollerbenchSetStaus 0 " inactive" 1 " close" 2 " open" 3 "Reserved";
VAL_ 1302 HU_LocalTimeSystem 0 "24h" 1 "12h" 2 "Reserved" 3 "Invalid";
VAL_ 1302 HU_LocalTimeValid 0 "Valid" 1 "Not Valid";

VAL_ 1328 IP_EngineOffTime 0 "0-65533s" 65534 "65534 or >65534" 65535 "invalid";

VAL_ 378 IBCU_MCB_availalbe 0 "not available" 1 "available";
VAL_ 378 IBCU_MCB_Active 0 "not active" 1 "active";
VAL_ 378 ESP_TankTurn_EngTorqIncRearActive 0 "NotActive" 1 "Active";
VAL_ 378 ESP_TankTurn_EngTorqIncFrontActive 0 "NotActive" 1 "Active";
VAL_ 378 IBCU_TankTurn_Status 0 " Disabled" 1 " Standby" 2 " Active" 3 " Failure";
VAL_ 378 IBCU_BrkPedlTrvlDrvrVld 0 "NotInitialized" 1 "Normal" 2 "Invalid";
VAL_ 378 Wheel_Speed_RL_Valid_Data 0 "Valid" 1 "NotValid";
VAL_ 378 Wheel_Speed_RR_Valid_Data 0 "Valid" 1 "NotValid";
VAL_ 378 ESP_VDCActive 0 "NotActive" 1 "Active";
VAL_ 378 ESP_TCSActive 0 "NotActive" 1 "Active";
VAL_ 378 ESP_ElectricBoostFailStatus 0 "No request to the warning lamp" 1 "Yellow requested" 2 "Red requested" 3 "Reserved";
VAL_ 378 ESP_MbRegenTarWhlTotalQlfr 0 "NotIntialized" 1 "Normal" 2 "Faulty";
VAL_ 378 ESP_RollerbenchType 0 "Passive" 1 "Unknown" 2 "FrontAxle" 3 "RearAxle" 4 "TwoAxle" 5 "Road" 6 "Reserve" 7 "Reserve";
VAL_ 378 IBCU_BrakeFluid_Warning 0 "No request to the warning lamp" 1 "Yellow requested" 2 "Red requested" 3 "Reserved";
VAL_ 378 ESP_VehicleSpeedValid2 0 "VehicleSpeedQualifier_NotInit" 1 "VehicleSpeedQualifier_Normal" 2 "VehicleSpeedQualifier_Faulty";
VAL_ 378 ESP_VehicleSpeedValid 0 "Valid" 1 "NotValid";
VAL_ 378 ESP_VehicleSpeed 0 "0~360km/h" 6401 "Reserved" 8191 "Invalid
APA2.0½ÓÊÕ";
VAL_ 378 ESP_TCSFailStatus 0 "Noerror" 1 "Error";
VAL_ 378 ESP_pMcVirtual_Q 0 " pMcVirtual_NotInitializedÎ´³õÊ¼»¯" 1 " pMcVirtual_NormalÕý³£" 2 " pMcVirtual_Faulty´íÎó";
VAL_ 378 ESP_MbRegenTarWhlRearQlfr 2 "Faulty" 1 "Normal" 0 "NotIntialized";
VAL_ 378 ESP_MbRegenTarWhlFrontQlfr 2 "Faulty" 1 "Normal" 0 "NotIntialized";
VAL_ 378 ESP_GearHoldRequestValid 0 "Valid" 1 "NotValid";
VAL_ 378 ESP_GearHoldRequest 0 "NotRequest" 1 "Request";
VAL_ 378 ESP_ESPFunctionStatus 0 "OFF" 1 "ON";
VAL_ 378 ESP_ESPActiveStatus 0 "NotActive" 1 "Active";
VAL_ 378 ESP_EngTorqIncRearActive 1 "Active," 0 "NotActive,";
VAL_ 378 ESP_EngTorqIncFrontActive 0 "NotActive" 1 "Active";
VAL_ 378 ESP_EngTorqDecRearActive 0 "NotActive" 1 "Active";
VAL_ 378 ESP_EngTorqDecFrontActive 0 "NotActive" 1 "Active";
VAL_ 378 ESP_EngTorqDecActive 0 "NotActive" 1 "Active";
VAL_ 378 ESP_EBDFailStatus 0 "Noerror" 1 "Error";
VAL_ 378 ESP_ABSFailStatus 0 "Noerror" 1 "Error";
VAL_ 378 ESP_ABSActiveStatus 0 "NotActive" 1 "Active";
VAL_ 378 EPBi_MILReq 0 "Not Request" 1 "Request";
VAL_ 378 EPBi_ClearDiagnosticInfo 0 "Normal" 1 "Not used" 2 "EPBi request EMS to clear DiagnosticInfo" 3 "EPBi has cleared Diag info per EMS request";

VAL_ 381 PCU_MbRegenWhlTotalVld 0 "invalid" 1 "valid";
VAL_ 381 PCU_ReWhlReqTqVld 0 "valid" 1 "invalid";
VAL_ 381 PCU_FrntWhlReqTqVld 0 "valid" 1 "invalid";
VAL_ 381 PCU_ReWhlActTqVld 0 "valid" 1 "invalid";
VAL_ 381 PCU_FrntWhlActTqVld 0 "valid" 1 "invalid";
VAL_ 381 PCU_MbRegenMaxRearWhlVld 0 "Invalid" 1 "Valid";
VAL_ 381 PCU_RearMotSts 0 "Not Ready" 1 "Ready";
VAL_ 381 PCU_ESPTqReqAvlRear 1 "NotAvailable" 0 "Available";
VAL_ 381 PCU_PwrTrainSts 3 "Ô¤Áô" 2 "Running" 1 "Crank" 0 "Stop";
VAL_ 381 PCU_BrkPedlSts 0 "Not Pressed" 1 "Pressed" 2 "Reserved" 3 "Error";
VAL_ 381 PCU_MbRegenMaxWhlQlfr 2 "Faulty" 1 "Normal" 0 "NotIntialized";
VAL_ 381 PCU_MbRegenMaxFrontWhlVld 0 "Invalid" 1 "Valid";
VAL_ 381 PCU_AccPedlVld 1 "invalid" 0 "valid";
VAL_ 381 PCU_RearMotStsVld 0 "Invalid" 1 "Valid";
VAL_ 381 PCU_FrontMotStsVld 0 "Invalid" 1 "Valid";
VAL_ 381 PCU_FrontMotSts 0 "Not Ready" 1 "Ready£¨µç»úÎÞ¹ÊÕÏ£¬¿ÉÒÔÕý³£Êä³ö¶¯Á¦£©";
VAL_ 381 PCU_ESPTqReqAvlFront 1 "NotAvailable" 0 "Available";
VAL_ 381 PCU_TarGearReqValid 0 "Valid" 1 "Invalid";
VAL_ 381 PCU_TarGearReq 0 "Initial value" 1 "1st gear" 2 "2nd gear" 3 "3rd gear" 4 "4th gear" 5 "5th gear" 6 "6th gear" 7 "7th gear" 8 "8th gear" 9 "Reverse" 10 "Neutral" 11 "Reserved" 12 "Reserved" 14 "Reserved" 15 "Invalid";
VAL_ 381 PCU_RealAccPedlVld 1 "invalid" 0 "valid";

VAL_ 459 IBCU_ElectrodelessBrakeModeFeedBack 0 "inactive" 1 "1%-100%" 101 "Reserved" 255 "Invalid";
VAL_ 459 IBCU_ESPTSMAvlSts 0 "Not available" 1 "available";
VAL_ 459 IBCU_ESPTSMAct 0 "Not active" 1 "active";
VAL_ 459 IBCU_EPBrequest 0 "Not Initialized" 1 "No Request" 2 "Release brake request" 3 "Lock brake request";
VAL_ 459 IBCU_EPBrequestValid 0 "Valid" 1 "Invalid";
VAL_ 459 WhlPreLeReVld 0 "Invalid" 1 "Valid";
VAL_ 459 WhlPreRiReVld 0 "Invalid" 1 "Valid";
VAL_ 459 WhlPreLeFrntVld 0 "Invalid" 1 "Valid";
VAL_ 459 WhlPreRiFrntVld 0 "Invalid" 1 "Valid";
VAL_ 459 IBCU_BrkTqReqAvail 0 "Not available" 1 "available";
VAL_ 459 IBCU_DrvrBrkReqTqVID 0 " Valid" 1 " Invalid";
VAL_ 459 IBCU_NBrkMode 0 " Disabled, [PSO_DISABLE (TMC)] 
0x1= Normal, [PSO_NORMAL(overlay) ] " 2 " Primary_Only,  [PSO_PRIMARY ONLY (LAC)]
0x3= Cooperative, [PSO_SECONDARY COOPERATIVE(APC cooperativ)]" 4 " Secondary_Only [PSO_SECONDARY ONLY (APC)] ";
VAL_ 459 IBCU_System_Status 0 " BBF_FullSys/Init/Default" 1 " BBF_DegradedPedalFeel" 2 " BBF_CircuitSperation" 3 " BBF_C1/2BoostOnly" 4 " HydBack w/ act / HydBack w/o act" 5 " reserved";
VAL_ 459 IBCU_CST_Status 0 "CST is Disabled" 1 "CST is Standby" 2 "CST is Active" 3 "CST is Failure";
VAL_ 459 IBCU_sOutputRodDriver_Q 0 "soutputRodDriver_NotInitializedÎ´³õÊ¼»¯" 1 "soutputRodDriver_NormalÕý³£" 2 "soutputRodDriver_Faulty´íÎó";
VAL_ 459 IBCU_sOutputRodAct_Q 0 "SoutputRodAct_NotInitialized" 1 "SoutputRodAct_Normal" 2 "SoutputRodAct_Faulty";
VAL_ 459 IBCU_MILReq 0 "Not request" 1 "Request";
VAL_ 459 IBCU_ExtReqStatus 0 "EBR_NotInitializedÎ´³õÊ¼»¯" 1 "EBR_NotAvailable ²»¿ÉÓÃ" 2 "EBR_Available¿ÉÓÃ";
VAL_ 459 IBCU_ExtReqPrio 0 "EBR is Not active or the driver dominates the brake torqueÍâ²¿ÖÆ¶¯ÇëÇóÃ»ÓÐ¼¤»î»ò¼ÝÊ»Ô±ÕýÔÚÖÆ¶¯" 1 "EBR is active and dominates the brake torqueÍâ²¿ÖÆ¶¯ÇëÇó¼¤»îÇÒÖ§ÅäÖÆ¶¯Á¦¾ØÐèÇó";
VAL_ 459 IBCU_ClearDiagnosticInfo 0 "Normal" 1 "Not used" 2 "IBCU request EMS to clear DiagNosticInfo" 3 "IBCU has cleared Diag info per EMS request";
VAL_ 459 IBCU_BrakePedalApplied_Q 0 "BrakePedalApplied_NotInitÎ´³õÊ¼»¯" 1 "BrakePedalApplied_NormalÕý³£" 2 "BrakePedalApplied_Faulty´íÎó";
VAL_ 459 IBCU_BrakePedalApplied 0 "BrakePedal_NotAppliedÌ¤°åÎ´²ÈÏÂ" 1 "BrakePedal_AppliedÌ¤°å²ÈÏÂ";
VAL_ 459 IBCU_BrakeModeFeedBack 0 " inactive" 1 " normal" 2 " Sport" 3 "custom";
VAL_ 459 IBCU_BrakeModeEnable 0 "display" 1 "No display";

VAL_ 523 IBCU_DMCIncCtrlMod 0 "OFF" 1 "On" 2 "SplitMode" 3 "reserve";
VAL_ 523 IBCU_DMCDecCtrlMod 0 "OFF" 1 "On" 2 "SplitMode" 3 "reserve";
VAL_ 523 IBCU_BDC_Status 0 "OFF" 1 "AutoStandby" 2 "ManualStandby" 3 "AutoActive" 4 "ManualActive" 5 " Failure" 6 "Reserved";
VAL_ 523 IBCU_BDCAvlblSts 0 "Not available" 1 "available";
VAL_ 523 IBCU_iDCS_State 0 "OFF" 1 "Standby" 2 "PreActive" 3 "acitve" 4 "Reserved";
VAL_ 523 IBCU_iDCSLevFd 0 "Init" 1 "M-Mode_level 1" 2 "M-Mode_level 2" 3 "M-Mode_level 3" 4 "Reserved";
VAL_ 523 IBCU_iDCSAvlblSts 0 "Not available" 1 "available";
VAL_ 523 ESP_CDD_Availablebysituaion 0 "Invalid" 1 "not available by situation";
VAL_ 523 ESP_AEBSpeedDropActive 0 "65kph£¨³¬¹ý-8m/ss£©" 1 "125kph£¨-8m/ssÒÔÄÚ£©" 2 " Reserved" 3 " Reserved";
VAL_ 523 IBCU_TankTurn_EDLOpenSet 0 "Inactive" 1 "Active";
VAL_ 523 IBCU_EBS_Status 0 "None" 1 "BS" 2 "DL" 3 "NS" 4 "BTL" 5 "JX" 6 "ZF" 7 " Reverse" 15 "Invalid";
VAL_ 523 IBCU_TankTurn_Enable 0 "Not Enable" 1 "Enable";
VAL_ 523 IBCU_TankTurn_Available 0 "Not available" 1 "available";
VAL_ 523 ESP_VehicleStandstillVld 0 "valid" 1 "Invalid";
VAL_ 523 IBCU_BrkPedlStsGbVld 0 "NotInitialized" 1 "Normal" 2 "Invalid";
VAL_ 523 IBCU_BrkPedoplStsGb 0 " ÖÆ¶¯Î´²ÈÏÂ" 101 " ÖÆ¶¯²ÈÏÂ" 254 "Òì³£";
VAL_ 523 ESP_EBDActive 0 "Not active" 1 "active";
VAL_ 523 IBCU_DTCAvailable 0 "not available" 1 "available" 2 "available without stable control";
VAL_ 523 ESP_MasCylBraPreByDriverValid 0 "Valid" 1 "Invalid";
VAL_ 523 ESP_Vehicle_Speed_Reference 0 "0~360km/h" 6401 "Reserved" 8191 "Invalid";
VAL_ 523 IBCU_precheckStatus 0 "not checked" 1 "in checking" 2 "checked" 3 "failed";
VAL_ 523 ESP_PrefillforAPA_Available 0 "notavailable" 1 "available";
VAL_ 523 ESP_PrefillforAPA_active 0 "notactive" 1 "active";
VAL_ 523 IBCU_BrakeDiscHighTempWarning 0 "no failure" 1 "OverheatLevel1" 2 "OverheatLevel2" 3 "failure";
VAL_ 523 ESP_DTV_Available 0 "Available" 1 "Not Available";
VAL_ 523 ESP_DTV_Active 0 "Not Active" 1 "Active";
VAL_ 523 Wheel_Speed_RR_Valid_Data 0 "Valid" 1 "NotValid";
VAL_ 523 Wheel_Speed_RR_Direction 0 "Forward" 1 "backward" 2 "Standstill" 3 "Invalid";
VAL_ 523 Wheel_Speed_RL_Valid_Data 0 "Valid" 1 "NotValid";
VAL_ 523 Wheel_Speed_RL_Direction 0 "Forward" 1 "backward" 2 "Standstill" 3 "Invalid";
VAL_ 523 Wheel_Speed_FR_Valid_Data 0 "Valid" 1 "NotValid";
VAL_ 523 Wheel_Speed_FR_Direction 0 "Forward" 1 "backward" 2 "Standstill" 3 "Invalid";
VAL_ 523 Wheel_Speed_FL_Valid_Data 0 "Valid" 1 "NotValid";
VAL_ 523 Wheel_Speed_FL_Direction 0 "Forward" 1 "backward" 2 "Standstill" 3 "Invalid";
VAL_ 523 ESP_VehicleStandstill 0 "notstandstill" 1 "standstill";
VAL_ 523 ESP_VDCActive 0 "NotActive" 1 "Active";
VAL_ 523 ESP_UrgencyBrakeAlarm 0 "NotActive" 1 "Active";
VAL_ 523 ESP_TCSActive 0 "NotActive" 1 "Active";
VAL_ 523 ESP_QDCACC 0 "noerror" 1 "error" 2 "reserved" 3 "reserved";
VAL_ 523 ESP_PrefillAvailable 0 "notavailable" 1 "available";
VAL_ 523 ESP_PrefillActive 0 "notactive" 1 "active";
VAL_ 523 ESP_OnlyABSActive 0 "NotActive" 1 "Active";
VAL_ 523 ESP_MasCylBrakePressureValid 0 "Valid" 1 "Invalid";
VAL_ 523 ESP_IncreasePressureReqOK 0 "Not_OK" 1 "OK";
VAL_ 523 ESP_HHC_Available 0 "Available" 1 "NotAvailable";
VAL_ 523 ESP_HHC_Active 0 "functionisnotinactive" 1 "functionisinactive";
VAL_ 523 ESP_HDC_STATUS 0 "OFF" 1 "ON" 2 "Standby" 3 "Error";
VAL_ 523 ESP_ECDAvailable 0 "Valid" 1 "Invalid";
VAL_ 523 ESP_ECDActive 0 "NotActive" 1 "Active";
VAL_ 523 ESP_CDD_Available_APA 1 "available" 0 "notavailable";
VAL_ 523 ESP_CDD_Available 0 "notavailable" 1 "available";
VAL_ 523 ESP_CDD_Active_APA 1 "active" 0 "notactive";
VAL_ 523 ESP_CDD_Active 0 "notactive" 1 "active";
VAL_ 523 ESP_BrakeOverHeatBrakeDiscTemp 0 "nothigh" 1 "temptoohigh";
VAL_ 523 ESP_BrakeLightOnRequest 0 "brakelightOFF" 1 "brakelightON" 2 "notused" 3 "signalnotavailable";
VAL_ 523 ESP_BrakeForce 0 "nobrakeforce" 1 "havebrakeforce";
VAL_ 523 ESP_AWBavailable 0 "notavailable" 1 "available";
VAL_ 523 ESP_AWBactive 0 "notactive" 1 "active";
VAL_ 523 ESP_AutoHoldStandby 0 "NotActive" 1 "Active";
VAL_ 523 ESP_AutoHoldAvailable 0 "Valid" 1 "Invalid";
VAL_ 523 ESP_AutoHoldActive 0 "NotActive" 1 "Active";
VAL_ 523 ESP_AEBdecActive 0 "notactive" 1 "active";
VAL_ 523 ESP_AEBAvailable 0 "notavailable" 1 "available";
VAL_ 523 ESP_ABAavailable 0 "notavailable" 1 "available";
VAL_ 523 ESP_ABAactive 0 "notactive" 1 "active";
VAL_ 523 ABS_TODFastOpenRequest 0 "Passive" 1 "OpenClutch" 2 "Torquemaxlimit" 3 "Error";

VAL_ 650 IP_HandBrakeSwitch 0 "no use" 0 "in use";

VAL_ 651 BCM_DrvrSts 0 "ÎÞÈË" 1 "ÓÐÈË";
VAL_ 651 BCM_PowerStatusFeedback 0 "OFF" 1 "ACC" 2 "ON" 3 "Start";
VAL_ 651 BCM_DriverDoorStatus 0 "Close" 1 "Open";

VAL_ 724 APA_ReleasePressureReq 0 " No Request" 1 "Request";

VAL_ 721 BCM_ReversePosition 0 " NOT IN Reverse" 1 " IN Reverse";

VAL_ 758 HU_IndirectTPMSReset 0 "No request" 1 "Request";

VAL_ 827 PCU_SnowModelStatus 0 "Inactive " 1 "Open" 2 "Close" 3 "Reserved";
VAL_ 827 PCU_OffRoadCrpSts 0 "Off" 1 "Standby" 2 "Active" 3 "Fault";
VAL_ 827 PCU_TowingMode 0 "not Active" 1 "Active";
VAL_ 827 PCU_DrvModVld 0 "Invalid" 1 "Valid";
VAL_ 827 PCU_DrvMod 0 "reserved" 1 "´¿µçÇý¶¯" 2 "»ìºÏÇý¶¯" 3 "Super Race" 4 "i-X" 5 "ÖÇÄÜÇý¶¯" 6 "ÌØÊâ³¡¾°" 7 "Ôö³ÌÄ£Ê½";

VAL_ 916 HU_CdcEpbSwtSet 0 "no request" 1 "apply" 2 "Reserved" 3 "Reserved";
VAL_ 916 HU_CST_FunctionSwitch 0 "Inactive" 1 "CST On" 2 "CST Off" 3 "Reserved";
VAL_ 916 HU_BrakeModeSetStaus 0 " inactive" 1 " normal" 2 " Sport" 3 "custom";

VAL_ 1021 BCM_PowerManageLevel 0 "Valid" 1 "Level1" 2 " Level2" 3 " Level3" 4 " Level4" 5 "Reserve" 7 "Invalid";

VAL_ 1326 IP_IndirectTPMSReset 0 "No request" 1 "Request";

VAL_ 1410 EPBI_NotSleep_BYTE7BIT6 0 "Inactive" 1 "ÓÐÖÆ¶¯ÇëÇó";
VAL_ 1410 EPBI_NotSleep_BYTE7BIT5 0 "Inactive" 1 "¼ì²âµ½³µÁ¾·Ç¾²Ö¹";
VAL_ 1410 EPBI_NotSleep_BYTE7BIT4 0 "Inactive" 1 "ÓÐ³µËÙ¼ÆÊ±Î´µ½30·ÖÖÓ";
VAL_ 1410 EPBI_NotSleep_BYTE7BIT3 0 "Inactive" 1 "ÎÞ³µËÙ¼ÆÊ±Î´µ½30S";
VAL_ 1410 EPBi_NotSleep_BYTE7BIT2 0 "Inactive" 1 "µç×ÓÊÖÉ²¿ª¹Ø¿¨ÖÍ";
VAL_ 1410 EPBi_NotSleep_BYTE7BIT1 0 "Inactive" 1 "IGON²»ÔÊÐíÐÝÃß";
VAL_ 1410 EPBi_NotSleep_BYTE7BIT0 0 "Inactive" 1 "CANÍøÂçÉÏÆäËû½Úµã²»ÔÊÐíÐÝÃß";
VAL_ 1410 EPBi_WakeUp_BYTE4BIT2 0 "Inactive" 1 "µç×ÓÊÖÉ²¿ª¹Ø»½ÐÑ";
VAL_ 1410 EPBi_WakeUp_BYTE4BIT1 0 "Inactive" 1 "µçÔ´ON_WAKEUP";
VAL_ 1410 EPBi_WakeUp_BYTE4BIT0 0 "Inactive" 1 "CAN_WAKEUP";

VAL_ 431 TCU_ShiftPostionValid 0 "valid" 1 "invalid";
VAL_ 431 TCU_ShiftInProgressVld 0 "Invalid" 1 "Valid";
VAL_ 431 TCU_ShiftInProgress 0 "Not shifting" 1 "Shifting";
VAL_ 431 TCU_GearShiftPosition 0 "Parking" 1 "Reverse" 2 "Neutral" 3 "D" 4 "D3" 5 "D2" 6 "L" 7 "M/S" 8 "Reserved" 13 " Initial value" 14 " Unreliable" 15 " Invalid";
VAL_ 431 TCU_ActualDrivingGearValid 0 "valid" 1 "invalid";
VAL_ 431 TCU_ActualDrivingGear 0 "Neutral" 1 "1st gear" 2 "2nd gear" 3 "3rd gear" 4 "4th gear" 5 "5th gear" 6 "6th gear" 7 "7th gear" 8 "8th gear" 9 "Reverse" 10 "Parking" 11 "Reserved" 13 "Reserved" 14 "Reserved" 15 "Invalid";

VAL_ 800 GW_OTAmode 0 "OTAinactive" 1 "OTAmode1-³µÄÚÉý¼¶°²È«Ö´ÐÐÖÐ" 2 " OTAmode2-³µÍâÉý¼¶°²È«Ö´ÐÐÖÐ" 3 "OTAmode3-Reserved" 4 "OTAmode4-³µÄÚÉý¼¶·Ç°²È«Ö´ÐÐÖÐ" 5 "OTAmode5-³µÍâÉý¼¶·Ç°²È«Ö´ÐÐÖÐ" 6 "OTAmode6-³µÄÚÉý¼¶Ìõ¼þ¼ì²âÖÐ" 7 "OTAmode7-³µÍâÉý¼¶Ìõ¼þ¼ì²âÖÐ" 8 "Reserved";
VAL_ 800 GW_ResetReq 0 "Valid" 1 "THU" 2 " AMP" 3 "ADS/ADC" 4 " FC/LAS" 5 "FR/ACC" 6 "FLR" 7 "FRR" 8 "RLR/LCDAL" 9 "RRR/LCDAR" 10 "LVSM" 11 "INS" 12 "APA" 13 "BCML/BCM" 14 "GW/BCMR" 15 "EMS" 16 "PCU" 17 "BMS" 18 "PEU" 19 "OBC" 20 "TCU" 21 "IPUMP" 22 "ACM" 23 "ESL" 24 "PTS" 25 "ESCL" 26 "TMS/AC" 27 "DKC/RFBT/BLEM" 28 "WLCM" 29 "EPBI" 30 "IBCU" 31 "RBM" 32 "EPS" 33 "EPS2" 34 "DSM" 35 "IP" 36 "SLCM" 37 "HUD" 38 "GPEU" 39 "PDU" 40 "RPEU" 41 "VMC" 43 "DPEU" 44 "NFC-Enter" 45 "PATC" 46 "VMC2" 47 "RCCS" 48 "TRM" 49 "PDCU" 50 "BDCR" 51 "mADC" 52 "EPB" 53 "EVCC" 54 "HLM" 55 "CTMU" 56 "HRM" 57 "RLM" 64 "PSM" 65 "TBOX" 66 "DCDC" 67 "CMS" 68 "ICRF" 69 "ICRR" 70 "EPBi2" 71 "Reserve" 127 "Invalid";

VAL_ 939 HU_AutoHoldStatusSetReq 0 "Inactive" 1 "AutoHold Off" 2 "AutoHold On" 3 "Reserved";
VAL_ 939 HU_HDCStatusSetReq 0 "Inactive" 1 "HDC Off" 2 "HDC On" 3 "Reserved";
VAL_ 939 HU_ESPStatusSetReq 0 "Inactive" 1 "ESP On" 2 "ESP Off" 3 "Reserved";

VAL_ 393 IBCU_ReqSecOCSYNMSG 0 "NoRequest" 1 "ÇëÇóÍ¬²½±¨ÎÄ£¨0x1AD£©¼Ó1·¢ËÍ" 2 "Reserved";

VAL_ 881 PCU_DrvMod2 0 "Inactive" 1 "ECO" 2 "normal" 3 "sport" 4 "×Ô¶¨Òå1" 5 "×¨ÊôÄ£Ê½" 6 "Reserved";
VAL_ 881 PCU_SpecialModeSetFB 0 "reserved" 1 "reserved" 2 "³¤Í¾Ä£Ê½" 3 "É½µØÄ£Ê½" 4 "Ó¦¼±Ä£Ê½" 5 "×¤³µÄ£Ê½" 6 "Super Race";

VAL_ 394 TCU_ParkingRequest 0 "Wait commond" 1 "Park commond" 2 "NotPark commond" 3 " Invalid";

VAL_ 266 EPB_BackupCapability 0 " Primary-MCU & Secondary-MCU Both Have Controllability (EPB controled in Primary-MCU ) " 1 " Only Primary-MCU  Have Controllability (EPB controled in Primary-MCU ) " 2 " Only Secondary-MCU Both Have Controllability (EPB controled in Secondary-MCU ) " 3 " Primary-MCU & Secondary-MCU Both  Notavailable";
VAL_ 266 EPB_ClampForce_Secondary 0 "ClampForce" 30 "Reserved" 31 "Error";
VAL_ 266 EPB_FailStatus_Secondary 0 "No error" 1 "Not defined" 2 "Not defined" 3 "error";
VAL_ 266 EPB_Status_Secondary 0 "released" 1 " ParkedApplied" 2 "releasing" 3 " Locking" 4 "unknown" 5 "HoldApplied" 6 " CompletelyReleased" 7 "HapPrepared";
VAL_ 266 EpbCdpReq 0 "Not request" 1 "Request";
VAL_ 266 EPB_EAR_Available 0 "Not available" 1 "available";
VAL_ 266 EPB_Status_Priamary 0 "released" 1 " ParkedApplied" 2 "releasing" 3 "Locking" 4 "unknown" 5 "HoldApplied" 6 " CompletelyReleased" 7 "HapPrepared";
VAL_ 266 EPB_FailStatus_Primary 0 "No error" 1 "Not defined" 2 "Not defined" 3 "error";
VAL_ 266 ESP_RWU_ParkingAvailForACC 0 "Available" 1 "not available";
VAL_ 266 ESP_RWU_ParkingActiveForACC 0 "Active" 1 "not Active";
VAL_ 266 EPB_TextDisplay 0 "Notextmessage" 1 "Gradienttoohigh" 2 "Clampforcenotenough" 3 "Fastenseatbelt" 4 "Openparkbrakebyswitch" 5 "Pressbrakepedal" 6 "Vehicle Speed too high" 7 "DynPrkgActived" 8 "Release EPB by shiftt" 9 "P-gear button
malfunction, if need park
through the HU EPB
switch" 10 "parking system
malfunction,please check
and repair" 11 "reserved" 12 "reserved" 13 "reserved" 14 "reserved" 15 "Invalid";
VAL_ 266 EPB_SwitchPositionValid 0 "valid _full function" 1 "error, init or substitute value (no function)";
VAL_ 266 EPB_SwitchPosition 0 "no request" 1 "Release request" 2 "Apply request" 3 "Error";
VAL_ 266 EPB_Status 0 "both brakes released" 1 "both brakes applied" 2 "both brakes in operation (applying/releasing)" 3 "unknown";
VAL_ 266 EPB_FunctionLamp 0 "LampOFF" 1 "LampON" 2 "flash" 3 "Invalid";
VAL_ 266 EPB_FailureLamp 0 "LampOFF" 1 "LampON" 2 "flash" 3 "Invalid";
VAL_ 266 EPB_FailStatus 0 "no error in EPB ¨C external apply available" 1 "not defined" 2 "not defined" 3 "error in EPB ¨C no external apply allowed";
VAL_ 266 EPB_APArequest_Available 0 "notavailable" 1 "available";
VAL_ 266 EPB_AchievedClampForce 0 "ClampForce" 30 "Reserved" 31 "Error";

VAL_ 958 EDL_LockSts 0 "Unlock½âËø" 1 "LockËøÖ¹" 2 "Fault¹ÊÕÏ" 3 "Reserved";
VAL_ 958 ATS_TargetDrivingMode 0 " normal" 1 " snow£¨±ùÑ©£©" 2 " mud£¨ÄàµØ£©" 3 " sand£¨É³µØ£©" 4 " rock£¨ÑÒÊ¯£©" 5 " wade£¨ÉæË®£©" 6 " protect£¨±";

VAL_ 586 ESL_DriverParkButtonFaultStatus 0 "normal" 1 "Reserved" 2 "Fault" 3 "Reserved";
VAL_ 586 ESL_DriverParkRequest 0 " Driver Park Not Requested" 1 " Driver Park Requested" 2 "Reserved" 3 "Invalid";

VAL_ 810 TRM_ConnectSts 0 "NoConnected" 1 "Connected";

VAL_ 268 RMIPU_DMCCrtSts 0 "Initializing" 1 "not active" 2 "Dec active" 3 "Error" 4 "Inc active" 5 "Reserve";
VAL_ 268 TM1_MotSpdVld 1 "valid" 0 "Invalid";
VAL_ 268 TM1_MotTqRealVld 1 "valid" 0 "Invalid";
VAL_ 268 TM1_OperMdl 15 "ReadyToSleep" 14 "DisCharge" 13 "Failure" 10 "linkage" 9 "reserve" 8 "TrqCtl" 7 "ASC" 6 "nCtlExt" 5 "alOFFsetCal" 4 "UdcCtl" 3 "Standby" 1 "PreCharge" 0 "Initialization";

VAL_ 269 TM2_MotSpdVld 1 "valid" 0 "Invalid";
VAL_ 269 TM2_OperMdl 14 "DisCharge" 13 "Failure" 10 "linkage" 9 "reserve" 8 "TrqCtl" 6 "nCtlExt" 5 "alOFFsetCal" 4 "UdcCtl" 3 "Standby" 1 "PreCharge" 0 "Initialization";
VAL_ 269 TM2_MotTqRealVld 1 "valid" 0 "Invalid";

VAL_ 1341 HU_Poweroff 0 " Inactive" 1 " Normal Off";

VAL_ 842 HU_TankTurnStatusSetReq 0 "Inactive" 1 "Off" 2 "Snow" 3 "Grassland" 4 "Sandstone" 5 "Reserved" 6 "Error";

VAL_ 519 PCU_IDCSAvlSts 0 "Not available" 1 "available";

VAL_ 977 PCU_CruiseCtrlSts 0 "OFF" 1 "ACTIVE" 2 "STANDBY" 3 "ERROR";

VAL_ 574 EspSysSts 0 "NotInitialized" 1 "nomal" 2 "postrun" 3 "Ô¤Áô";
VAL_ 574 IBCU_MotCtrlType 0 " Off" 1 " Torq" 2 " Position" 3 " Speed";
VAL_ 574 IBCU_IdleCtrlType 0 "BackUp" 1 "Pressure" 2 "Position" 3 "PostRun" 4 "Leakege" 5 "Reserved";
VAL_ 574 IBCU_CtrlMode 0 "Backup" 1 "Diagnosis" 2 "IdleCtrl" 3 "Standby" 4 "ActiveBluidPressure" 5 "PRL" 6 "Test" 7 "MotTempStop" 8 "Reserved";

VAL_ 691 HU_ESPStatusSetReq1 0 "Inactive" 1 "ESP Height" 2 "ESP Medium" 3 "ESP Low";
VAL_ 691 HU_ElectrodelessBrakeModeSetStatus2 0 "inactive" 1 "1%-100%" 101 "Reserved" 255 "Invalid";
VAL_ 691 HU_BDCSwtSet 0 "no request" 1 "Off" 2 "On" 3 "Reserved";
VAL_ 691 HU_iDCSLevel 0 "no request" 1 "Level 1" 2 "Level 2" 3 "Level 3" 4 "Reserved";
VAL_ 691 HU_iDCS_Switch_Status 0 "no request" 1 "Off" 2 "On" 3 "Reserved";

VAL_ 773 BMS_PackSwitchSts 0 "Î´»»µç" 1 "»»µç×¼±¸" 2 "»»µçÖÐ" 3 "»»µçÍê³É" 4 "»»µçÊ§°Ü" 5 "³µÁ¾ÈÏÖ¤" 6 "";
